VERSION ""

NS_ :

BS_:

BU_: PC PUMPOT DC_DC2 DC_DC1 TTC_30 IMU CANoeSpy MBMS VCU VCVCCU CBCU TMS

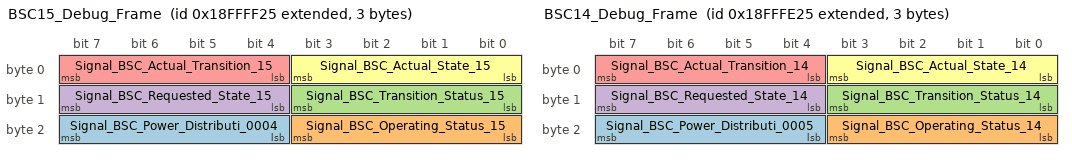
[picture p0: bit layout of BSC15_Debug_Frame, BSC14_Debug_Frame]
BO_ 2566913829 BSC15_Debug_Frame: 3 MBMS
 SG_ Signal_BSC_Power_Distributi_0004 : 20|4@1+ (1,0) [0|0] "" Vector__XXX
 SG_ Signal_BSC_Operating_Status_15 : 16|4@1+ (1,0) [0|0] "" Vector__XXX
 SG_ Signal_BSC_Transition_Status_15 : 8|4@1+ (1,0) [0|0] "" Vector__XXX
 SG_ Signal_BSC_Requested_State_15 : 12|4@1+ (1,0) [0|0] "" Vector__XXX
 SG_ Signal_BSC_Actual_Transition_15 : 4|4@1+ (1,0) [0|0] "" Vector__XXX
 SG_ Signal_BSC_Actual_State_15 : 0|4@1+ (1,0) [0|0] "" Vector__XXX

BO_ 2566913573 BSC14_Debug_Frame: 3 MBMS
 SG_ Signal_BSC_Power_Distributi_0005 : 20|4@1+ (1,0) [0|0] "" Vector__XXX
 SG_ Signal_BSC_Operating_Status_14 : 16|4@1+ (1,0) [0|0] "" Vector__XXX
 SG_ Signal_BSC_Transition_Status_14 : 8|4@1+ (1,0) [0|0] "" Vector__XXX
 SG_ Signal_BSC_Requested_State_14 : 12|4@1+ (1,0) [0|0] "" Vector__XXX
 SG_ Signal_BSC_Actual_Transition_14 : 4|4@1+ (1,0) [0|0] "" Vector__XXX
 SG_ Signal_BSC_Actual_State_14 : 0|4@1+ (1,0) [0|0] "" Vector__XXX

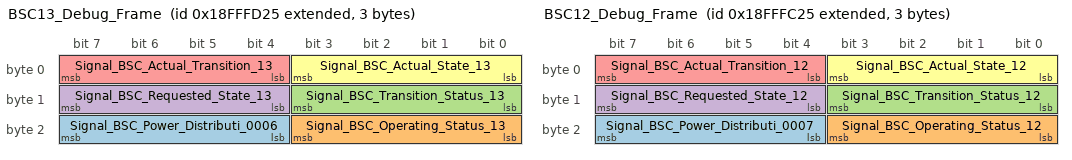
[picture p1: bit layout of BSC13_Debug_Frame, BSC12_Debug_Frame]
BO_ 2566913317 BSC13_Debug_Frame: 3 MBMS
 SG_ Signal_BSC_Power_Distributi_0006 : 20|4@1+ (1,0) [0|0] "" Vector__XXX
 SG_ Signal_BSC_Operating_Status_13 : 16|4@1+ (1,0) [0|0] "" Vector__XXX
 SG_ Signal_BSC_Transition_Status_13 : 8|4@1+ (1,0) [0|0] "" Vector__XXX
 SG_ Signal_BSC_Requested_State_13 : 12|4@1+ (1,0) [0|0] "" Vector__XXX
 SG_ Signal_BSC_Actual_Transition_13 : 4|4@1+ (1,0) [0|0] "" Vector__XXX
 SG_ Signal_BSC_Actual_State_13 : 0|4@1+ (1,0) [0|0] "" Vector__XXX

BO_ 2566913061 BSC12_Debug_Frame: 3 MBMS
 SG_ Signal_BSC_Power_Distributi_0007 : 20|4@1+ (1,0) [0|0] "" Vector__XXX
 SG_ Signal_BSC_Operating_Status_12 : 16|4@1+ (1,0) [0|0] "" Vector__XXX
 SG_ Signal_BSC_Transition_Status_12 : 8|4@1+ (1,0) [0|0] "" Vector__XXX
 SG_ Signal_BSC_Requested_State_12 : 12|4@1+ (1,0) [0|0] "" Vector__XXX
 SG_ Signal_BSC_Actual_Transition_12 : 4|4@1+ (1,0) [0|0] "" Vector__XXX
 SG_ Signal_BSC_Actual_State_12 : 0|4@1+ (1,0) [0|0] "" Vector__XXX

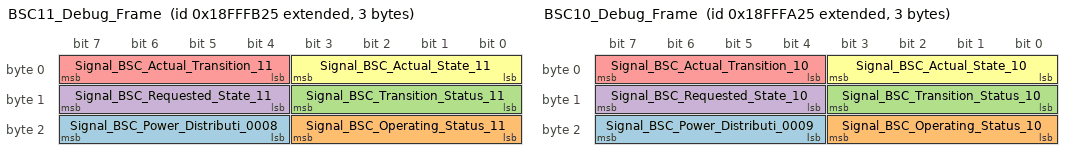
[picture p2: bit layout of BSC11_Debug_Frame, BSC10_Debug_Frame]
BO_ 2566912805 BSC11_Debug_Frame: 3 MBMS
 SG_ Signal_BSC_Power_Distributi_0008 : 20|4@1+ (1,0) [0|0] "" Vector__XXX
 SG_ Signal_BSC_Operating_Status_11 : 16|4@1+ (1,0) [0|0] "" Vector__XXX
 SG_ Signal_BSC_Transition_Status_11 : 8|4@1+ (1,0) [0|0] "" Vector__XXX
 SG_ Signal_BSC_Requested_State_11 : 12|4@1+ (1,0) [0|0] "" Vector__XXX
 SG_ Signal_BSC_Actual_Transition_11 : 4|4@1+ (1,0) [0|0] "" Vector__XXX
 SG_ Signal_BSC_Actual_State_11 : 0|4@1+ (1,0) [0|0] "" Vector__XXX

BO_ 2566912549 BSC10_Debug_Frame: 3 MBMS
 SG_ Signal_BSC_Power_Distributi_0009 : 20|4@1+ (1,0) [0|0] "" Vector__XXX
 SG_ Signal_BSC_Operating_Status_10 : 16|4@1+ (1,0) [0|0] "" Vector__XXX
 SG_ Signal_BSC_Transition_Status_10 : 8|4@1+ (1,0) [0|0] "" Vector__XXX
 SG_ Signal_BSC_Requested_State_10 : 12|4@1+ (1,0) [0|0] "" Vector__XXX
 SG_ Signal_BSC_Actual_Transition_10 : 4|4@1+ (1,0) [0|0] "" Vector__XXX
 SG_ Signal_BSC_Actual_State_10 : 0|4@1+ (1,0) [0|0] "" Vector__XXX

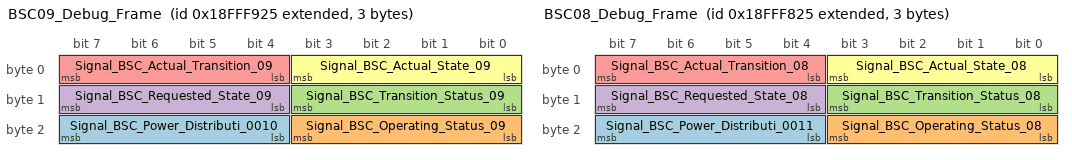
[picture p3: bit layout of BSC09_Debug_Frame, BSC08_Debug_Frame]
BO_ 2566912293 BSC09_Debug_Frame: 3 MBMS
 SG_ Signal_BSC_Power_Distributi_0010 : 20|4@1+ (1,0) [0|0] "" Vector__XXX
 SG_ Signal_BSC_Operating_Status_09 : 16|4@1+ (1,0) [0|0] "" Vector__XXX
 SG_ Signal_BSC_Transition_Status_09 : 8|4@1+ (1,0) [0|0] "" Vector__XXX
 SG_ Signal_BSC_Requested_State_09 : 12|4@1+ (1,0) [0|0] "" Vector__XXX
 SG_ Signal_BSC_Actual_Transition_09 : 4|4@1+ (1,0) [0|0] "" Vector__XXX
 SG_ Signal_BSC_Actual_State_09 : 0|4@1+ (1,0) [0|0] "" Vector__XXX

BO_ 2566912037 BSC08_Debug_Frame: 3 MBMS
 SG_ Signal_BSC_Power_Distributi_0011 : 20|4@1+ (1,0) [0|0] "" Vector__XXX
 SG_ Signal_BSC_Operating_Status_08 : 16|4@1+ (1,0) [0|0] "" Vector__XXX
 SG_ Signal_BSC_Transition_Status_08 : 8|4@1+ (1,0) [0|0] "" Vector__XXX
 SG_ Signal_BSC_Requested_State_08 : 12|4@1+ (1,0) [0|0] "" Vector__XXX
 SG_ Signal_BSC_Actual_Transition_08 : 4|4@1+ (1,0) [0|0] "" Vector__XXX
 SG_ Signal_BSC_Actual_State_08 : 0|4@1+ (1,0) [0|0] "" Vector__XXX

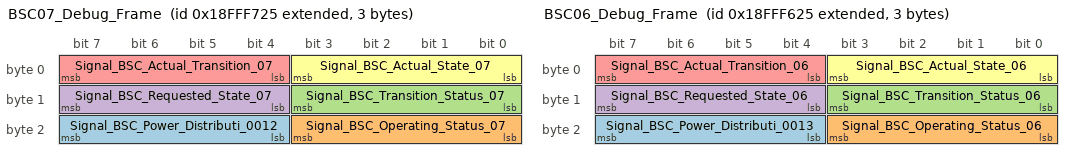
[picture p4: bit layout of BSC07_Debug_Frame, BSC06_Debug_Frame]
BO_ 2566911781 BSC07_Debug_Frame: 3 MBMS
 SG_ Signal_BSC_Power_Distributi_0012 : 20|4@1+ (1,0) [0|0] "" Vector__XXX
 SG_ Signal_BSC_Operating_Status_07 : 16|4@1+ (1,0) [0|0] "" Vector__XXX
 SG_ Signal_BSC_Transition_Status_07 : 8|4@1+ (1,0) [0|0] "" Vector__XXX
 SG_ Signal_BSC_Requested_State_07 : 12|4@1+ (1,0) [0|0] "" Vector__XXX
 SG_ Signal_BSC_Actual_Transition_07 : 4|4@1+ (1,0) [0|0] "" Vector__XXX
 SG_ Signal_BSC_Actual_State_07 : 0|4@1+ (1,0) [0|0] "" Vector__XXX

BO_ 2566911525 BSC06_Debug_Frame: 3 MBMS
 SG_ Signal_BSC_Power_Distributi_0013 : 20|4@1+ (1,0) [0|0] "" Vector__XXX
 SG_ Signal_BSC_Operating_Status_06 : 16|4@1+ (1,0) [0|0] "" Vector__XXX
 SG_ Signal_BSC_Transition_Status_06 : 8|4@1+ (1,0) [0|0] "" Vector__XXX
 SG_ Signal_BSC_Requested_State_06 : 12|4@1+ (1,0) [0|0] "" Vector__XXX
 SG_ Signal_BSC_Actual_Transition_06 : 4|4@1+ (1,0) [0|0] "" Vector__XXX
 SG_ Signal_BSC_Actual_State_06 : 0|4@1+ (1,0) [0|0] "" Vector__XXX

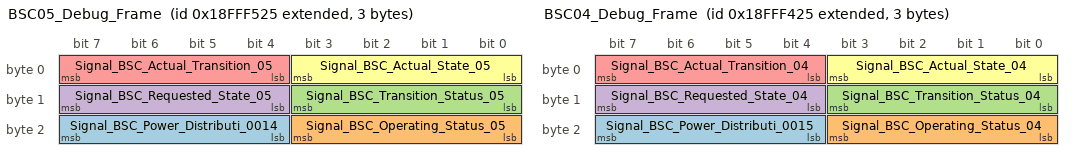
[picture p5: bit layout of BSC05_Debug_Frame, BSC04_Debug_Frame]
BO_ 2566911269 BSC05_Debug_Frame: 3 MBMS
 SG_ Signal_BSC_Power_Distributi_0014 : 20|4@1+ (1,0) [0|0] "" Vector__XXX
 SG_ Signal_BSC_Operating_Status_05 : 16|4@1+ (1,0) [0|0] "" Vector__XXX
 SG_ Signal_BSC_Transition_Status_05 : 8|4@1+ (1,0) [0|0] "" Vector__XXX
 SG_ Signal_BSC_Requested_State_05 : 12|4@1+ (1,0) [0|0] "" Vector__XXX
 SG_ Signal_BSC_Actual_Transition_05 : 4|4@1+ (1,0) [0|0] "" Vector__XXX
 SG_ Signal_BSC_Actual_State_05 : 0|4@1+ (1,0) [0|0] "" Vector__XXX

BO_ 2566911013 BSC04_Debug_Frame: 3 MBMS
 SG_ Signal_BSC_Power_Distributi_0015 : 20|4@1+ (1,0) [0|0] "" Vector__XXX
 SG_ Signal_BSC_Operating_Status_04 : 16|4@1+ (1,0) [0|0] "" Vector__XXX
 SG_ Signal_BSC_Transition_Status_04 : 8|4@1+ (1,0) [0|0] "" Vector__XXX
 SG_ Signal_BSC_Requested_State_04 : 12|4@1+ (1,0) [0|0] "" Vector__XXX
 SG_ Signal_BSC_Actual_Transition_04 : 4|4@1+ (1,0) [0|0] "" Vector__XXX
 SG_ Signal_BSC_Actual_State_04 : 0|4@1+ (1,0) [0|0] "" Vector__XXX

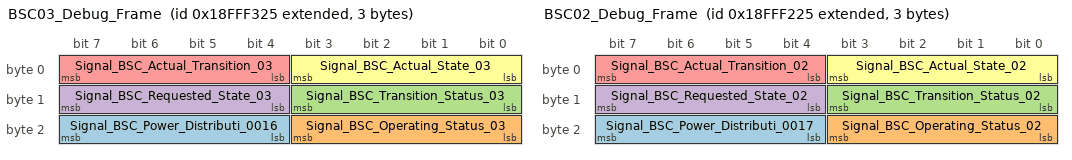
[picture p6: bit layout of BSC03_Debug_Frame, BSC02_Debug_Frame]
BO_ 2566910757 BSC03_Debug_Frame: 3 MBMS
 SG_ Signal_BSC_Power_Distributi_0016 : 20|4@1+ (1,0) [0|0] "" Vector__XXX
 SG_ Signal_BSC_Operating_Status_03 : 16|4@1+ (1,0) [0|0] "" Vector__XXX
 SG_ Signal_BSC_Transition_Status_03 : 8|4@1+ (1,0) [0|0] "" Vector__XXX
 SG_ Signal_BSC_Requested_State_03 : 12|4@1+ (1,0) [0|0] "" Vector__XXX
 SG_ Signal_BSC_Actual_Transition_03 : 4|4@1+ (1,0) [0|0] "" Vector__XXX
 SG_ Signal_BSC_Actual_State_03 : 0|4@1+ (1,0) [0|0] "" Vector__XXX

BO_ 2566910501 BSC02_Debug_Frame: 3 MBMS
 SG_ Signal_BSC_Power_Distributi_0017 : 20|4@1+ (1,0) [0|0] "" Vector__XXX
 SG_ Signal_BSC_Operating_Status_02 : 16|4@1+ (1,0) [0|0] "" Vector__XXX
 SG_ Signal_BSC_Transition_Status_02 : 8|4@1+ (1,0) [0|0] "" Vector__XXX
 SG_ Signal_BSC_Requested_State_02 : 12|4@1+ (1,0) [0|0] "" Vector__XXX
 SG_ Signal_BSC_Actual_Transition_02 : 4|4@1+ (1,0) [0|0] "" Vector__XXX
 SG_ Signal_BSC_Actual_State_02 : 0|4@1+ (1,0) [0|0] "" Vector__XXX

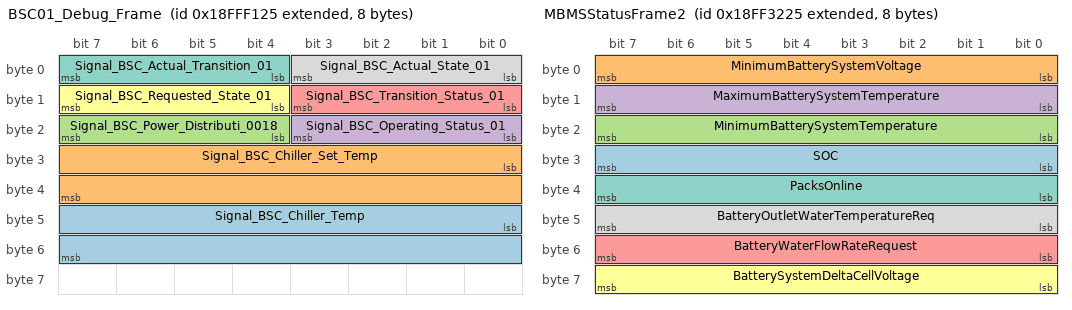
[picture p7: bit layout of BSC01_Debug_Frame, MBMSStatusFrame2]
BO_ 2566910245 BSC01_Debug_Frame: 8 MBMS
 SG_ Signal_BSC_Chiller_Temp : 40|16@1+ (1,0) [0|0] "" Vector__XXX
 SG_ Signal_BSC_Chiller_Set_Temp : 24|16@1+ (1,0) [0|0] "" Vector__XXX
 SG_ Signal_BSC_Power_Distributi_0018 : 20|4@1+ (1,0) [0|0] "" Vector__XXX
 SG_ Signal_BSC_Operating_Status_01 : 16|4@1+ (1,0) [0|0] "" Vector__XXX
 SG_ Signal_BSC_Transition_Status_01 : 8|4@1+ (1,0) [0|0] "" Vector__XXX
 SG_ Signal_BSC_Requested_State_01 : 12|4@1+ (1,0) [0|0] "" Vector__XXX
 SG_ Signal_BSC_Actual_Transition_01 : 4|4@1+ (1,0) [0|0] "" Vector__XXX
 SG_ Signal_BSC_Actual_State_01 : 0|4@1+ (1,0) [0|0] "" Vector__XXX

BO_ 2566861349 MBMSStatusFrame2: 8 MBMS
 SG_ SOC : 24|8@1+ (0.4,0) [0|100] "%" Vector__XXX
 SG_ MinimumBatterySystemVoltage : 0|8@1+ (3.4,0) [0|850] "V" Vector__XXX
 SG_ MinimumBatterySystemTemperature : 16|8@1+ (1,-40) [-40|210] "°C" Vector__XXX
 SG_ MaximumBatterySystemTemperature : 8|8@1+ (1,-40) [-40|210] "°C" Vector__XXX
 SG_ BatteryWaterFlowRateRequest : 48|8@1+ (50,0) [0|12500] "l/h" Vector__XXX
 SG_ BatterySystemDeltaCellVoltage : 56|8@1+ (10,0) [0|2500] "mV" Vector__XXX
 SG_ PacksOnline : 32|8@1+ (1,0) [0|250] "" Vector__XXX
 SG_ BatteryOutletWaterTemperatureReq : 40|8@1+ (1,-40) [-40|210] "°C" Vector__XXX

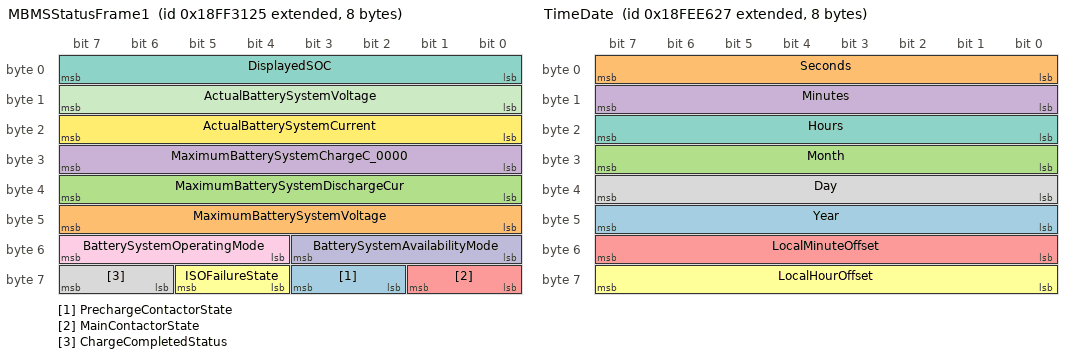
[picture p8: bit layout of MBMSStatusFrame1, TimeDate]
BO_ 2566861093 MBMSStatusFrame1: 8 MBMS
 SG_ PrechargeContactorState : 58|2@1+ (1,0) [0|0] "" Vector__XXX
 SG_ MaximumBatterySystemVoltage : 40|8@1+ (3.4,0) [0|850] "V" Vector__XXX
 SG_ MaximumBatterySystemDischargeCur : 32|8@1+ (2,0) [0|510] "A" Vector__XXX
 SG_ MaximumBatterySystemChargeC_0000 : 24|8@1+ (2,0) [0|510] "A" Vector__XXX
 SG_ MainContactorState : 56|2@1+ (1,0) [0|0] "" Vector__XXX
 SG_ ISOFailureState : 60|2@1+ (1,0) [0|0] "" Vector__XXX
 SG_ DisplayedSOC : 0|8@1+ (0.4,0) [0|100] "%" Vector__XXX
 SG_ ChargeCompletedStatus : 62|2@1+ (1,0) [0|0] "" Vector__XXX
 SG_ BatterySystemOperatingMode : 52|4@1+ (1,0) [0|0] "" Vector__XXX
 SG_ BatterySystemAvailabilityMode : 48|4@1+ (1,0) [0|0] "" Vector__XXX
 SG_ ActualBatterySystemVoltage : 8|8@1+ (3.4,0) [0|850] "V" Vector__XXX
 SG_ ActualBatterySystemCurrent : 16|8@1+ (4,-500) [-500|500] "A" Vector__XXX

BO_ 2566832423 HighResVehicleDistance: 8 Vector__XXX
 SG_ HighResTripDistance : 32|32@1+ (0.005,0) [0|21055406] ""  MBMS
 SG_ HighResTotalVehicleDistance : 0|32@1+ (0.005,0) [0|21055406] ""  MBMS

BO_ 2566841895 TimeDate: 8 Vector__XXX
 SG_ Year : 40|8@1+ (1,0) [0|250] ""  MBMS
 SG_ Seconds : 0|8@1+ (0.25,0) [0|62.5] ""  MBMS
 SG_ Month : 24|8@1+ (1,0) [0|250] ""  MBMS
 SG_ Minutes : 8|8@1+ (1,0) [0|250] ""  MBMS
 SG_ LocalMinuteOffset : 48|8@1+ (1,-125) [-125|130] ""  MBMS
 SG_ LocalHourOffset : 56|8@1+ (1,-125) [-125|130] ""  MBMS
 SG_ Hours : 16|8@1+ (1,0) [0|250] ""  MBMS
 SG_ Day : 32|8@1+ (0.25,0) [0|62.5] ""  MBMS

BO_ 2566856487 SCU2MBMS: 3 Vector__XXX
 SG_ PrechargeContactor : 0|2@1+ (1,0) [0|0] ""  MBMS
 SG_ MaxChargePower : 8|16@1+ (0.01,0) [0|655.35] "kW"  MBMS
 SG_ MainContactor : 2|2@1+ (1,0) [0|0] ""  MBMS

BO_ 2364609638 DCDC2VC: 8 DC_DC2
 SG_ HiSideCur : 48|16@1+ (0.1,-3212.7) [-3212.7|3212.8] "A" Vector__XXX
 SG_ HiSideV : 32|16@1+ (0.05,0) [0|3212.75] "V" Vector__XXX
 SG_ LowSideCur : 16|16@1+ (0.1,-3212.7) [-3212.7|3212.8] "A" Vector__XXX
 SG_ LowSideV : 0|16@1+ (0.01,0) [0|642.55] "V" Vector__XXX

BO_ 2365297510 DCDC2V: 8 DC_DC2
 SG_ OneCtrlInputSLIV : 16|16@1+ (0.05,0) [0|3212.75] "V" Vector__XXX
 SG_ OneCtrlInputIgntV : 0|16@1+ (0.05,0) [0|3212.75] "V" Vector__XXX

BO_ 2365315174 DCDC2T: 8 DC_DC2
 SG_ OneCoolantOutTemp : 32|8@1+ (1,-40) [-40|210] "°C" Vector__XXX
 SG_ OneCoolantInTemp : 24|8@1+ (1,-40) [-40|210] "°C" Vector__XXX
 SG_ PwrETemp : 16|8@1+ (1,-40) [-40|210] "°C" Vector__XXX
 SG_ ElectronicFilterTemp : 8|8@1+ (1,-40) [-40|210] "°C" Vector__XXX
 SG_ Temp : 0|8@1+ (1,-40) [-40|210] "°C" Vector__XXX

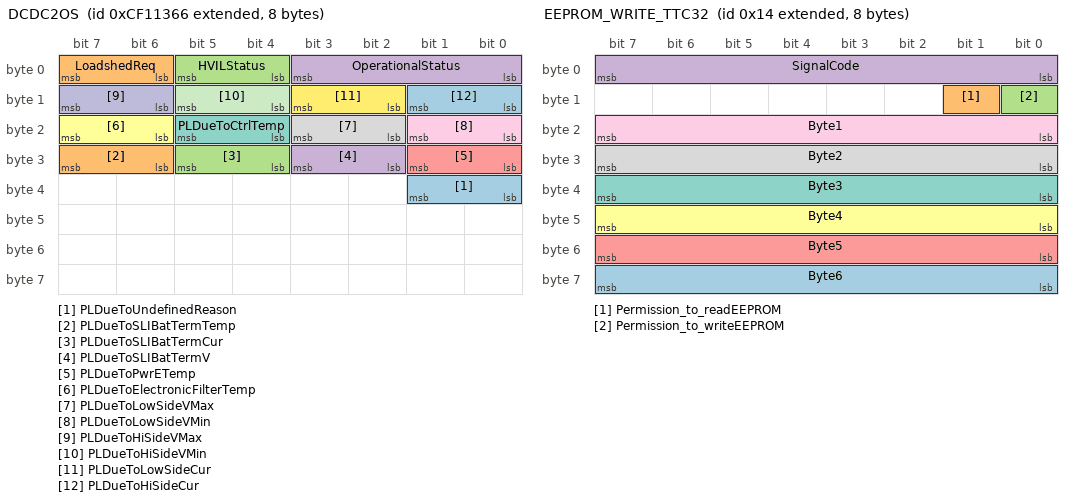
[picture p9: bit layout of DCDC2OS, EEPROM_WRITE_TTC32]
BO_ 2364609382 DCDC2OS: 8 DC_DC2
 SG_ PLDueToUndefinedReason : 32|2@1+ (1,0) [0|3] "" Vector__XXX
 SG_ PLDueToSLIBatTermTemp : 30|2@1+ (1,0) [0|3] "" Vector__XXX
 SG_ PLDueToSLIBatTermCur : 28|2@1+ (1,0) [0|3] "" Vector__XXX
 SG_ PLDueToSLIBatTermV : 26|2@1+ (1,0) [0|3] "" Vector__XXX
 SG_ PLDueToPwrETemp : 24|2@1+ (1,0) [0|3] "" Vector__XXX
 SG_ PLDueToElectronicFilterTemp : 22|2@1+ (1,0) [0|3] "" Vector__XXX
 SG_ PLDueToCtrlTemp : 20|2@1+ (1,0) [0|3] "" Vector__XXX
 SG_ PLDueToLowSideVMax : 18|2@1+ (1,0) [0|3] "" Vector__XXX
 SG_ PLDueToLowSideVMin : 16|2@1+ (1,0) [0|3] "" Vector__XXX
 SG_ PLDueToHiSideVMax : 14|2@1+ (1,0) [0|3] "" Vector__XXX
 SG_ PLDueToHiSideVMin : 12|2@1+ (1,0) [0|3] "" Vector__XXX
 SG_ PLDueToLowSideCur : 10|2@1+ (1,0) [0|3] "" Vector__XXX
 SG_ PLDueToHiSideCur : 8|2@1+ (1,0) [0|3] "" Vector__XXX
 SG_ LoadshedReq : 6|2@1+ (1,0) [0|3] "" Vector__XXX
 SG_ HVILStatus : 4|2@1+ (1,0) [0|3] "" Vector__XXX
 SG_ OperationalStatus : 0|4@1+ (1,0) [0|15] "" Vector__XXX

BO_ 2365315430 DCDC2LL: 8 DC_DC2
 SG_ LowSideCurMaxLmt : 32|16@1+ (0.05,0) [0|3212.75] "A" Vector__XXX
 SG_ LowSideVMaxLmt : 16|16@1+ (0.01,0) [0|642.55] "V" Vector__XXX
 SG_ LowSideVMinLmt : 0|16@1+ (0.01,0) [0|642.55] "V" Vector__XXX

BO_ 2348941054 Pant_current: 8 TTC_30
 SG_ Datchik_toka : 0|16@1+ (0.005,0) [0|0] "" Vector__XXX

BO_ 2147483800 EEPROM_WRITE_TTC32_2byte: 4 Vector__XXX
 SG_ Permission_to_readEEPROM : 9|1@1+ (1,0) [0|0] "" Vector__XXX
 SG_ Permission_to_writeEEPROM : 8|1@1+ (1,0) [0|0] "" Vector__XXX
 SG_ SignalCode : 0|8@1+ (1,0) [0|0] "" Vector__XXX
 SG_ Byte2 : 24|8@1+ (1,0) [0|0] "" Vector__XXX
 SG_ Byte1 : 16|8@1+ (1,0) [0|0] "" Vector__XXX

BO_ 2147483801 EEPROM_WRITE_TTC32_1byte: 3 Vector__XXX
 SG_ Permission_to_readEEPROM : 9|1@1+ (1,0) [0|0] "" Vector__XXX
 SG_ Permission_to_writeEEPROM : 8|1@1+ (1,0) [0|0] "" Vector__XXX
 SG_ SignalCode : 0|8@1+ (1,0) [0|0] "" Vector__XXX
 SG_ Byte1 : 16|8@1+ (1,0) [0|0] "" Vector__XXX

BO_ 2147483682 EEPROM_Global_values2_TTC32: 8 Vector__XXX
 SG_ var11 : 32|8@1+ (1,0) [0|0] "" Vector__XXX
 SG_ Idle_stop_circuit2_variable : 24|8@1+ (1,0) [0|0] "" Vector__XXX
 SG_ var8 : 16|8@1+ (1,0) [0|0] "" Vector__XXX
 SG_ var7 : 0|16@1+ (1,0) [0|0] "" Vector__XXX

BO_ 2147483681 EEPROM_Global_values1_TTC32: 8 Vector__XXX
 SG_ Idle_stop_circuit1_variable : 56|8@1+ (1,0) [0|0] "" Vector__XXX
 SG_ var6 : 32|24@1+ (1,0) [0|0] "" Vector__XXX
 SG_ saturation1_min_variable : 24|8@1+ (1,0) [0|0] "" Vector__XXX
 SG_ saturation2_min_variable : 16|8@1+ (1,0) [0|0] "" Vector__XXX
 SG_ saturation1_max_variable : 8|8@1+ (1,0) [0|0] "" Vector__XXX
 SG_ saturation2_max_variable : 0|8@1+ (1,0) [0|0] "" Vector__XXX

BO_ 2147483668 EEPROM_WRITE_TTC32: 8 Vector__XXX
 SG_ Byte6 : 56|8@1+ (1,0) [0|0] "" Vector__XXX
 SG_ Permission_to_readEEPROM : 9|1@1+ (1,0) [0|0] "" Vector__XXX
 SG_ Permission_to_writeEEPROM : 8|1@1+ (1,0) [0|0] "" Vector__XXX
 SG_ SignalCode : 0|8@1+ (1,0) [0|0] "" Vector__XXX
 SG_ Byte5 : 48|8@1+ (1,0) [0|0] "" Vector__XXX
 SG_ Byte4 : 40|8@1+ (1,0) [0|0] "" Vector__XXX
 SG_ Byte3 : 32|8@1+ (1,0) [0|0] "" Vector__XXX
 SG_ Byte2 : 24|8@1+ (1,0) [0|0] "" Vector__XXX
 SG_ Byte1 : 16|8@1+ (1,0) [0|0] "" Vector__XXX

BO_ 2147483667 EEPROM_Status_TTC32: 8 Vector__XXX
 SG_ bit10 : 9|1@1+ (1,0) [0|0] "" Vector__XXX
 SG_ bit11 : 10|1@1+ (1,0) [0|0] "" Vector__XXX
 SG_ bit12 : 11|1@1+ (1,0) [0|0] "" Vector__XXX
 SG_ bit13 : 12|1@1+ (1,0) [0|0] "" Vector__XXX
 SG_ bit14 : 13|1@1+ (1,0) [0|0] "" Vector__XXX
 SG_ bit15 : 14|1@1+ (1,0) [0|0] "" Vector__XXX
 SG_ bit16 : 15|1@1+ (1,0) [0|0] "" Vector__XXX
 SG_ bit17 : 16|1@1+ (1,0) [0|0] "" Vector__XXX
 SG_ bit18 : 17|1@1+ (1,0) [0|0] "" Vector__XXX
 SG_ bit19 : 18|1@1+ (1,0) [0|0] "" Vector__XXX
 SG_ bit20 : 19|1@1+ (1,0) [0|0] "" Vector__XXX
 SG_ bit3 : 2|1@1+ (1,0) [0|0] "" Vector__XXX
 SG_ bit4 : 3|1@1+ (1,0) [0|0] "" Vector__XXX
 SG_ bit5 : 4|1@1+ (1,0) [0|0] "" Vector__XXX
 SG_ bit6 : 5|1@1+ (1,0) [0|0] "" Vector__XXX
 SG_ bit7 : 6|1@1+ (1,0) [0|0] "" Vector__XXX
 SG_ bit8 : 7|1@1+ (1,0) [0|0] "" Vector__XXX
 SG_ bit9 : 8|1@1+ (1,0) [0|0] "" Vector__XXX
 SG_ bit2 : 1|1@1+ (1,0) [0|0] "" Vector__XXX
 SG_ bit1 : 0|1@1+ (1,0) [0|0] "" Vector__XXX

BO_ 2566874233 EEPROM_Current_values2_TTC32: 8 Vector__XXX
 SG_ status : 0|8@1+ (1,0) [0|0] "" Vector__XXX
 SG_ DelayPantRising : 16|8@1+ (1,0) [0|0] "" Vector__XXX
 SG_ state : 8|8@1+ (1,0) [0|0] "" Vector__XXX

BO_ 2147483673 EEPROM_Current_values1_TTC32: 8 Vector__XXX
 SG_ SOC_Pant : 48|16@1+ (1,0) [0|0] "" Vector__XXX
 SG_ Down_Speed : 32|16@1+ (1,0) [0|0] "" Vector__XXX
 SG_ Up_Lim_beforeMid : 16|16@1+ (1,0) [0|0] "" Vector__XXX
 SG_ Up_Lim_afterMid : 0|16@1+ (1,0) [0|0] "" Vector__XXX

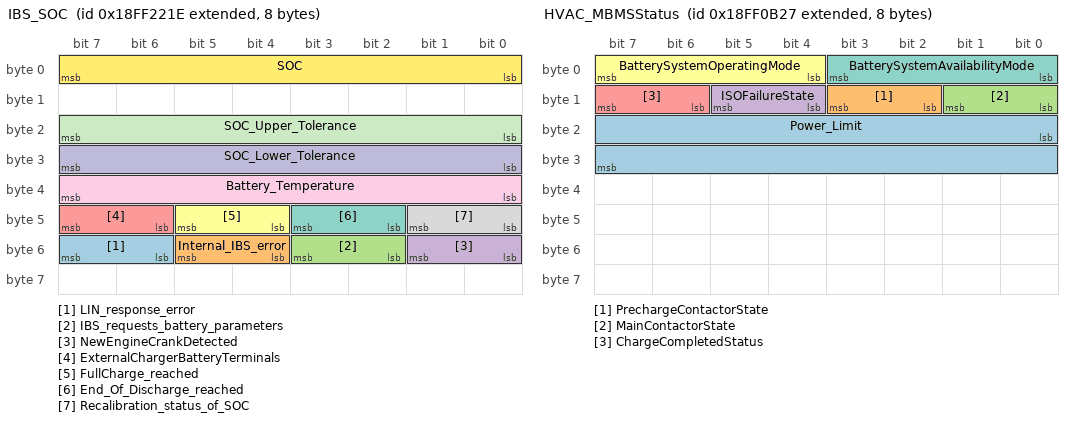
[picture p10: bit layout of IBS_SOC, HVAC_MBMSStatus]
BO_ 2566857246 IBS_SOC: 8 VCU
 SG_ LIN_response_error : 54|2@1+ (1,0) [0|0] ""  DC_DC2,DC_DC1
 SG_ Internal_IBS_error : 52|2@1+ (1,0) [0|0] ""  DC_DC2,DC_DC1
 SG_ IBS_requests_battery_parameters : 50|2@1+ (1,0) [0|0] ""  DC_DC2,DC_DC1
 SG_ NewEngineCrankDetected : 48|2@1+ (1,0) [0|0] ""  DC_DC2,DC_DC1
 SG_ ExternalChargerBatteryTerminals : 46|2@1+ (1,0) [0|0] ""  DC_DC2,DC_DC1
 SG_ FullCharge_reached : 44|2@1+ (1,0) [0|0] ""  DC_DC2,DC_DC1
 SG_ End_Of_Discharge_reached : 42|2@1+ (1,0) [0|0] ""  DC_DC2,DC_DC1
 SG_ Recalibration_status_of_SOC : 40|2@1+ (1,0) [0|0] ""  DC_DC2,DC_DC1
 SG_ Battery_Temperature : 32|8@1- (1,-40) [-40|0] ""  DC_DC2,DC_DC1
 SG_ SOC_Lower_Tolerance : 24|8@1+ (1,0) [0|0] ""  DC_DC2,DC_DC1
 SG_ SOC_Upper_Tolerance : 16|8@1+ (1,0) [0|0] ""  DC_DC2,DC_DC1
 SG_ SOC : 0|8@1+ (0.4,0) [0|100] "%"  DC_DC2,DC_DC1

BO_ 2566856990 IBS_Data: 8 VCU
 SG_ Current_measurement_range : 56|3@1+ (1,0) [0|0] ""  DC_DC2,DC_DC1
 SG_ NTC_Temperature : 48|8@1- (1,-40) [0|0] ""  DC_DC2,DC_DC1
 SG_ CentreTapVoltage : 32|16@1+ (0.001,0) [0|32] ""  DC_DC2,DC_DC1
 SG_ BatteryVoltage : 16|16@1+ (0.001,0) [0|32] ""  DC_DC2,DC_DC1
 SG_ BatteryCurrent : 0|16@1- (0.05,-1600) [-1600|1600] ""  DC_DC2,DC_DC1

BO_ 2365526823 DC_DC2_Limit: 8 VCU
 SG_ Low_Side_Cur_Buck_Def_Setpoint : 40|16@1+ (0.1,0) [0|6425.5] ""  DC_DC2
 SG_ Low_Side_Current_Buck_Setpoint : 8|16@1- (0.1,0) [0|6425.5] ""  DC_DC2
 SG_ Current_Limit : 24|16@1+ (0.1,0) [0|0] ""  DC_DC2

BO_ 2365526567 DC_DC1_Limit: 8 VCU
 SG_ Low_Side_Cur_Buck_Def_Setpoint : 40|16@1+ (0.1,0) [0|6425.5] ""  DC_DC1
 SG_ Low_Side_Current_Buck_Setpoint : 8|16@1- (0.1,0) [0|6425.5] ""  DC_DC1
 SG_ Current_Limit : 24|16@1+ (0.1,0) [0|0] ""  DC_DC1

BO_ 2566851367 HVAC_MBMSStatus: 8 VCU
 SG_ Power_Limit : 16|16@1+ (0.5,0) [0|0] "" Vector__XXX
 SG_ PrechargeContactorState : 10|2@1+ (1,0) [0|0] "" Vector__XXX
 SG_ MainContactorState : 8|2@1+ (1,0) [0|0] "" Vector__XXX
 SG_ ISOFailureState : 12|2@1+ (1,0) [0|0] "" Vector__XXX
 SG_ ChargeCompletedStatus : 14|2@1+ (1,0) [0|0] "" Vector__XXX
 SG_ BatterySystemOperatingMode : 4|4@1+ (1,0) [0|0] "" Vector__XXX
 SG_ BatterySystemAvailabilityMode : 0|4@1+ (1,0) [0|0] "" Vector__XXX

BO_ 2365297509 DCDC1V: 8 DC_DC1
 SG_ OneCtrlInputSLIV : 16|16@1+ (0.05,0) [0|3212.75] "V"  VCU
 SG_ OneCtrlInputIgntV : 0|16@1+ (0.05,0) [0|3212.75] "V"  VCU

BO_ 2364610599 DCDC2C: 8 VCU
 SG_ TwoLowSideVBuckDefaultSetpoint : 40|16@1+ (0.01,0) [0|642.55] "V"  DC_DC2
 SG_ TwoHiSideVBoostSetpoint : 24|16@1+ (0.05,0) [0|3212.75] "V"  DC_DC2
 SG_ TwoLowSideVBuckSetpoint : 8|16@1+ (0.01,0) [0|642.55] "V"  DC_DC2
 SG_ TwoOperationalCmd : 0|4@1+ (1,0) [0|15] ""  DC_DC2

BO_ 2365315429 DCDC1LL: 8 DC_DC1
 SG_ LowSideCurMaxLmt : 32|16@1+ (0.05,0) [0|3212.75] "A"  VCU
 SG_ LowSideVMaxLmt : 16|16@1+ (0.01,0) [0|642.55] "V"  VCU
 SG_ LowSideVMinLmt : 0|16@1+ (0.01,0) [0|642.55] "V"  VCU

BO_ 2365315173 DCDC1T: 8 DC_DC1
 SG_ OneCoolantOutTemp : 32|8@1+ (1,-40) [-40|210] "°C"  VCU
 SG_ OneCoolantInTemp : 24|8@1+ (1,-40) [-40|210] "°C"  VCU
 SG_ PwrETemp : 16|8@1+ (1,-40) [-40|210] "°C"  VCU
 SG_ ElectronicFilterTemp : 8|8@1+ (1,-40) [-40|210] "°C"  VCU
 SG_ Temp : 0|8@1+ (1,-40) [-40|210] "°C"  VCU

BO_ 2364609637 DCDC1VC: 8 DC_DC1
 SG_ HiSideCur : 48|16@1+ (0.1,-3212.7) [-3212.7|3212.8] "A"  VCU
 SG_ HiSideV : 32|16@1+ (0.05,0) [0|3212.75] "V"  VCU
 SG_ LowSideCur : 16|16@1+ (0.1,-3212.7) [-3212.7|3212.8] "A"  VCU
 SG_ LowSideV : 0|16@1+ (0.01,0) [0|642.55] "V"  VCU

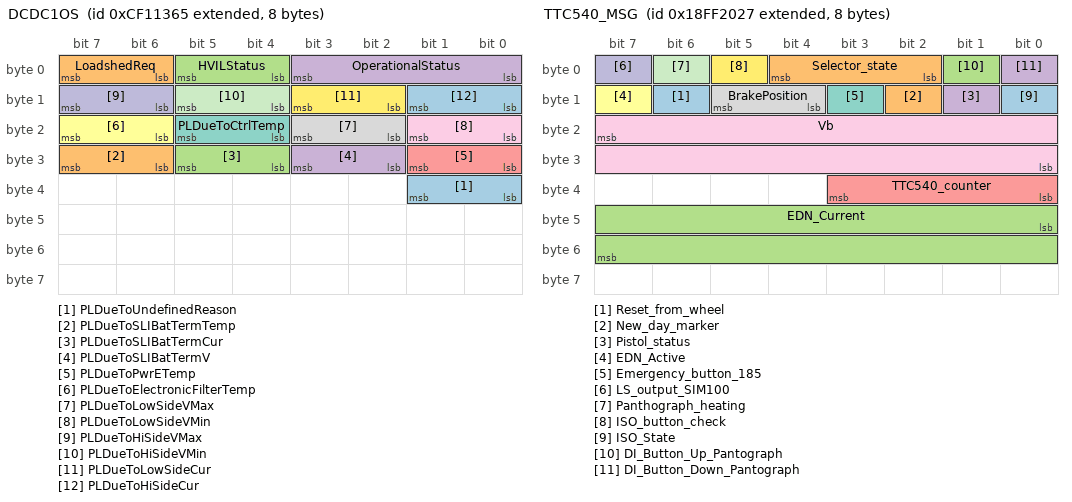
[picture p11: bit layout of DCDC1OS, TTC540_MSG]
BO_ 2364609381 DCDC1OS: 8 DC_DC1
 SG_ PLDueToUndefinedReason : 32|2@1+ (1,0) [0|3] ""  VCU
 SG_ PLDueToSLIBatTermTemp : 30|2@1+ (1,0) [0|3] ""  VCU
 SG_ PLDueToSLIBatTermCur : 28|2@1+ (1,0) [0|3] ""  VCU
 SG_ PLDueToSLIBatTermV : 26|2@1+ (1,0) [0|3] ""  VCU
 SG_ PLDueToPwrETemp : 24|2@1+ (1,0) [0|3] ""  VCU
 SG_ PLDueToElectronicFilterTemp : 22|2@1+ (1,0) [0|3] ""  VCU
 SG_ PLDueToCtrlTemp : 20|2@1+ (1,0) [0|3] ""  VCU
 SG_ PLDueToLowSideVMax : 18|2@1+ (1,0) [0|3] ""  VCU
 SG_ PLDueToLowSideVMin : 16|2@1+ (1,0) [0|3] ""  VCU
 SG_ PLDueToHiSideVMax : 14|2@1+ (1,0) [0|3] ""  VCU
 SG_ PLDueToHiSideVMin : 12|2@1+ (1,0) [0|3] ""  VCU
 SG_ PLDueToLowSideCur : 10|2@1+ (1,0) [0|3] ""  VCU
 SG_ PLDueToHiSideCur : 8|2@1+ (1,0) [0|3] ""  VCU
 SG_ LoadshedReq : 6|2@1+ (1,0) [0|3] ""  VCU
 SG_ HVILStatus : 4|2@1+ (1,0) [0|3] ""  VCU
 SG_ OperationalStatus : 0|4@1+ (1,0) [0|15] ""  VCU

BO_ 2364609063 DCDC1C: 8 VCU
 SG_ OneLowSideVBuckDefaultSetpoint : 40|16@1+ (0.01,0) [0|642.55] "V"  DC_DC1
 SG_ HiSideVBoostSetpoint : 24|16@1+ (0.05,0) [0|3212.75] "V"  DC_DC1
 SG_ LowSideVBuckSetpoint : 8|16@1+ (0.01,0) [0|642.55] "V"  DC_DC1
 SG_ OperationalCmd : 0|4@1+ (1,0) [0|15] ""  DC_DC1

BO_ 2566856743 TTC540_MSG: 8 VCU
 SG_ Reset_from_wheel : 14|1@1+ (1,0) [0|1] "" Vector__XXX
 SG_ New_day_marker : 10|1@1+ (1,0) [0|1] "" Vector__XXX
 SG_ EDN_Current : 40|16@1+ (0.1,0) [0|0] "" Vector__XXX
 SG_ Pistol_status : 9|1@1+ (1,0) [0|0] "" Vector__XXX
 SG_ TTC540_counter : 32|4@1+ (1,0) [0|0] "" Vector__XXX
 SG_ EDN_Active : 15|1@1+ (1,0) [0|0] "" Vector__XXX
 SG_ Emergency_button_185 : 11|1@1+ (1,0) [0|0] "" Vector__XXX
 SG_ BrakePosition : 12|2@1+ (1,0) [0|0] "" Vector__XXX
 SG_ Vb : 23|16@0+ (1,0) [0|0] "V" Vector__XXX
 SG_ LS_output_SIM100 : 7|1@1+ (1,0) [0|1] "" Vector__XXX
 SG_ Panthograph_heating : 6|1@1+ (1,0) [0|1] "" Vector__XXX
 SG_ ISO_button_check : 5|1@1+ (1,0) [0|0] "" Vector__XXX
 SG_ ISO_State : 8|1@1+ (1,0) [0|0] "" Vector__XXX
 SG_ Selector_state : 2|3@1+ (1,0) [0|0] "" Vector__XXX
 SG_ DI_Button_Up_Pantograph : 1|1@1+ (1,0) [0|1] ""  TTC_30
 SG_ DI_Button_Down_Pantograph : 0|1@1+ (1,0) [0|1] ""  TTC_30

BO_ 2566856723 TTC30_MSG: 8 TTC_30
 SG_ Power_charging_station : 48|16@1+ (1,0) [0|65535] "" Vector__XXX
 SG_ TTC30_counter : 44|4@1+ (1,0) [0|15] "" Vector__XXX
 SG_ UnderCoolant_HV_battery : 43|1@1+ (1,0) [0|0] "" Vector__XXX
 SG_ Charging_mode : 30|2@1+ (1,0) [0|0] "" Vector__XXX
 SG_ VCVCCU_Curr_demand : 42|1@1+ (1,0) [0|0] "" Vector__XXX
 SG_ VCVCCU_Vehicle_ContactorVoltage : 32|10@1+ (1,0) [0|1023] "V" Vector__XXX
 SG_ VC_VCCU_Connect : 0|1@1+ (1,0) [0|1] "" Vector__XXX
 SG_ Power_Ger : 1|1@1+ (1,0) [0|1] "" Vector__XXX
 SG_ Res_Chk_Stat : 7|1@1+ (1,0) [0|1] "" Vector__XXX
 SG_ Fbk_J2_PDU1_minus : 29|1@1+ (1,0) [0|1] "" Vector__XXX
 SG_ Fbk_K2_PDU1_plus : 28|1@1+ (1,0) [0|1] "" Vector__XXX
 SG_ Fbk_H2_HVIL : 27|1@1+ (1,0) [0|1] "" Vector__XXX
 SG_ Fbk_H4_PDU2_plus : 26|1@1+ (1,0) [0|255] "" Vector__XXX
 SG_ Fbk_G4_PDU2_Minus : 25|1@1+ (1,0) [0|1] "" Vector__XXX
 SG_ Fbk_F4_Discharge : 24|1@1+ (1,0) [0|1] "" Vector__XXX
 SG_ Voltage_PIN_A4 : 8|16@1+ (1,0) [0|65535] "" Vector__XXX
 SG_ DI_K2_Goes_down : 6|1@1+ (1,0) [0|1] ""  VCU
 SG_ DI_K1_Goes_up : 5|1@1+ (1,0) [0|1] ""  VCU
 SG_ Pantograph_DI_Top_Indicator : 4|1@1+ (1,0) [0|1] ""  VCU
 SG_ Pantograph_DI_Mid_Indicator : 3|1@1+ (1,0) [0|1] ""  VCU
 SG_ Pantograph_DI_Bottom_Indicator : 2|1@1+ (1,0) [0|1] ""  VCU

BO_ 2316304641 Request_from_Host: 5 VCU
 SG_ Restart m193 : 8|32@1+ (1,0) [0|0] "" Vector__XXX
 SG_ Excitation_pulse_off m98 : 8|32@1+ (1,0) [0|0] "" Vector__XXX
 SG_ Max_battery_working_voltage m240 : 15|16@0+ (1,0) [0|0] "V" Vector__XXX
 SG_ Request_mux M : 7|8@0+ (1,0) [0|0] "" Vector__XXX

BO_ 2316304640 SIM100_Report: 8 IMU
 SG_ Max_battery_working_voltage m240 : 15|16@0+ (1,0) [0|0] "V" Vector__XXX
 SG_ Temperature m128 : 15|32@0- (1,0) [0|0] "mCelsius" Vector__XXX
 SG_ Serial_number_3 m11 : 8|32@1+ (1,0) [0|0] "" Vector__XXX
 SG_ Serial_number_2 m10 : 8|32@1+ (1,0) [0|0] "" Vector__XXX
 SG_ Serial_number_1 m9 : 8|32@1+ (1,0) [0|0] "" Vector__XXX
 SG_ Serial_number_0 m8 : 8|32@1+ (1,0) [0|0] "" Vector__XXX
 SG_ Version_2 m7 : 8|32@1+ (1,0) [0|0] "" Vector__XXX
 SG_ Version_1 m6 : 8|32@1+ (1,0) [0|0] "" Vector__XXX
 SG_ Version_0 m5 : 8|32@1+ (1,0) [0|0] "" Vector__XXX
 SG_ Part_name_3 m4 : 8|32@1+ (1,0) [0|0] "" Vector__XXX
 SG_ Part_name_2 m3 : 8|32@1+ (1,0) [0|0] "" Vector__XXX
 SG_ Part_name_1 m2 : 8|32@1+ (1,0) [0|0] "" Vector__XXX
 SG_ Hardware_Error m224 : 15|1@0+ (1,0) [0|0] "" Vector__XXX
 SG_ Part_name_0 m1 : 8|32@1+ (1,0) [0|0] "" Vector__XXX
 SG_ Err_CH m229 : 21|1@0+ (1,0) [0|0] "" Vector__XXX
 SG_ No_New_Estimates m224 : 14|1@0+ (1,0) [0|0] "" Vector__XXX
 SG_ High_Uncertaintly m224 : 13|1@0+ (1,0) [0|0] "" Vector__XXX
 SG_ High_Battery_Voltage m224 : 11|1@0+ (1,0) [0|0] "" Vector__XXX
 SG_ Low_Battery_Voltage m224 : 10|1@0+ (1,0) [0|0] "" Vector__XXX
 SG_ Isolation_status_bits m224 : 9|2@0+ (1,0) [0|0] "" Vector__XXX
 SG_ Err_Vpwr m229 : 18|1@0+ (1,0) [0|0] "" Vector__XXX
 SG_ Err_Vexi m229 : 19|1@0+ (1,0) [0|0] "" Vector__XXX
 SG_ Err_VxR m229 : 20|1@0+ (1,0) [0|0] "" Vector__XXX
 SG_ Err_Vx1 m229 : 22|1@0+ (1,0) [0|0] "" Vector__XXX
 SG_ Err_Vx2 m229 : 23|1@0+ (1,0) [0|0] "" Vector__XXX
 SG_ Vb_max_uncertainty m228 : 63|8@0+ (1,0) [0|0] "%" Vector__XXX
 SG_ Vb_max m228 : 47|16@0+ (1,0) [0|0] "V" Vector__XXX
 SG_ Vb_uncertainty m228 : 39|8@0+ (1,0) [0|0] "%" Vector__XXX
 SG_ Vb m228 : 23|16@0+ (1,0) [0|0] "V" Vector__XXX
 SG_ Vn_uncertainty m227 : 63|8@0- (1,0) [0|0] "%" Vector__XXX
 SG_ Vn m227 : 47|16@0- (1,0) [0|0] "V" Vector__XXX
 SG_ Vp_uncertainty m227 : 39|8@0- (1,0) [0|0] "%" Vector__XXX
 SG_ Vp m227 : 23|16@0- (1,0) [0|0] "V" Vector__XXX
 SG_ Cn_uncertainty m226 : 63|8@0+ (1,0) [0|0] "%" Vector__XXX
 SG_ Cn m226 : 47|16@0+ (1,0) [0|0] "nF" Vector__XXX
 SG_ Cp_uncertainty m226 : 39|8@0+ (1,0) [0|0] "%" Vector__XXX
 SG_ Cp m226 : 23|16@0+ (1,0) [0|0] "nF" Vector__XXX
 SG_ Rn_uncertainty m225 : 63|8@0+ (1,0) [0|0] "" Vector__XXX
 SG_ Rn m225 : 47|16@0+ (1,0) [0|0] "kOhm" Vector__XXX
 SG_ Rp_uncertainty m225 : 39|8@0+ (1,0) [0|0] "%" Vector__XXX
 SG_ Rp m225 : 23|16@0+ (1,0) [0|0] "kOhm" Vector__XXX
 SG_ Energy_stored_uncertainty m224 : 63|8@0+ (1,0) [0|0] "%" Vector__XXX
 SG_ Energy_stored m224 : 47|16@0+ (1,0) [0|0] "mJ" Vector__XXX
 SG_ Electrical_isolation_uncertainty m224 : 39|8@0+ (1,0) [0|0] "%" Vector__XXX
 SG_ Electrical_isolation m224 : 23|16@0+ (1,0) [0|0] "Ohm/V" Vector__XXX
 SG_ OpCode_mux M : 7|8@0+ (1,0) [0|0] "" Vector__XXX

BO_ 2566855296 VCVCCU_InletStatus2: 8 VCVCCU
 SG_ VCVCCU_PlugPresent_Voltage : 0|16@1+ (1,0) [0|65533] "mV"  VCU

BO_ 2566855040 VCVCCU_InternalVoltageRawValues: 8 VCVCCU
 SG_ VCVCCU_Internal_VCC_SS_Raw : 48|16@1+ (1,0) [0|65533] ""  VCU
 SG_ VCVCCU_Internal_VCC_KL30_Raw : 32|16@1+ (1,0) [0|65533] ""  VCU
 SG_ VCVCCU_Internal_VCC_KL15_Raw : 16|16@1+ (1,0) [0|65533] ""  VCU
 SG_ VCVCCU_Internal_VCC_12V_Raw : 0|16@1+ (1,0) [0|65533] ""  VCU

BO_ 2566854784 VCVCCU_InternalVoltageStatus: 8 VCVCCU
 SG_ VCVCCU_Internal_VCC_SS_Voltage : 32|16@1+ (1,0) [0|65533] "mV"  VCU
 SG_ VCVCCU_Internal_VCC_KL30_Voltage : 48|16@1+ (1,0) [0|65533] "mV"  VCU
 SG_ VCVCCU_Internal_VCC_KL15_Voltage : 16|16@1+ (1,0) [0|65533] "mV"  VCU
 SG_ VCVCCU_Internal_VCC_12V_Voltage : 0|16@1+ (1,0) [0|65533] "mV"  VCU

BO_ 2566865026 VCVCCU_V2G_DepartureTime: 5 VCU
 SG_ VCVCCU_V2G_DepartureTimeFlag : 32|8@1+ (1,0) [0|0] ""  VCVCCU
 SG_ VCVCCU_V2G_DepartureTime_Value : 0|32@1+ (1,0) [0|0] ""  VCVCCU

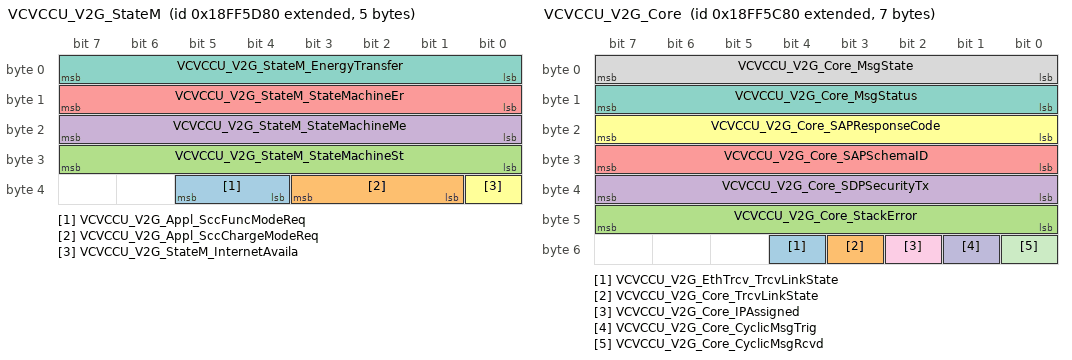
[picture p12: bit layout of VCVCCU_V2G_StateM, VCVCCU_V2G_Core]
BO_ 2566872448 VCVCCU_V2G_StateM: 5 VCVCCU
 SG_ VCVCCU_V2G_Appl_SccFuncModeReq : 36|2@1+ (1,0) [0|3] ""  VCU
 SG_ VCVCCU_V2G_Appl_SccChargeModeReq : 33|3@1+ (1,0) [0|6] ""  VCU
 SG_ VCVCCU_V2G_StateM_StateMachineSt : 24|8@1+ (1,0) [0|0] ""  VCU
 SG_ VCVCCU_V2G_StateM_StateMachineMe : 16|8@1+ (1,0) [0|0] ""  VCU
 SG_ VCVCCU_V2G_StateM_StateMachineEr : 8|8@1+ (1,0) [0|0] ""  VCU
 SG_ VCVCCU_V2G_StateM_InternetAvaila : 32|1@1+ (1,0) [0|0] ""  VCU
 SG_ VCVCCU_V2G_StateM_EnergyTransfer : 0|8@1+ (1,0) [0|0] ""  VCU

BO_ 2566872192 VCVCCU_V2G_Core: 7 VCVCCU
 SG_ VCVCCU_V2G_EthTrcv_TrcvLinkState : 52|1@1+ (1,0) [0|0] ""  VCU
 SG_ VCVCCU_V2G_Core_TrcvLinkState : 51|1@1+ (1,0) [0|0] ""  VCU
 SG_ VCVCCU_V2G_Core_StackError : 40|8@1+ (1,0) [0|0] ""  VCU
 SG_ VCVCCU_V2G_Core_SDPSecurityTx : 32|8@1+ (1,0) [0|0] ""  VCU
 SG_ VCVCCU_V2G_Core_SAPSchemaID : 24|8@1+ (1,0) [0|0] ""  VCU
 SG_ VCVCCU_V2G_Core_SAPResponseCode : 16|8@1+ (1,0) [0|0] ""  VCU
 SG_ VCVCCU_V2G_Core_MsgStatus : 8|8@1+ (1,0) [0|0] ""  VCU
 SG_ VCVCCU_V2G_Core_MsgState : 0|8@1+ (1,0) [0|0] ""  VCU
 SG_ VCVCCU_V2G_Core_IPAssigned : 50|1@1+ (1,0) [0|0] ""  VCU
 SG_ VCVCCU_V2G_Core_CyclicMsgTrig : 49|1@1+ (1,0) [0|0] ""  VCU
 SG_ VCVCCU_V2G_Core_CyclicMsgRcvd : 48|1@1+ (1,0) [0|0] ""  VCU

BO_ 2566871680 VCVCCU_V2G_EVSEPresentVoltage: 5 VCVCCU
 SG_ VCVCCU_V2G_EVSEPresentVoltage_Un : 0|4@1+ (1,0) [0|0] ""  VCU
 SG_ VCVCCU_V2G_EVSEPresentVolta_0000 : 32|8@1+ (1,0) [0|0] ""  VCU
 SG_ VCVCCU_V2G_EVSEPresentVoltage_Mu : 8|8@1- (1,0) [0|0] ""  VCU
 SG_ VCVCCU_V2G_EVSEPresentVoltage_Va : 16|16@1- (1,0) [0|0] ""  VCU

BO_ 2566871936 VCVCCU_V2G_DateTimeNow: 8 VCVCCU
 SG_ VCVCCU_V2G_DateTimeNow : 0|64@1- (1,0) [0|0] ""  VCU

BO_ 2566871424 VCVCCU_V2G_EVSEPresentCurrent: 5 VCVCCU
 SG_ VCVCCU_V2G_EVSEPresentCurrent_Un : 0|4@1+ (1,0) [0|0] ""  VCU
 SG_ VCVCCU_V2G_EVSEPresentCurre_0000 : 32|8@1+ (1,0) [0|0] ""  VCU
 SG_ VCVCCU_V2G_EVSEPresentCurrent_Mu : 8|8@1- (1,0) [0|0] ""  VCU
 SG_ VCVCCU_V2G_EVSEPresentCurrent_Va : 16|16@1- (1,0) [0|0] ""  VCU

BO_ 2566871168 VCVCCU_V2G_EVSEPeakCurrentRipple: 5 VCVCCU
 SG_ VCVCCU_V2G_EVSEPeakCurrentRipple : 0|4@1+ (1,0) [0|0] ""  VCU
 SG_ VCVCCU_V2G_EVSEPeakCurrentR_0000 : 32|8@1+ (1,0) [0|0] ""  VCU
 SG_ VCVCCU_V2G_EVSEPeakCurrentR_0001 : 8|8@1- (1,0) [0|0] ""  VCU
 SG_ VCVCCU_V2G_EVSEPeakCurrentR_0002 : 16|16@1- (1,0) [0|0] ""  VCU

BO_ 2566870912 VCVCCU_V2G_EVSEMinimumVoltageLim: 5 VCVCCU
 SG_ VCVCCU_V2G_EVSEMinimumVoltageLim : 0|4@1+ (1,0) [0|0] ""  VCU
 SG_ VCVCCU_V2G_EVSEMinimumVolta_0000 : 32|8@1+ (1,0) [0|0] ""  VCU
 SG_ VCVCCU_V2G_EVSEMinimumVolta_0001 : 8|8@1- (1,0) [0|0] ""  VCU
 SG_ VCVCCU_V2G_EVSEMinimumVolta_0002 : 16|16@1- (1,0) [0|0] ""  VCU

BO_ 2566870656 VCVCCU_V2G_EVSEMinimumCurrentLim: 5 VCVCCU
 SG_ VCVCCU_V2G_EVSEMinimumCurrentLim : 0|4@1+ (1,0) [0|0] ""  VCU
 SG_ VCVCCU_V2G_EVSEMinimumCurre_0000 : 32|8@1+ (1,0) [0|0] ""  VCU
 SG_ VCVCCU_V2G_EVSEMinimumCurre_0001 : 8|8@1- (1,0) [0|0] ""  VCU
 SG_ VCVCCU_V2G_EVSEMinimumCurre_0002 : 16|16@1- (1,0) [0|0] ""  VCU

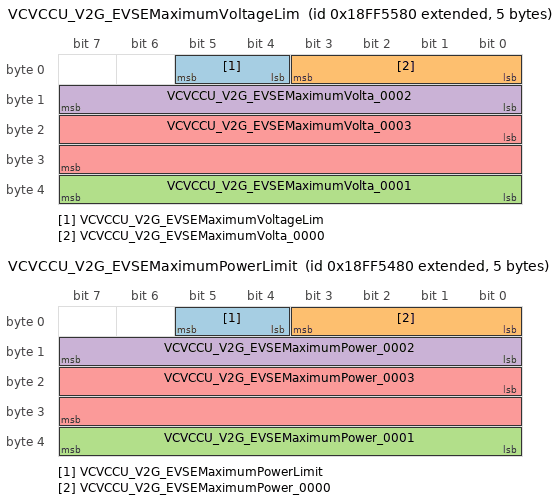
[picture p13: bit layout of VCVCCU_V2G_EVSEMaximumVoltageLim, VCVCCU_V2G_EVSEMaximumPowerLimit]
BO_ 2566870400 VCVCCU_V2G_EVSEMaximumVoltageLim: 5 VCVCCU
 SG_ VCVCCU_V2G_EVSEMaximumVoltageLim : 4|2@1+ (1,0) [0|0] ""  VCU
 SG_ VCVCCU_V2G_EVSEMaximumVolta_0000 : 0|4@1+ (1,0) [0|0] ""  VCU
 SG_ VCVCCU_V2G_EVSEMaximumVolta_0001 : 32|8@1+ (1,0) [0|0] ""  VCU
 SG_ VCVCCU_V2G_EVSEMaximumVolta_0002 : 8|8@1- (1,0) [0|0] ""  VCU
 SG_ VCVCCU_V2G_EVSEMaximumVolta_0003 : 16|16@1- (1,0) [0|0] ""  VCU

BO_ 2566870144 VCVCCU_V2G_EVSEMaximumPowerLimit: 5 VCVCCU
 SG_ VCVCCU_V2G_EVSEMaximumPowerLimit : 4|2@1+ (1,0) [0|0] ""  VCU
 SG_ VCVCCU_V2G_EVSEMaximumPower_0000 : 0|4@1+ (1,0) [0|0] ""  VCU
 SG_ VCVCCU_V2G_EVSEMaximumPower_0001 : 32|8@1+ (1,0) [0|0] ""  VCU
 SG_ VCVCCU_V2G_EVSEMaximumPower_0002 : 8|8@1- (1,0) [0|0] ""  VCU
 SG_ VCVCCU_V2G_EVSEMaximumPower_0003 : 16|16@1- (1,0) [0|0] ""  VCU

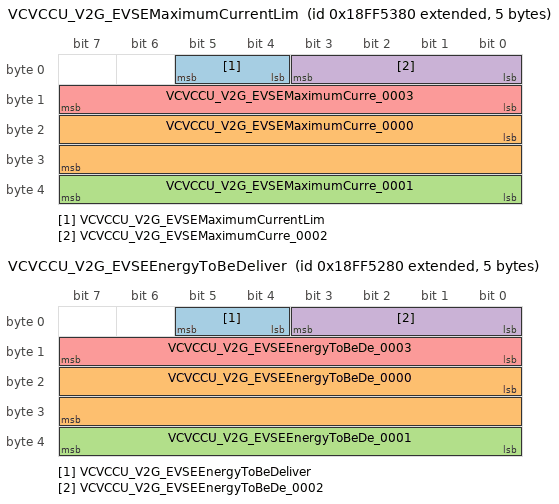
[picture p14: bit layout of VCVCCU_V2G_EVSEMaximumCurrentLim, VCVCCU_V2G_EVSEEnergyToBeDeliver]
BO_ 2566869888 VCVCCU_V2G_EVSEMaximumCurrentLim: 5 VCVCCU
 SG_ VCVCCU_V2G_EVSEMaximumCurrentLim : 4|2@1+ (1,0) [0|0] ""  VCU
 SG_ VCVCCU_V2G_EVSEMaximumCurre_0000 : 16|16@1- (1,0) [0|0] ""  VCU
 SG_ VCVCCU_V2G_EVSEMaximumCurre_0001 : 32|8@1+ (1,0) [0|0] ""  VCU
 SG_ VCVCCU_V2G_EVSEMaximumCurre_0002 : 0|4@1+ (1,0) [0|0] ""  VCU
 SG_ VCVCCU_V2G_EVSEMaximumCurre_0003 : 8|8@1- (1,0) [0|0] ""  VCU

BO_ 2566869632 VCVCCU_V2G_EVSEEnergyToBeDeliver: 5 VCVCCU
 SG_ VCVCCU_V2G_EVSEEnergyToBeDeliver : 4|2@1+ (1,0) [0|0] ""  VCU
 SG_ VCVCCU_V2G_EVSEEnergyToBeDe_0000 : 16|16@1- (1,0) [0|0] ""  VCU
 SG_ VCVCCU_V2G_EVSEEnergyToBeDe_0001 : 32|8@1+ (1,0) [0|0] ""  VCU
 SG_ VCVCCU_V2G_EVSEEnergyToBeDe_0002 : 0|4@1+ (1,0) [0|0] ""  VCU
 SG_ VCVCCU_V2G_EVSEEnergyToBeDe_0003 : 8|8@1- (1,0) [0|0] ""  VCU

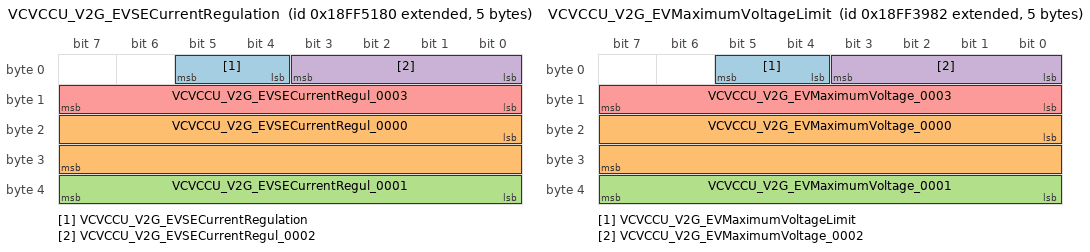
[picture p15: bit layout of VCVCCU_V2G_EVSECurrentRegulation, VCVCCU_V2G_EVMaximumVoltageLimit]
BO_ 2566869376 VCVCCU_V2G_EVSECurrentRegulation: 5 VCVCCU
 SG_ VCVCCU_V2G_EVSECurrentRegulation : 4|2@1+ (1,0) [0|0] ""  VCU
 SG_ VCVCCU_V2G_EVSECurrentRegul_0000 : 16|16@1- (1,0) [0|0] ""  VCU
 SG_ VCVCCU_V2G_EVSECurrentRegul_0001 : 32|8@1+ (1,0) [0|0] ""  VCU
 SG_ VCVCCU_V2G_EVSECurrentRegul_0002 : 0|4@1+ (1,0) [0|0] ""  VCU
 SG_ VCVCCU_V2G_EVSECurrentRegul_0003 : 8|8@1- (1,0) [0|0] ""  VCU

BO_ 2566863234 VCVCCU_V2G_EVMaximumVoltageLimit: 5 VCU
 SG_ VCVCCU_V2G_EVMaximumVoltageLimit : 4|2@1+ (1,0) [0|0] ""  VCVCCU
 SG_ VCVCCU_V2G_EVMaximumVoltage_0000 : 16|16@1- (1,0) [0|0] ""  VCVCCU
 SG_ VCVCCU_V2G_EVMaximumVoltage_0001 : 32|8@1+ (1,0) [0|0] ""  VCVCCU
 SG_ VCVCCU_V2G_EVMaximumVoltage_0002 : 0|4@1+ (1,0) [0|0] ""  VCVCCU
 SG_ VCVCCU_V2G_EVMaximumVoltage_0003 : 8|8@1- (1,0) [0|0] ""  VCVCCU

BO_ 2566862978 VCVCCU_V2G_EVMaximumPowerLimit: 5 VCU
 SG_ VCVCCU_V2G_EVMaximumPowerLimitFl : 4|2@1+ (1,0) [0|0] ""  VCVCCU
 SG_ VCVCCU_V2G_EVMaximumPowerLimit_V : 16|16@1- (1,0) [0|0] ""  VCVCCU
 SG_ VCVCCU_V2G_EVMaximumPowerLimit_U : 32|8@1+ (1,0) [0|0] ""  VCVCCU
 SG_ VCVCCU_V2G_EVMaximumPowerLi_0000 : 0|4@1+ (1,0) [0|0] ""  VCVCCU
 SG_ VCVCCU_V2G_EVMaximumPowerLimit_M : 8|8@1- (1,0) [0|0] ""  VCVCCU

BO_ 2566862722 VCVCCU_V2G_EVMaximumCurrentLimit: 5 VCU
 SG_ VCVCCU_V2G_EVMaximumCurrentLimit : 4|2@1+ (1,0) [0|0] ""  VCVCCU
 SG_ VCVCCU_V2G_EVMaximumCurrent_0000 : 0|4@1+ (1,0) [0|0] ""  VCVCCU
 SG_ VCVCCU_V2G_EVMaximumCurrent_0001 : 32|8@1+ (1,0) [0|0] ""  VCVCCU
 SG_ VCVCCU_V2G_EVMaximumCurrent_0002 : 8|8@1- (1,0) [0|0] ""  VCVCCU
 SG_ VCVCCU_V2G_EVMaximumCurrent_0003 : 16|16@1- (1,0) [0|0] ""  VCVCCU

BO_ 2566862466 VCVCCU_V2G_EVEnergyRequest: 5 VCU
 SG_ VCVCCU_V2G_EVEnergyRequestFlag : 4|2@1+ (1,0) [0|0] ""  VCVCCU
 SG_ VCVCCU_V2G_EVEnergyRequest_Unit : 0|4@1+ (1,0) [0|0] ""  VCVCCU
 SG_ VCVCCU_V2G_EVEnergyRequest_UnitF : 32|8@1+ (1,0) [0|0] ""  VCVCCU
 SG_ VCVCCU_V2G_EVEnergyRequest_Multi : 8|8@1- (1,0) [0|0] ""  VCVCCU
 SG_ VCVCCU_V2G_EVEnergyRequest_Value : 16|16@1- (1,0) [0|0] ""  VCVCCU

BO_ 2566862210 VCVCCU_V2G_EVEnergyCapacity: 5 VCU
 SG_ VCVCCU_V2G_EVEnergyCapacityFlag : 4|2@1+ (1,0) [0|0] ""  VCVCCU
 SG_ VCVCCU_V2G_EVEnergyCapacity_Unit : 0|4@1+ (1,0) [0|0] ""  VCVCCU
 SG_ VCVCCU_V2G_EVEnergyCapacity_0000 : 32|8@1+ (1,0) [0|0] ""  VCVCCU
 SG_ VCVCCU_V2G_EVEnergyCapacity_Mult : 8|8@1- (1,0) [0|0] ""  VCVCCU
 SG_ VCVCCU_V2G_EVEnergyCapacity_Valu : 16|16@1- (1,0) [0|0] ""  VCVCCU

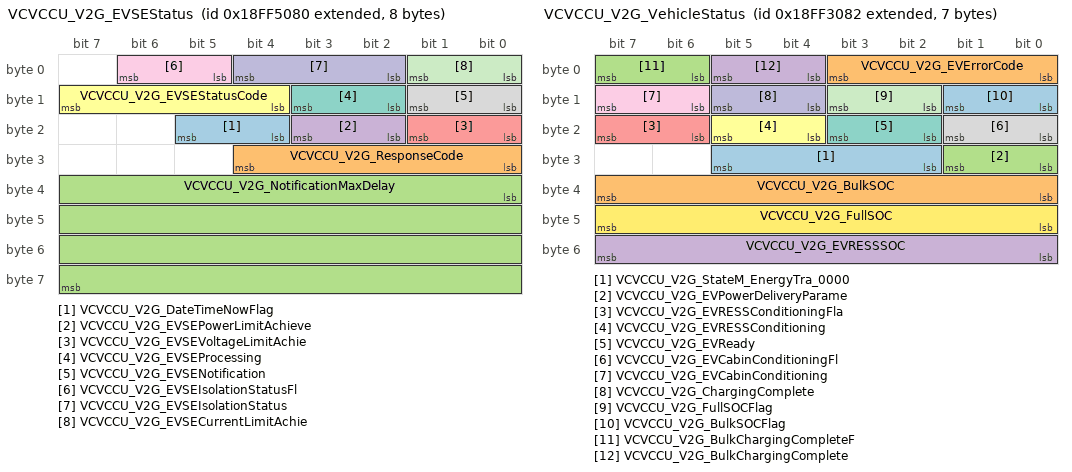
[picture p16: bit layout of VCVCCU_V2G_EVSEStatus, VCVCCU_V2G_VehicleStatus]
BO_ 2566869120 VCVCCU_V2G_EVSEStatus: 8 VCVCCU
 SG_ VCVCCU_V2G_DateTimeNowFlag : 20|2@1+ (1,0) [0|0] ""  VCU
 SG_ VCVCCU_V2G_ResponseCode : 24|5@1+ (1,0) [0|0] ""  VCU
 SG_ VCVCCU_V2G_NotificationMaxDelay : 32|32@1+ (1,0) [0|0] ""  VCU
 SG_ VCVCCU_V2G_EVSEPowerLimitAchieve : 18|2@1+ (1,0) [0|0] ""  VCU
 SG_ VCVCCU_V2G_EVSEVoltageLimitAchie : 16|2@1+ (1,0) [0|0] ""  VCU
 SG_ VCVCCU_V2G_EVSEStatusCode : 12|4@1+ (1,0) [0|0] ""  VCU
 SG_ VCVCCU_V2G_EVSEProcessing : 10|2@1+ (1,0) [0|0] ""  VCU
 SG_ VCVCCU_V2G_EVSENotification : 8|2@1+ (1,0) [0|0] ""  VCU
 SG_ VCVCCU_V2G_EVSEIsolationStatusFl : 5|2@1+ (1,0) [0|0] ""  VCU
 SG_ VCVCCU_V2G_EVSEIsolationStatus : 2|3@1+ (1,0) [0|0] ""  VCU
 SG_ VCVCCU_V2G_EVSECurrentLimitAchie : 0|2@1+ (1,0) [0|0] ""  VCU

BO_ 2566861954 VCVCCU_V2G_EVTargetCurrent: 5 VCU
 SG_ VCVCCU_V2G_EVTargetCurrent_Value : 0|16@1- (1,0) [0|0] ""  VCVCCU
 SG_ VCVCCU_V2G_EVTargetCurrent_UnitF : 24|8@1+ (1,0) [0|0] ""  VCVCCU
 SG_ VCVCCU_V2G_EVTargetCurrent_Unit : 32|4@1+ (1,0) [0|0] ""  VCVCCU
 SG_ VCVCCU_V2G_EVTargetCurrent_Multi : 16|8@1- (1,0) [0|0] ""  VCVCCU

BO_ 2566861698 VCVCCU_V2G_EVTargetVoltage: 5 VCU
 SG_ VCVCCU_V2G_EVTargetVoltage_Value : 0|16@1- (1,0) [0|0] ""  VCVCCU
 SG_ VCVCCU_V2G_EVTargetVoltage_UnitF : 24|8@1+ (1,0) [0|0] ""  VCVCCU
 SG_ VCVCCU_V2G_EVTargetVoltage_Unit : 32|4@1+ (1,0) [0|0] ""  VCVCCU
 SG_ VCVCCU_V2G_EVTargetVoltage_Multi : 16|8@1- (1,0) [0|0] ""  VCVCCU

BO_ 2566861442 VCVCCU_V2G_RemainimeToBulkSOC: 5 VCU
 SG_ VCVCCU_V2G_RemainingTimeToBulkSO : 36|2@1+ (1,0) [0|0] ""  VCVCCU
 SG_ VCVCCU_V2G_RemainingTimeToB_0000 : 0|16@1- (1,0) [0|0] ""  VCVCCU
 SG_ VCVCCU_V2G_RemainingTimeToB_0001 : 24|8@1+ (1,0) [0|0] ""  VCVCCU
 SG_ VCVCCU_V2G_RemainingTimeToB_0002 : 32|4@1+ (1,0) [0|0] ""  VCVCCU
 SG_ VCVCCU_V2G_RemainingTimeToB_0003 : 16|8@1- (1,0) [0|0] ""  VCVCCU

BO_ 2566861186 VCVCCU_V2G_RemainTimeToFullSOC: 5 VCU
 SG_ VCVCCU_V2G_RemainingTimeToFullSO : 36|2@1+ (1,0) [0|0] ""  VCVCCU
 SG_ VCVCCU_V2G_RemainingTimeToF_0000 : 0|16@1- (1,0) [0|0] ""  VCVCCU
 SG_ VCVCCU_V2G_RemainingTimeToF_0001 : 24|8@1+ (1,0) [0|0] ""  VCVCCU
 SG_ VCVCCU_V2G_RemainingTimeToF_0002 : 32|4@1+ (1,0) [0|0] ""  VCVCCU
 SG_ VCVCCU_V2G_RemainingTimeToF_0003 : 16|8@1- (1,0) [0|0] ""  VCVCCU

BO_ 2566860930 VCVCCU_V2G_VehicleStatus: 7 VCU
 SG_ VCVCCU_V2G_StateM_EnergyTra_0000 : 26|4@1+ (1,0) [0|15] ""  VCVCCU
 SG_ VCVCCU_V2G_EVErrorCode : 0|4@1+ (1,0) [0|0] ""  VCVCCU
 SG_ VCVCCU_V2G_EVPowerDeliveryParame : 24|2@1+ (1,0) [0|0] ""  VCVCCU
 SG_ VCVCCU_V2G_EVRESSSOC : 48|8@1- (1,0) [0|0] ""  VCVCCU
 SG_ VCVCCU_V2G_EVRESSConditioningFla : 22|2@1+ (1,0) [0|0] ""  VCVCCU
 SG_ VCVCCU_V2G_EVRESSConditioning : 20|2@1+ (1,0) [0|0] ""  VCVCCU
 SG_ VCVCCU_V2G_EVReady : 18|2@1+ (1,0) [0|0] ""  VCVCCU
 SG_ VCVCCU_V2G_EVCabinConditioningFl : 16|2@1+ (1,0) [0|0] ""  VCVCCU
 SG_ VCVCCU_V2G_EVCabinConditioning : 14|2@1+ (1,0) [0|0] ""  VCVCCU
 SG_ VCVCCU_V2G_ChargingComplete : 12|2@1+ (1,0) [0|0] ""  VCVCCU
 SG_ VCVCCU_V2G_FullSOCFlag : 10|2@1+ (1,0) [0|0] ""  VCVCCU
 SG_ VCVCCU_V2G_FullSOC : 40|8@1- (1,0) [0|0] ""  VCVCCU
 SG_ VCVCCU_V2G_BulkSOCFlag : 8|2@1+ (1,0) [0|0] ""  VCVCCU
 SG_ VCVCCU_V2G_BulkSOC : 32|8@1- (1,0) [0|0] ""  VCVCCU
 SG_ VCVCCU_V2G_BulkChargingCompleteF : 6|2@1+ (1,0) [0|3] "x"  VCVCCU
 SG_ VCVCCU_V2G_BulkChargingComplete : 4|2@1+ (1,0) [0|0] ""  VCVCCU

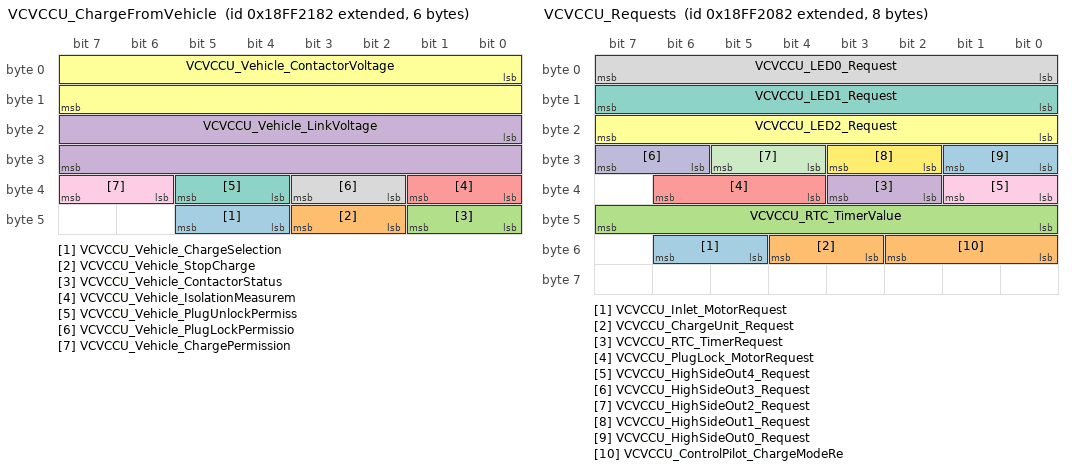
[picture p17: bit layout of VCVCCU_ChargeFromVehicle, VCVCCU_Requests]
BO_ 2566857090 VCVCCU_ChargeFromVehicle: 6 VCU
 SG_ VCVCCU_Vehicle_ChargeSelection : 44|2@1+ (1,0) [0|3] "" Vector__XXX
 SG_ VCVCCU_Vehicle_StopCharge : 42|2@1+ (1,0) [0|3] "" Vector__XXX
 SG_ VCVCCU_Vehicle_ContactorStatus : 40|2@1+ (1,0) [0|3] ""  VCVCCU
 SG_ VCVCCU_Vehicle_LinkVoltage : 16|16@1+ (1,0) [0|65533] "V"  VCVCCU
 SG_ VCVCCU_Vehicle_IsolationMeasurem : 32|2@1+ (1,0) [0|3] ""  VCVCCU
 SG_ VCVCCU_Vehicle_ContactorVoltage : 0|16@1+ (1,0) [0|65533] "V"  VCVCCU
 SG_ VCVCCU_Vehicle_PlugUnlockPermiss : 36|2@1+ (1,0) [0|3] ""  VCVCCU
 SG_ VCVCCU_Vehicle_PlugLockPermissio : 34|2@1+ (1,0) [0|3] ""  VCVCCU
 SG_ VCVCCU_Vehicle_ChargePermission : 38|2@1+ (1,0) [0|3] ""  VCVCCU

BO_ 2566854528 VCVCCU_ChargeToVehicle: 1 VCVCCU
 SG_ VCVCCU_Vehicle_ChargeSelectiAck : 4|2@1+ (1,0) [0|3] "" Vector__XXX
 SG_ VCVCCU_Vehicle_ContactorRequest : 2|2@1+ (1,0) [0|0] ""  VCU
 SG_ IsolationMeasurement_request : 0|2@1+ (1,0) [0|3] ""  VCU

BO_ 2566856834 VCVCCU_Requests: 8 VCU
 SG_ VCVCCU_Inlet_MotorRequest : 53|2@1+ (1,0) [0|3] ""  VCVCCU
 SG_ VCVCCU_ChargeUnit_Request : 51|2@1+ (1,0) [0|3] ""  VCVCCU
 SG_ VCVCCU_RTC_TimerValue : 40|8@1+ (1,0) [0|254] "min"  VCVCCU
 SG_ VCVCCU_RTC_TimerRequest : 34|2@1+ (1,0) [0|3] ""  VCVCCU
 SG_ VCVCCU_PlugLock_MotorRequest : 36|3@1+ (1,0) [0|7] ""  VCVCCU
 SG_ VCVCCU_LED2_Request : 16|8@1+ (0.5,0) [0|100] "%"  VCVCCU
 SG_ VCVCCU_LED1_Request : 8|8@1+ (0.5,0) [0|100] "%"  VCVCCU
 SG_ VCVCCU_LED0_Request : 0|8@1+ (0.5,0) [0|100] "%"  VCVCCU
 SG_ VCVCCU_HighSideOut4_Request : 32|2@1+ (1,0) [0|3] ""  VCVCCU
 SG_ VCVCCU_HighSideOut3_Request : 30|2@1+ (1,0) [0|3] ""  VCVCCU
 SG_ VCVCCU_HighSideOut2_Request : 28|2@1+ (1,0) [0|3] ""  VCVCCU
 SG_ VCVCCU_HighSideOut1_Request : 26|2@1+ (1,0) [0|3] ""  VCVCCU
 SG_ VCVCCU_HighSideOut0_Request : 24|2@1+ (1,0) [0|3] ""  VCVCCU
 SG_ VCVCCU_ControlPilot_ChargeModeRe : 48|3@1+ (1,0) [0|7] ""  VCVCCU

BO_ 2566854272 VCVCCU_RTCStatus: 1 VCVCCU
 SG_ VCVCCU_RTC_Wakeup : 4|2@1+ (1,0) [0|3] ""  VCU
 SG_ VCVCCU_RTC_TimerStatus : 0|2@1+ (1,0) [0|3] ""  VCU

BO_ 2566854016 VCVCCU_OutputStatus: 7 VCVCCU
 SG_ VCVCCU_HighSideOut3_Input_Wakeup : 52|2@1+ (1,0) [0|3] ""  VCU
 SG_ VCVCCU_HighSideOut4_Input_Status : 50|2@1+ (1,0) [0|3] ""  VCU
 SG_ VCVCCU_HighSideOut4_Input_Deboun : 48|2@1+ (1,0) [0|3] ""  VCU
 SG_ VCVCCU_HighSideOut3_Input_Status : 46|2@1+ (1,0) [0|3] ""  VCU
 SG_ VCVCCU_HighSideOut3_Input_Deboun : 44|2@1+ (1,0) [0|3] ""  VCU
 SG_ VCVCCU_HighSideOut2_Input_Status : 42|2@1+ (1,0) [0|3] ""  VCU
 SG_ VCVCCU_HighSideOut2_Input_Deboun : 40|2@1+ (1,0) [0|3] ""  VCU
 SG_ VCVCCU_HighSideOut1_Input_Status : 38|2@1+ (1,0) [0|3] ""  VCU
 SG_ VCVCCU_HighSideOut1_Input_Deboun : 36|2@1+ (1,0) [0|3] ""  VCU
 SG_ VCVCCU_HighSideOut0_Input_Status : 34|2@1+ (1,0) [0|3] ""  VCU
 SG_ VCVCCU_HighSideOut0_Input_Deboun : 32|2@1+ (1,0) [0|3] ""  VCU
 SG_ VCVCCU_LED2_SelfDiagnosticStatus : 28|3@1+ (1,0) [0|7] ""  VCU
 SG_ VCVCCU_LED1_SelfDiagnosticStatus : 24|3@1+ (1,0) [0|7] ""  VCU
 SG_ VCVCCU_LED0_SelfDiagnosticStatus : 20|3@1+ (1,0) [0|7] ""  VCU
 SG_ VCVCCU_HighSideOut4_SelfDiagnost : 16|3@1+ (1,0) [0|7] ""  VCU
 SG_ VCVCCU_HighSideOut3_SelfDiagnost : 12|3@1+ (1,0) [0|7] ""  VCU
 SG_ VCVCCU_HighSideOut2_SelfDiagnost : 8|3@1+ (1,0) [0|7] ""  VCU
 SG_ VCVCCU_HighSideOut1_SelfDiagnost : 4|3@1+ (1,0) [0|7] ""  VCU
 SG_ VCVCCU_HighSideOut0_SelfDiagnost : 0|3@1+ (1,0) [0|7] ""  VCU

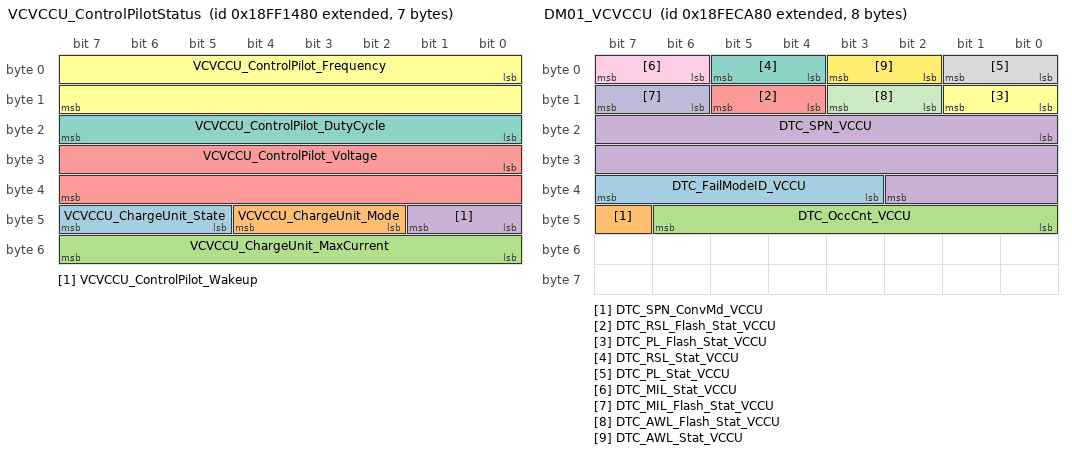
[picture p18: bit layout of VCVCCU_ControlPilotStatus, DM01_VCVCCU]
BO_ 2566853760 VCVCCU_ControlPilotStatus: 7 VCVCCU
 SG_ VCVCCU_ChargeUnit_State : 45|3@1+ (1,0) [0|7] ""  VCU
 SG_ VCVCCU_ChargeUnit_Mode : 42|3@1+ (1,0) [0|7] ""  VCU
 SG_ VCVCCU_ChargeUnit_MaxCurrent : 48|8@1+ (1,0) [0|255] "A"  VCU
 SG_ VCVCCU_ControlPilot_Wakeup : 40|2@1+ (1,0) [0|3] ""  VCU
 SG_ VCVCCU_ControlPilot_Voltage : 24|16@1+ (1,-32000) [-32000|33533] "mV"  VCU
 SG_ VCVCCU_ControlPilot_Frequency : 0|16@1+ (1,0) [0|65533] "Hz"  VCU
 SG_ VCVCCU_ControlPilot_DutyCycle : 16|8@1+ (0.5,0) [0|100] "%"  VCU

BO_ 2566853504 VCVCCU_InletStatus: 8 VCVCCU
 SG_ VCVCCU_Inlet_HWVariant : 38|2@1+ (1,0) [0|3] ""  VCU
 SG_ VCVCCU_S3Switch_Status : 60|2@1+ (1,0) [0|3] ""  VCU
 SG_ VCVCCU_S3Switch_DebouncedStatus : 62|2@1+ (1,0) [0|3] ""  VCU
 SG_ VCVCCU_DigitalInput_DebouncedSta : 56|2@1+ (1,0) [0|3] ""  VCU
 SG_ VCVCCU_Inlet_MaxCurrent : 48|8@1+ (1,0) [0|255] "A"  VCU
 SG_ VCVCCU_Inlet_MotorStatus : 44|3@1+ (1,0) [0|7] ""  VCU
 SG_ VCVCCU_Inlet_ConnectionStatus : 58|2@1+ (1,0) [0|0] ""  VCU
 SG_ VCVCCU_PlugPresent_Wakeup : 24|2@1+ (1,0) [0|3] ""  VCU
 SG_ VCVCCU_PlugPresent_Status : 22|2@1+ (1,0) [0|0] ""  VCU
 SG_ VCVCCU_POSFeedback_SelfDiagnosti : 26|3@1+ (1,0) [0|7] ""  VCU
 SG_ VCVCCU_PlugPresent_SelfDiagnosti : 16|3@1+ (1,0) [0|7] ""  VCU
 SG_ VCVCCU_DigitalInput_Wakeup : 42|2@1+ (1,0) [0|3] ""  VCU
 SG_ VCVCCU_PlugPresent_Resistance : 19|3@1+ (1,0) [0|7] ""  VCU
 SG_ VCVCCU_PlugLock_Output1_SelfDiag : 35|3@1+ (1,0) [0|7] ""  VCU
 SG_ VCVCCU_DigitalInput_Status : 40|2@1+ (1,0) [0|3] ""  VCU
 SG_ VCVCCU_PlugLock_Output0_SelfDiag : 32|3@1+ (1,0) [0|7] ""  VCU
 SG_ VCVCCU_PlugLock_MotorStatus : 29|3@1+ (1,0) [0|7] ""  VCU
 SG_ VCVCCU_POSFeedback_Voltage : 0|16@1+ (1,0) [0|65533] "mV"  VCU

BO_ 2566853248 VCVCCU_PTC2: 7 VCVCCU
 SG_ VCVCCU_PTC2_SelfDiagnosticStatus : 48|3@1+ (1,0) [0|7] ""  VCU
 SG_ VCVCCU_PTC2_Temperature : 32|16@1+ (1,-150) [-150|65383] "°C"  VCU
 SG_ VCVCCU_PTC2_Resistance : 16|16@1+ (1,0) [0|65533] "Ohm"  VCU
 SG_ VCVCCU_PTC2_Raw : 0|16@1+ (1,0) [0|65533] ""  VCU

BO_ 2566852992 VCVCCU_PTC1: 7 VCVCCU
 SG_ VCVCCU_PTC1_SelfDiagnosticStatus : 48|3@1+ (1,0) [0|7] ""  VCU
 SG_ VCVCCU_PTC1_Temperature : 32|16@1+ (1,-150) [-150|65383] "°C"  VCU
 SG_ VCVCCU_PTC1_Resistance : 16|16@1+ (1,0) [0|65533] "Ohm"  VCU
 SG_ VCVCCU_PTC1_Raw : 0|16@1+ (1,0) [0|65533] ""  VCU

BO_ 2363228034 DIAG_REQ_GLOBAL: 8 VCU
 SG_ DIAG_REQ_GLOBAL : 0|64@1+ (1,0) [0|0] ""  VCVCCU

BO_ 2566910080 XCP_RESP_VCVCCU: 8 VCVCCU
 SG_ XCP_RESP_VCCU : 0|64@1+ (1,0) [0|0] ""  VCU

BO_ 2566910082 XCP_REQ_VCVCCU: 8 VCVCCU
 SG_ XCP_REQ_VCCU : 0|64@1+ (1,0) [0|0] ""  VCVCCU

BO_ 2363129984 DIAG_RESP_VCVCCU: 8 VCVCCU
 SG_ DIAG_RESP_VCCU : 0|64@1+ (1,0) [0|0] ""  VCU

BO_ 2633990272 NM_VCVCCU: 8 VCVCCU
 SG_ Awake_Clamp15_Actv_VCVCCU : 26|1@1+ (1,0) [0|1] ""  VCU
 SG_ Awake_ChargeCom_Actv_VCVCCU : 25|1@1+ (1,0) [0|1] ""  VCU
 SG_ Awake_Diag_Actv_VCVCCU : 24|1@1+ (1,0) [0|1] ""  VCU
 SG_ WakeupRsn_VCVCCU : 16|8@1+ (1,0) [0|4] ""  VCU

BO_ 2566834816 DM01_VCVCCU: 8 VCVCCU
 SG_ DTC_FailModeID_VCCU : 35|5@1+ (1,0) [0|31] ""  VCU
 SG_ DTC_SPN_ConvMd_VCCU : 47|1@1+ (1,0) [0|1] ""  VCU
 SG_ DTC_OccCnt_VCCU : 40|7@1+ (1,0) [0|127] "count(s)"  VCU
 SG_ DTC_SPN_VCCU : 16|19@1+ (1,0) [0|524287] ""  VCU
 SG_ DTC_RSL_Flash_Stat_VCCU : 12|2@1+ (1,0) [0|3] ""  VCU
 SG_ DTC_PL_Flash_Stat_VCCU : 8|2@1+ (1,0) [0|3] ""  VCU
 SG_ DTC_RSL_Stat_VCCU : 4|2@1+ (1,0) [0|3] ""  VCU
 SG_ DTC_PL_Stat_VCCU : 0|2@1+ (1,0) [0|3] ""  VCU
 SG_ DTC_MIL_Stat_VCCU : 6|2@1+ (1,0) [0|3] ""  VCU
 SG_ DTC_MIL_Flash_Stat_VCCU : 14|2@1+ (1,0) [0|3] ""  VCU
 SG_ DTC_AWL_Flash_Stat_VCCU : 10|2@1+ (1,0) [0|3] ""  VCU
 SG_ DTC_AWL_Stat_VCCU : 2|2@1+ (1,0) [0|3] ""  VCU

BO_ 2566852736 VCVCCU_PTC0: 7 VCVCCU
 SG_ VCVCCU_PTC0_SelfDiagnosticStatus : 48|3@1+ (1,0) [0|7] ""  VCU
 SG_ VCVCCU_PTC0_Resistance : 16|16@1+ (1,0) [0|65533] "Ohm"  VCU
 SG_ VCVCCU_PTC0_Raw : 0|16@1+ (1,0) [0|65533] ""  VCU
 SG_ VCVCCU_PTC0_Temperature : 32|16@1+ (1,-150) [-150|65383] "°C"  VCU

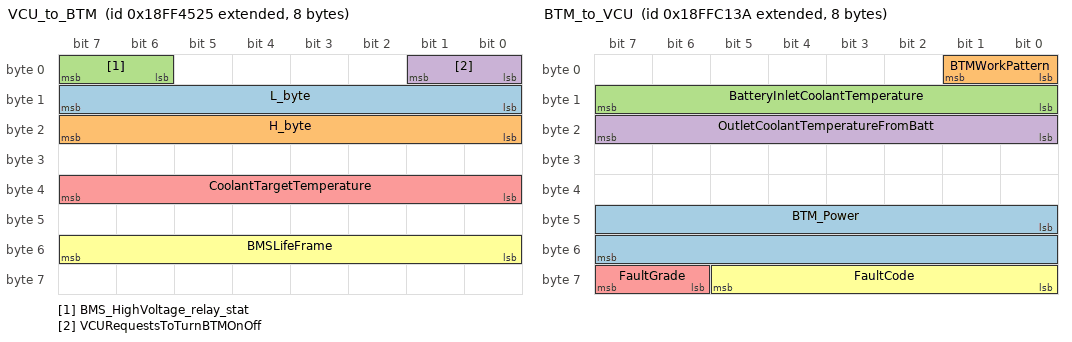
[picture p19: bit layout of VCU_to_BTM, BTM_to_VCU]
BO_ 2566866213 VCU_to_BTM: 8 VCU
 SG_ L_byte : 8|8@1+ (1,0) [0|0] "" Vector__XXX
 SG_ H_byte : 16|8@1+ (1,0) [0|0] "" Vector__XXX
 SG_ BMS_HighVoltage_relay_stat : 6|2@1+ (1,0) [0|0] "" Vector__XXX
 SG_ VCURequestsToTurnBTMOnOff : 0|2@1+ (1,0) [0|3] ""  TMS
 SG_ CoolantTargetTemperature : 32|8@1+ (1,-40) [-40|40] "°C"  TMS
 SG_ BMSLifeFrame : 48|8@1+ (1,0) [0|255] ""  TMS

BO_ 2566897978 BTM_to_VCU: 8 TMS
 SG_ BTM_Power : 40|16@1+ (0.1,0) [0|6553.5] "" Vector__XXX
 SG_ BTMWorkPattern : 0|2@1+ (1,0) [0|3] "" Vector__XXX
 SG_ BatteryInletCoolantTemperature : 8|8@1+ (1,-40) [-40|40] "°C" Vector__XXX
 SG_ OutletCoolantTemperatureFromBatt : 16|8@1+ (1,-40) [-40|40] "°C" Vector__XXX
 SG_ FaultGrade : 62|2@1+ (1,0) [0|3] "" Vector__XXX
 SG_ FaultCode : 56|6@1+ (1,0) [0|63] "" Vector__XXX

CM_ SG_ 2566841895 Year "The year component of the current calendar date.  This should be reported as the year component of the current date at UTC (Universal Time Coordinate), a.k.a. GMT; however, it may be reported as the year component of the current date at a local time ...";
CM_ SG_ 2566841895 Seconds "The seconds component of the current time of day.  This should be reported as the seconds component of the current time at UTC (Universal Time Coordinate), a.k.a. GMT; however, it may be reported as the seconds component of the current time at a ...";
CM_ SG_ 2566841895 Month "The month component of the current calendar date.  This should be reported as the month component of the current date at UTC (Universal Time Coordinate), a.k.a. GMT; however, it may be reported as the month component of the current date at a local ...";
CM_ SG_ 2566841895 Minutes "The minutes component of the current time of day.  This should be reported as the minutes component of the current time at UTC (Universal Time Coordinate), a.k.a. GMT; however, it may be reported as the minutes component of the current time at a ...";
CM_ SG_ 2566841895 LocalMinuteOffset "The minute component of the offset between the UTC time and date and a local time zone time and date.  This is the number of minutes to add to UTC (Universal Time Coordinate) time and date to convert to the time and date in the local time zone  ...";
CM_ SG_ 2566841895 LocalHourOffset "The hour component of the offset between the UTC (Universal Time Coordinate) time and date and a local time zone time and date.  This is the number of hours to add to UTC, a.k.a. GMT, time and date to convert to the time and date in the local time ...";
CM_ SG_ 2566841895 Hours "The hour component of the current time of day.  This should be reported as the hour component of the current time at UTC (Universal Time Coordinate), a.k.a. GMT; however, it may be reported as the hour component of the current time at a local time ...";
CM_ SG_ 2566841895 Day "The day component of the current calendar date.  This should be reported as the day component of the current date at UTC (Universal Time Coordinate), a.k.a. GMT; however, it may be reported as the day component of the current date at a local time ...";
CM_ BO_ 2364609638 "DC/DC Converter 1 Voltage and Current
Voltage and current data from a DC/DC Converter.

One intended use of this message is for a conventional engine mounted alternator replacement.";
CM_ SG_ 2364609638 HiSideCur "Indicates the measured HVES or high side current measured at the point of control inside the DC/DC Converter.  The current is negative if the converter is charging the SLI battery from the hybrid battery.";
CM_ SG_ 2364609638 HiSideV "Indicates the measured HVES or high side voltage measured at the point of control inside the DC/DC Converter.";
CM_ SG_ 2364609638 LowSideCur "Indicates the measured SLI battery or low side current measured at the point of control inside the DC/DC Converter.  The current is positive if the converter is charging the SLI battery from the hybrid battery.";
CM_ SG_ 2364609638 LowSideV "Indicates the measured SLI battery or low side voltage measured at the point of control inside the DC/DC Converter.";
CM_ BO_ 2365297510 "DC/DC Converter 1 Voltage
Low Voltage data from DC/DC Converter.";
CM_ SG_ 2365297510 OneCtrlInputSLIV "Voltage (i.e not switched) supplied to the DC/DC Converter controller.";
CM_ SG_ 2365297510 OneCtrlInputIgntV "Ignition voltage (i.e. switched) supplied to the  DC/DC Converter controller.";
CM_ BO_ 2365315174 "DC/DC Converter 1 Temperatures
DC/DC Converter measured temperature data.

One intended use of this message is for a conventional engine mounted alternator replacement.";
CM_ SG_ 2365315174 OneCoolantOutTemp "Parameter indicating the temperature of the DC/DC Converter Coolant measured at the output of the converter";
CM_ SG_ 2365315174 OneCoolantInTemp "Parameter indicating the temperature of the DC/DC Converter Coolant measured at the input of the converter";
CM_ SG_ 2365315174 PwrETemp "Parameter indicating the temperature of the DC/DC Converter power electronics components (e.g, switch or heatsink).";
CM_ SG_ 2365315174 ElectronicFilterTemp "Parameter indicating the temperature of the electronic components that make up the DC/DC Converter filter.";
CM_ SG_ 2365315174 Temp "Parameter indicating the temperature of the DC/DC Converter (e.g, controller, circuit board, enclosure).";
CM_ BO_ 2364609382 "DC/DC Converter 1 Operating Status
Contains information on the operating status of a DC/DC Converter.

One intended use of this message is for a conventional engine mounted alternator replacement.";
CM_ SG_ 2364609382 PLDueToUndefinedReason "Indicates whether or not output power is being limited due to an undefined reason.

00 - No power limit for this reason
01 - Power limited for this reason
10 - Error
11 - Not Available";
CM_ SG_ 2364609382 PLDueToSLIBatTermTemp "Indicates whether or not output power is being limited due to the SLI battery terminal temperature (see SPN 8591) approaching or exceeding limits (see SPN 8819).
00 - No power limit for this reason
01 - Power limited for this reason
10 - Error
 ...";
CM_ SG_ 2364609382 PLDueToSLIBatTermCur "Indicates whether or not output power is being limited due to the SLI battery terminal current (see SPN 8590) approaching or exceeding limits (see SPN 8818).
00 - No power limit for this reason
01 - Power limited for this reason
10 - Error
11 - ...";
CM_ SG_ 2364609382 PLDueToSLIBatTermV "Indicates whether or not output power is being limited due to the SLI battery terminal voltage (see SPN 8589) approaching or exceeding limits (see SPN 8817).
00 - No power limit for this reason
01 - Power limited for this reason
10 - Error
11 - ...";
CM_ SG_ 2364609382 PLDueToPwrETemp "Indicates whether or not output power is being limited due to Power Electronics Temperature (see SPN 8594) approaching or exceeding the maximum limit.
00 - No power limit for this reason
01 - Power limited for this reason
10 - Error
11 - Not ...";
CM_ SG_ 2364609382 PLDueToElectronicFilterTemp "Indicates whether or not output power is being limited due to Output Electronic Filter Temperature (see SPN 8693) approaching or exceeding the maximum limit.
00 - No power limit for this reason
01 - Power limited for this reason
10 - Error
11 - ...";
CM_ SG_ 2364609382 PLDueToCtrlTemp "Indicates whether or not output power is being limited due to Converter Temperature (see SPN 8592) approaching or exceeding the maximum limit.

00 - No power limit for this reason
01 - Power limited for this reason
10 - Error
11 - Not Available";
CM_ SG_ 2364609382 PLDueToLowSideVMax "Indicates whether or not output power is being limited due to low side voltage (see SPN 8585) approaching or exceeding the maximum limit (see SPN 8567).
00 - No power limit for this reason
01 - Power limited for this reason
10 - Error
11 - Not ...";
CM_ SG_ 2364609382 PLDueToLowSideVMin "Indicates whether or not output power is being limited due to low side voltage (see SPN 8585) approaching or falling below the minimum limit (see SPN 8566).
00 - No power limit for this reason
01 - Power limited for this reason
10 - Error
11 - ...";
CM_ SG_ 2364609382 PLDueToHiSideVMax "Indicates whether or not output power is being limited due to high side voltage (see SPN 8587) approaching or exceeding the maximum limit (see SPN 8564).
00 - No power limit for this reason
01 - Power limited for this reason
10 - Error
11 - Not ...";
CM_ SG_ 2364609382 PLDueToHiSideVMin "Indicates whether or not output power is being limited due to high side voltage (see SPN 8587) approaching or falling below the minimum limit (see SPN 8563).
00 - No power limit for this reason
01 - Power limited for this reason
10 - Error
11 - ...";
CM_ SG_ 2364609382 PLDueToLowSideCur "Indicates whether or not output power is being limited due to low side current (see SPN 8586) approaching or exceeding the maximum limit (see SPN 8568).
00 - No power limit for this reason
01 - Power limited for this reason
10 - Error
11 - Not ...";
CM_ SG_ 2364609382 PLDueToHiSideCur "Indicates whether or not output power is being limited due to high side current (see SPN 8588) approaching or exceeding the maximum limit (see SPN 8565).
00 - No power limit for this reason
01 - Power limited for this reason
10 - Error
11 - Not ...";
CM_ SG_ 2364609382 LoadshedReq "The loadshed request is a request to the controlling device to reduce the DC/DC Converter loads.  The Loadshed Requested state is an indication that this DC/DC Converter has a malfunction or is in a limit condition and if the load of the output is ...";
CM_ SG_ 2364609382 HVILStatus "High Voltage Interlock Loop (HVIL) state of the DC/DC Converter.

00 - HVIL Closed
01 - HVIL Open
10 - Error
11 - Not Available";
CM_ SG_ 2364609382 OperationalStatus "Operating state of the DC/DC Converter
0000 - Disabled
0001 - Initialization in process.  The device is powering up.  This process may include both internal checks, as well as system checks being run by the DC/DC Converter.
0010 - Operational - ...";
CM_ BO_ 2365315430 "DC/DC Converter 1 Low Side Limits
Sets the SLI or Low Voltage system limits for the transfer of energy between the HVES or high voltage system (i.e. high side) and the SLI battery or low voltage system (i.e. low side) in a DC/DC Converter.";
CM_ SG_ 2365315430 LowSideCurMaxLmt "The maximum allowed low side current requested by a separate device.   Under normal conditions this requested limit would be reflected in SPN 8829.";
CM_ SG_ 2365315430 LowSideVMaxLmt "The maximum allowed low side voltage requested by a separate device.   Under normal conditions this requested limit would be reflected in SPN 8828.";
CM_ SG_ 2365315430 LowSideVMinLmt "The minimum allowed low side voltage requested by a separate device.   Under normal conditions this requested limit would be reflected in SPN 8827.";
CM_ SG_ 2566856990 Current_measurement_range "0x0 - Range not defined
0x1 - Sensor Range I1 (+-10 A)
0x2 - Sensor Range I2 (+-600 A)
0x3 - Sensor Range I3 (+-1500 A)
0x6 - Error
0x7 -  Not Available
";
CM_ BO_ 2365297509 "DC/DC Converter 1 Voltage
Low Voltage data from DC/DC Converter.";
CM_ SG_ 2365297509 OneCtrlInputSLIV "Voltage (i.e not switched) supplied to the DC/DC Converter controller.";
CM_ SG_ 2365297509 OneCtrlInputIgntV "Ignition voltage (i.e. switched) supplied to the  DC/DC Converter controller.";
CM_ BO_ 2364610599 "DC/DC Converter 2 Control
Controls the transfer of energy between the HVES or high voltage system (i.e. high side) and the SLI battery or low voltage system (i.e. low side).  Provides a function to either charge the SLI Battery from the HVES (Buck) ...";
CM_ SG_ 2364610599 TwoLowSideVBuckDefaultSetpoint "The set point for the converter default low side voltage during buck mode.   This setting may be used for when communication has been lost with the controlling device.  When set to Not Available (FFFFh), no default setting is provided and the system ...";
CM_ SG_ 2364610599 TwoHiSideVBoostSetpoint "The set point for regulating the high side voltage during boost mode.";
CM_ SG_ 2364610599 TwoLowSideVBuckSetpoint "The set point for regulating the low side voltage during buck mode.";
CM_ SG_ 2364610599 TwoOperationalCmd "Command to enable or disable operation.
0000 - Disable - in this mode all high voltage switching is disabled
0001 - Operate in standby mode; system is waiting for command to enter buck or boost mode
0010 - Operate in buck mode; energy flows from ...";
CM_ BO_ 2365315429 "DC/DC Converter 1 Low Side Limits
Sets the SLI or Low Voltage system limits for the transfer of energy between the HVES or high voltage system (i.e. high side) and the SLI battery or low voltage system (i.e. low side) in a DC/DC Converter.";
CM_ SG_ 2365315429 LowSideCurMaxLmt "The maximum allowed low side current requested by a separate device.   Under normal conditions this requested limit would be reflected in SPN 8829.";
CM_ SG_ 2365315429 LowSideVMaxLmt "The maximum allowed low side voltage requested by a separate device.   Under normal conditions this requested limit would be reflected in SPN 8828.";
CM_ SG_ 2365315429 LowSideVMinLmt "The minimum allowed low side voltage requested by a separate device.   Under normal conditions this requested limit would be reflected in SPN 8827.";
CM_ BO_ 2365315173 "DC/DC Converter 1 Temperatures
DC/DC Converter measured temperature data.

One intended use of this message is for a conventional engine mounted alternator replacement.";
CM_ SG_ 2365315173 OneCoolantOutTemp "Parameter indicating the temperature of the DC/DC Converter Coolant measured at the output of the converter";
CM_ SG_ 2365315173 OneCoolantInTemp "Parameter indicating the temperature of the DC/DC Converter Coolant measured at the input of the converter";
CM_ SG_ 2365315173 PwrETemp "Parameter indicating the temperature of the DC/DC Converter power electronics components (e.g, switch or heatsink).";
CM_ SG_ 2365315173 ElectronicFilterTemp "Parameter indicating the temperature of the electronic components that make up the DC/DC Converter filter.";
CM_ SG_ 2365315173 Temp "Parameter indicating the temperature of the DC/DC Converter (e.g, controller, circuit board, enclosure).";
CM_ BO_ 2364609637 "DC/DC Converter 1 Voltage and Current
Voltage and current data from a DC/DC Converter.

One intended use of this message is for a conventional engine mounted alternator replacement.";
CM_ SG_ 2364609637 HiSideCur "Indicates the measured HVES or high side current measured at the point of control inside the DC/DC Converter.  The current is negative if the converter is charging the SLI battery from the hybrid battery.";
CM_ SG_ 2364609637 HiSideV "Indicates the measured HVES or high side voltage measured at the point of control inside the DC/DC Converter.";
CM_ SG_ 2364609637 LowSideCur "Indicates the measured SLI battery or low side current measured at the point of control inside the DC/DC Converter.  The current is positive if the converter is charging the SLI battery from the hybrid battery.";
CM_ SG_ 2364609637 LowSideV "Indicates the measured SLI battery or low side voltage measured at the point of control inside the DC/DC Converter.";
CM_ BO_ 2364609381 "DC/DC Converter 1 Operating Status
Contains information on the operating status of a DC/DC Converter.

One intended use of this message is for a conventional engine mounted alternator replacement.";
CM_ SG_ 2364609381 PLDueToUndefinedReason "Indicates whether or not output power is being limited due to an undefined reason.

00 - No power limit for this reason
01 - Power limited for this reason
10 - Error
11 - Not Available";
CM_ SG_ 2364609381 PLDueToSLIBatTermTemp "Indicates whether or not output power is being limited due to the SLI battery terminal temperature (see SPN 8591) approaching or exceeding limits (see SPN 8819).
00 - No power limit for this reason
01 - Power limited for this reason
10 - Error
 ...";
CM_ SG_ 2364609381 PLDueToSLIBatTermCur "Indicates whether or not output power is being limited due to the SLI battery terminal current (see SPN 8590) approaching or exceeding limits (see SPN 8818).
00 - No power limit for this reason
01 - Power limited for this reason
10 - Error
11 - ...";
CM_ SG_ 2364609381 PLDueToSLIBatTermV "Indicates whether or not output power is being limited due to the SLI battery terminal voltage (see SPN 8589) approaching or exceeding limits (see SPN 8817).
00 - No power limit for this reason
01 - Power limited for this reason
10 - Error
11 - ...";
CM_ SG_ 2364609381 PLDueToPwrETemp "Indicates whether or not output power is being limited due to Power Electronics Temperature (see SPN 8594) approaching or exceeding the maximum limit.
00 - No power limit for this reason
01 - Power limited for this reason
10 - Error
11 - Not ...";
CM_ SG_ 2364609381 PLDueToElectronicFilterTemp "Indicates whether or not output power is being limited due to Output Electronic Filter Temperature (see SPN 8693) approaching or exceeding the maximum limit.
00 - No power limit for this reason
01 - Power limited for this reason
10 - Error
11 - ...";
CM_ SG_ 2364609381 PLDueToCtrlTemp "Indicates whether or not output power is being limited due to Converter Temperature (see SPN 8592) approaching or exceeding the maximum limit.

00 - No power limit for this reason
01 - Power limited for this reason
10 - Error
11 - Not Available";
CM_ SG_ 2364609381 PLDueToLowSideVMax "Indicates whether or not output power is being limited due to low side voltage (see SPN 8585) approaching or exceeding the maximum limit (see SPN 8567).
00 - No power limit for this reason
01 - Power limited for this reason
10 - Error
11 - Not ...";
CM_ SG_ 2364609381 PLDueToLowSideVMin "Indicates whether or not output power is being limited due to low side voltage (see SPN 8585) approaching or falling below the minimum limit (see SPN 8566).
00 - No power limit for this reason
01 - Power limited for this reason
10 - Error
11 - ...";
CM_ SG_ 2364609381 PLDueToHiSideVMax "Indicates whether or not output power is being limited due to high side voltage (see SPN 8587) approaching or exceeding the maximum limit (see SPN 8564).
00 - No power limit for this reason
01 - Power limited for this reason
10 - Error
11 - Not ...";
CM_ SG_ 2364609381 PLDueToHiSideVMin "Indicates whether or not output power is being limited due to high side voltage (see SPN 8587) approaching or falling below the minimum limit (see SPN 8563).
00 - No power limit for this reason
01 - Power limited for this reason
10 - Error
11 - ...";
CM_ SG_ 2364609381 PLDueToLowSideCur "Indicates whether or not output power is being limited due to low side current (see SPN 8586) approaching or exceeding the maximum limit (see SPN 8568).
00 - No power limit for this reason
01 - Power limited for this reason
10 - Error
11 - Not ...";
CM_ SG_ 2364609381 PLDueToHiSideCur "Indicates whether or not output power is being limited due to high side current (see SPN 8588) approaching or exceeding the maximum limit (see SPN 8565).
00 - No power limit for this reason
01 - Power limited for this reason
10 - Error
11 - Not ...";
CM_ SG_ 2364609381 LoadshedReq "The loadshed request is a request to the controlling device to reduce the DC/DC Converter loads.  The Loadshed Requested state is an indication that this DC/DC Converter has a malfunction or is in a limit condition and if the load of the output is ...";
CM_ SG_ 2364609381 HVILStatus "High Voltage Interlock Loop (HVIL) state of the DC/DC Converter.

00 - HVIL Closed
01 - HVIL Open
10 - Error
11 - Not Available";
CM_ SG_ 2364609381 OperationalStatus "Operating state of the DC/DC Converter
0000 - Disabled
0001 - Initialization in process.  The device is powering up.  This process may include both internal checks, as well as system checks being run by the DC/DC Converter.
0010 - Operational - ...";
CM_ BO_ 2364609063 "DC/DC Converter 1 Control
Controls the transfer of energy between the HVES or high voltage system (i.e. high side) and the SLI battery or low voltage system (i.e. low side).  Provides a function to either charge the SLI Battery from the HVES (Buck) ...";
CM_ SG_ 2364609063 OneLowSideVBuckDefaultSetpoint "The set point for the converter default low side voltage during buck mode.   This setting may be used for when communication has been lost with the controlling device.  When set to Not Available (FFFFh), no default setting is provided and the system ...";
CM_ SG_ 2364609063 HiSideVBoostSetpoint "The set point for regulating the high side voltage during boost mode.";
CM_ SG_ 2364609063 LowSideVBuckSetpoint "The set point for regulating the low side voltage during buck mode.";
CM_ SG_ 2364609063 OperationalCmd "Command to enable or disable operation.
0000 - Disable - in this mode all high voltage switching is disabled
0001 - Operate in standby mode; system is waiting for command to enter buck or boost mode
0010 - Operate in buck mode; energy flows from ...";
CM_ SG_ 2566856743 Vb "Reports voltage of the monitored IT power system.  The reported value is averaged and updated every100 ms.";
CM_ SG_ 2566856743 Selector_state "0-neutral
1-reverse
2-drive";
CM_ SG_ 2566856723 VCVCCU_Vehicle_ContactorVoltage "Measured voltage at the contactor";
CM_ SG_ 2316304641 Restart "Restarts the operation of SIM100.";
CM_ SG_ 2316304641 Excitation_pulse_off "Sending 0xDEADBE1F with SIM_Request_mux = 0x62 disables the excitation pulse of the SIM100.   In order to re-enable it a Restart message has to be sent.";
CM_ SG_ 2316304641 Max_battery_working_voltage "Sets the maximum battery operating voltage (in Volts)";
CM_ BO_ 2316304640 "Response of SIM100 to Set Max_battery_working_voltage request from Host";
CM_ SG_ 2316304640 Max_battery_working_voltage "Sets the maximum battery operating voltage (in Volts)";
CM_ SG_ 2316304640 Hardware_Error "0 – No hardware error
1 – Hardware error. The host should perform a “Read SIM100 Error Flags” operation in order to resolve the issue";
CM_ SG_ 2316304640 Err_CH "0 - CH1 and CH2 connections are good (chassis connections)
1 - CH1 or CH2 connection is broken";
CM_ SG_ 2316304640 No_New_Estimates "0 – The flag is zero when new and unread isolation values have been calculated.
1 – Isolation values have not been updated since the last read. ";
CM_ SG_ 2316304640 High_Uncertaintly "0 – Uncertainty of calculated values is less than 5%
1 – Uncertainty values are higher than 5%.";
CM_ SG_ 2316304640 High_Battery_Voltage "0 – Observed battery voltage is less than the specified Maximum Working Voltage.
1 – The observed battery voltage value is higher than the specified maximum working voltage value.";
CM_ SG_ 2316304640 Low_Battery_Voltage "0 – Observed battery voltage higher than 15 V
1 – Observed battery voltage less than 15 V.";
CM_ SG_ 2316304640 Isolation_status_bits "00 – Isolation status OK
10 – Warning. Isolation resistance < 500 Ohm/V limit.
11- Isolation fault. Isolation resistance <100 Ohm/V limit.";
CM_ SG_ 2316304640 Err_Vpwr "0 - Power supply level is good
1 - Power supply level is out of range";
CM_ SG_ 2316304640 Err_Vexi "0 - Excitation voltage level is correct
1 - Excitation voltage level is out of specs";
CM_ SG_ 2316304640 Err_VxR "0 - VX1 and VX2 connections are correct
1 - VX1 and VX2 connections are reversed";
CM_ SG_ 2316304640 Err_Vx1 "0 - VX1 connection is good (SIM100 to battery positive terminal connection)
1 - VX1 connection is brokenCH0";
CM_ SG_ 2316304640 Err_Vx2 "0 - VX2 connection is good (SIM100 to battery negative terminal connection)
1 - VX2 connection is broken";
CM_ SG_ 2316304640 Vb_max "Maximum value of IT power supply.  Must be set by the Host.  If not set by Host it becomes the maximum actual value recorded by SIM100MOD.  ";
CM_ SG_ 2316304640 Vb "Reports voltage of the monitored IT power system.  The reported value is averaged and updated every100 ms.";
CM_ SG_ 2316304640 Vn "Potential between negative IT system power rail and chassis.  
Value is the average between two readings by the Host.  It is updated every 10 ms. 
If two successive readings occur faster than 10 ms  SIM100 will report the previous value.";
CM_ SG_ 2316304640 Vp "Potential between positive IT system power rail and chassis.  
Value is the average between two readings by the Host.  It is updated every 10 ms. 
If two successive readings occur faster than 10 ms  SIM100 will report the previously calculated value.";
CM_ SG_ 2316304640 Cn_uncertainty "Cn estimate uncertainty expressed in %";
CM_ SG_ 2316304640 Cn "Estimated value of capacitances Cn in nF. 
";
CM_ SG_ 2316304640 Cp_uncertainty "Cp estimate uncertainty expressed in % 
If the battery voltage is below 15 Volts or the battery is disconnected Cp returns the parallel combination value of Cp||Cn, and Cn returns 0xFFFF with uncertainty for Cn set to 0x00.";
CM_ SG_ 2316304640 Cp "Estimated values of capacitance Cp.
";
CM_ SG_ 2316304640 Energy_stored "This is the maximum energy that can be stored in the parallel combination of Y capacitors between the battery and chassis at the maximum working voltage.";
CM_ SG_ 2316304640 Electrical_isolation "Minimum resistance isolation path between the IT grounded system and the chassis. The value is calculated based on the battery’s Maximum Working Voltage.";
CM_ SG_ 2316304640 OpCode_mux "Identifies the contents of the message";
CM_ SG_ 2566855296 VCVCCU_PlugPresent_Voltage "Measured voltage value of proximity pin signal";
CM_ SG_ 2566871680 VCVCCU_V2G_EVSEPresentVoltage_Va "Present voltage of EVSE";
CM_ SG_ 2566871936 VCVCCU_V2G_DateTimeNow "Timestamp of the current SECC time using to the Unix Time Stamp format.";
CM_ SG_ 2566871168 VCVCCU_V2G_EVSEPeakCurrentR_0002 "Peak-to-peak magnitude of the current ripple of the EVSE";
CM_ SG_ 2566870912 VCVCCU_V2G_EVSEMinimumVolta_0002 "Minimum voltage the EVSE can deliver with the expected accuracy";
CM_ SG_ 2566870656 VCVCCU_V2G_EVSEMinimumCurre_0002 "Minimum current the EVSE can deliver with the expected accuracy";
CM_ SG_ 2566870400 VCVCCU_V2G_EVSEMaximumVolta_0003 "Maximum voltage the EVSE can deliver";
CM_ SG_ 2566870144 VCVCCU_V2G_EVSEMaximumPower_0003 "Maximum power the EVSE can deliver";
CM_ SG_ 2566869888 VCVCCU_V2G_EVSEMaximumCurre_0000 "Maximum current the EVSE can deliver";
CM_ SG_ 2566869632 VCVCCU_V2G_EVSEEnergyToBeDe_0000 "Amount of energy to be delivered by the EVSE";
CM_ SG_ 2566869376 VCVCCU_V2G_EVSECurrentRegul_0000 "Absolute magnitude of the regulation tolerance of the EVSE";
CM_ SG_ 2566863234 VCVCCU_V2G_EVMaximumVoltage_0000 "Maximum voltage supported by the EV";
CM_ SG_ 2566862978 VCVCCU_V2G_EVMaximumPowerLimit_V "Maximum power supported by the EV";
CM_ SG_ 2566862722 VCVCCU_V2G_EVMaximumCurrent_0003 "Maximum current supported by the EV";
CM_ SG_ 2566862466 VCVCCU_V2G_EVEnergyRequest_Value "Amount of energy the EV requests from the EVSE";
CM_ SG_ 2566862210 VCVCCU_V2G_EVEnergyCapacity_Valu "Maximum energy capacity supported by the EV";
CM_ SG_ 2566869120 VCVCCU_V2G_ResponseCode "Response Code indicating the acknowledgment status of any of the V2G messages received by the SECC.";
CM_ SG_ 2566869120 VCVCCU_V2G_NotificationMaxDelay "The SECC uses the NotificationMaxDelay element in the EVSEStatus to indicate the time until it expects the EVCC to react on the action request indicated in EVSENotification. To be performed immediately if time is in past.";
CM_ SG_ 2566869120 VCVCCU_V2G_EVSEPowerLimitAchieve "If set to TRUE, the EVSE has reached its power limit";
CM_ SG_ 2566869120 VCVCCU_V2G_EVSEVoltageLimitAchie "If set to TRUE, the EVSE has reached its voltage limit";
CM_ SG_ 2566869120 VCVCCU_V2G_EVSEStatusCode "Indicates if the internal state of the EVSE";
CM_ SG_ 2566869120 VCVCCU_V2G_EVSEProcessing "Parameter  indicating  that  the EVSE has finished the processing that  was  initiated  after  the ContractAuthenticationReq or that  the EVSE is still processing at the time  the  response  message  was sent.";
CM_ SG_ 2566869120 VCVCCU_V2G_EVSENotification "This value is used by the SECC to influence the behaviour of the EVCC. The EVSENotification contains an action that the SECC wants the EVCC to perform within time provided in NotificationMaxDelay. To be performed immediately if time is in past.";
CM_ SG_ 2566869120 VCVCCU_V2G_EVSEIsolationStatus "Indicates the isolation condition (result of the isolation test/monitoring). ";
CM_ SG_ 2566869120 VCVCCU_V2G_EVSECurrentLimitAchie "If set to TRUE, the EVSE has reached its current limit. ";
CM_ SG_ 2566861954 VCVCCU_V2G_EVTargetCurrent_Value "Current demanded by EV";
CM_ SG_ 2566861698 VCVCCU_V2G_EVTargetVoltage_Value "Target Voltage requested by EV";
CM_ SG_ 2566861442 VCVCCU_V2G_RemainingTimeToB_0000 "Estimated or calculated time until bulk charge (approx. 80 % SOC) is complete";
CM_ SG_ 2566861186 VCVCCU_V2G_RemainingTimeToF_0000 "Estimated or calculated time until full charge (100 % SOC) is complete";
CM_ SG_ 2566860930 VCVCCU_V2G_StateM_EnergyTra_0000 "Selected energy transfer mode";
CM_ SG_ 2566860930 VCVCCU_V2G_EVErrorCode "Indicates the EV internal status.";
CM_ SG_ 2566860930 VCVCCU_V2G_EVRESSSOC "State of charge of the EVâ€™s battery (RESS) ";
CM_ SG_ 2566860930 VCVCCU_V2G_EVRESSConditioning "Vehicle RESS Conditioning, The vehicle is using energyfrom the DC charger to condition the RESS to a target temperature.";
CM_ SG_ 2566860930 VCVCCU_V2G_EVReady "If set to TRUE, the EV is ready to charge. ";
CM_ SG_ 2566860930 VCVCCU_V2G_EVCabinConditioning "Vehicle Cabin Conditioning, The EV is using energy from the DC supply to heat or cool the passenger compartment. ";
CM_ SG_ 2566860930 VCVCCU_V2G_ChargingComplete "If set to TRUE, the EV indicates that full  charge  (100 %  SOC)  is complete.";
CM_ SG_ 2566860930 VCVCCU_V2G_FullSOC "SOC at which the EV considers the battery to be fully charged ";
CM_ SG_ 2566860930 VCVCCU_V2G_BulkSOC "SOC at which the EV considers a fast charging process to end";
CM_ SG_ 2566860930 VCVCCU_V2G_BulkChargingComplete "If set to TRUE, the EV indicates that bulk charge (approx. 80 % SOC) is complete.";
CM_ SG_ 2566857090 VCVCCU_Vehicle_ContactorStatus "Status of the Charging contactors";
CM_ SG_ 2566857090 VCVCCU_Vehicle_LinkVoltage "Measured voltage at the battery";
CM_ SG_ 2566857090 VCVCCU_Vehicle_IsolationMeasurem "Vehicle isolation measurement status";
CM_ SG_ 2566857090 VCVCCU_Vehicle_ContactorVoltage "Measured voltage at the contactor";
CM_ SG_ 2566857090 VCVCCU_Vehicle_PlugUnlockPermiss "Permission from the vehicle to unlock the plug";
CM_ SG_ 2566857090 VCVCCU_Vehicle_PlugLockPermissio "Permission from the vehicle to lock the plug";
CM_ SG_ 2566857090 VCVCCU_Vehicle_ChargePermission "Permission from the vehicle to charge";
CM_ SG_ 2566854528 VCVCCU_Vehicle_ContactorRequest "Request for the Charging contactors";
CM_ SG_ 2566854528 IsolationMeasurement_request "Vehicle isolation measurement request";
CM_ SG_ 2566856834 VCVCCU_Inlet_MotorRequest "Requests to control the inlet motor";
CM_ SG_ 2566856834 VCVCCU_ChargeUnit_Request "Charging mode control of CP";
CM_ SG_ 2566856834 VCVCCU_RTC_TimerValue "RTC timer value";
CM_ SG_ 2566856834 VCVCCU_RTC_TimerRequest "RTC timer request";
CM_ SG_ 2566856834 VCVCCU_PlugLock_MotorRequest "Request for the plug lock motor movement";
CM_ SG_ 2566856834 VCVCCU_LED2_Request "Request for the duty cycle of the LED2";
CM_ SG_ 2566856834 VCVCCU_LED1_Request "Request for the duty cycle of the LED1";
CM_ SG_ 2566856834 VCVCCU_LED0_Request "Request for the duty cycle of the LED0";
CM_ SG_ 2566856834 VCVCCU_HighSideOut4_Request "Request for high side output 4";
CM_ SG_ 2566856834 VCVCCU_HighSideOut3_Request "Request for high side output 3";
CM_ SG_ 2566856834 VCVCCU_HighSideOut2_Request "Request for high side output 2";
CM_ SG_ 2566856834 VCVCCU_HighSideOut1_Request "Request for high side output 1";
CM_ SG_ 2566856834 VCVCCU_HighSideOut0_Request "Request for high side output 0";
CM_ SG_ 2566856834 VCVCCU_ControlPilot_ChargeModeRe "Value of the resistor connected to the Control Pilot which defines the mode used";
CM_ SG_ 2566854272 VCVCCU_RTC_Wakeup "Wakeup detection of RTC";
CM_ SG_ 2566854272 VCVCCU_RTC_TimerStatus "Timer status of RTC";
CM_ SG_ 2566854016 VCVCCU_HighSideOut3_Input_Wakeup "Wakeup detection of high side 3 input signal";
CM_ SG_ 2566854016 VCVCCU_HighSideOut4_Input_Status "Status of the high side 4 input signal";
CM_ SG_ 2566854016 VCVCCU_HighSideOut4_Input_Deboun "Debounced status of the high side 4 input signal";
CM_ SG_ 2566854016 VCVCCU_HighSideOut3_Input_Status "Status of the high side 3 input signal";
CM_ SG_ 2566854016 VCVCCU_HighSideOut3_Input_Deboun "Debounced status of the high side 3 input signal";
CM_ SG_ 2566854016 VCVCCU_HighSideOut2_Input_Status "Status of the high side 2 input signal";
CM_ SG_ 2566854016 VCVCCU_HighSideOut2_Input_Deboun "Debounced status of the high side 2 input signal";
CM_ SG_ 2566854016 VCVCCU_HighSideOut1_Input_Status "Status of the high side 1 input signal";
CM_ SG_ 2566854016 VCVCCU_HighSideOut1_Input_Deboun "Debounced status of the high side 1 input signal";
CM_ SG_ 2566854016 VCVCCU_HighSideOut0_Input_Status "Status of the high side 0 input signal";
CM_ SG_ 2566854016 VCVCCU_HighSideOut0_Input_Deboun "Debounced status of the high side 0 input signal";
CM_ SG_ 2566854016 VCVCCU_LED2_SelfDiagnosticStatus "SelfDiagnosticStatus of LED output 2";
CM_ SG_ 2566854016 VCVCCU_LED1_SelfDiagnosticStatus "SelfDiagnosticStatus of LED output 1";
CM_ SG_ 2566854016 VCVCCU_LED0_SelfDiagnosticStatus "SelfDiagnosticStatus of LED output 0";
CM_ SG_ 2566854016 VCVCCU_HighSideOut4_SelfDiagnost "SelfDiagnosticStatus of high side output 4";
CM_ SG_ 2566854016 VCVCCU_HighSideOut3_SelfDiagnost "SelfDiagnosticStatus of high side output 3";
CM_ SG_ 2566854016 VCVCCU_HighSideOut2_SelfDiagnost "SelfDiagnosticStatus of high side output 2";
CM_ SG_ 2566854016 VCVCCU_HighSideOut1_SelfDiagnost "SelfDiagnosticStatus of high side output 1";
CM_ SG_ 2566854016 VCVCCU_HighSideOut0_SelfDiagnost "SelfDiagnosticStatus of high side output 0";
CM_ SG_ 2566853760 VCVCCU_ChargeUnit_State "Vehicle state derived from CP voltage and duty cycle";
CM_ SG_ 2566853760 VCVCCU_ChargeUnit_Mode "Requested charging mode from the EVSE, derived from the CP duty cycle";
CM_ SG_ 2566853760 VCVCCU_ChargeUnit_MaxCurrent "Max current derived from CP duty cycle";
CM_ SG_ 2566853760 VCVCCU_ControlPilot_Wakeup "Wakeup detection of control pilot signal";
CM_ SG_ 2566853760 VCVCCU_ControlPilot_Voltage "Measured voltage value of control pilot signal";
CM_ SG_ 2566853760 VCVCCU_ControlPilot_Frequency "Measured frequency value of control pilot signal";
CM_ SG_ 2566853760 VCVCCU_ControlPilot_DutyCycle "Duty cycle of the Control Pilot signal";
CM_ SG_ 2566853504 VCVCCU_Inlet_HWVariant "Status of the digital input signal";
CM_ SG_ 2566853504 VCVCCU_S3Switch_Status "Status of the S3 switch signal";
CM_ SG_ 2566853504 VCVCCU_S3Switch_DebouncedStatus "Debounced status of the S3 switch signal";
CM_ SG_ 2566853504 VCVCCU_DigitalInput_DebouncedSta "Debounced status of the digital input signal";
CM_ SG_ 2566853504 VCVCCU_Inlet_MaxCurrent "Max current derived from PP resistance";
CM_ SG_ 2566853504 VCVCCU_Inlet_MotorStatus "Inlet lock status";
CM_ SG_ 2566853504 VCVCCU_Inlet_ConnectionStatus "Inlet connection state derived from PP and CP";
CM_ SG_ 2566853504 VCVCCU_PlugPresent_Wakeup "Wakeup detection of proximity pin signal";
CM_ SG_ 2566853504 VCVCCU_PlugPresent_Status "Proximity Pin detection";
CM_ SG_ 2566853504 VCVCCU_POSFeedback_SelfDiagnosti "SelfDiagnosticStatus of position feedback signal";
CM_ SG_ 2566853504 VCVCCU_PlugPresent_SelfDiagnosti "SelfDiagnostic Status of proximity pin signal";
CM_ SG_ 2566853504 VCVCCU_DigitalInput_Wakeup "Wakeup detection of digital input signal";
CM_ SG_ 2566853504 VCVCCU_PlugPresent_Resistance "Value of the resistor connected to the Proximity Pin which defines the diameter of the cable";
CM_ SG_ 2566853504 VCVCCU_PlugLock_Output1_SelfDiag "SelfDiagnosticStatus of full bridge output 0";
CM_ SG_ 2566853504 VCVCCU_DigitalInput_Status "Status of the digital input signal";
CM_ SG_ 2566853504 VCVCCU_PlugLock_Output0_SelfDiag "SelfDiagnosticStatus of full bridge output 0";
CM_ SG_ 2566853504 VCVCCU_PlugLock_MotorStatus "Status of the plug lock motor movement";
CM_ SG_ 2566853504 VCVCCU_POSFeedback_Voltage "Measured voltage value of position feedback signal";
CM_ SG_ 2566853248 VCVCCU_PTC2_SelfDiagnosticStatus "SelfDiagnosticStatus of PTC2 signal";
CM_ SG_ 2566853248 VCVCCU_PTC2_Temperature "Temperature measurement inside the inlet";
CM_ SG_ 2566853248 VCVCCU_PTC2_Resistance "Measured resistance value of PTC2";
CM_ SG_ 2566853248 VCVCCU_PTC2_Raw "Measured raw value of PTC2";
CM_ SG_ 2566852992 VCVCCU_PTC1_SelfDiagnosticStatus "SelfDiagnosticStatus of PTC1 signal";
CM_ SG_ 2566852992 VCVCCU_PTC1_Temperature "Temperature measurement inside the inlet";
CM_ SG_ 2566852992 VCVCCU_PTC1_Resistance "Measured resistance value of PTC1";
CM_ SG_ 2566852992 VCVCCU_PTC1_Raw "Measured raw value of PTC1";
CM_ BO_ 2363228034 "Request message for UDS Diagnostic";
CM_ SG_ 2363228034 DIAG_REQ_GLOBAL "Request message for UDS Diagnostic";
CM_ BO_ 2566910080 "Response message for XCP Protocol";
CM_ SG_ 2566910080 XCP_RESP_VCCU "Response message for XCP Protocol";
CM_ BO_ 2566910082 "Request message for XCP Protocol";
CM_ SG_ 2566910082 XCP_REQ_VCCU "Request message for XCP Protocol";
CM_ BO_ 2363129984 "Response message for UDS Diagnostic";
CM_ SG_ 2363129984 DIAG_RESP_VCCU "Response message for UDS Diagnostic";
CM_ BO_ 2633990272 "ASR NM message";
CM_ SG_ 2566834816 DTC_FailModeID_VCCU "The FMI defines the type of failure detected in the subsystem identified by an SPN.";
CM_ SG_ 2566834816 DTC_SPN_ConvMd_VCCU "SPN Conversion Method";
CM_ SG_ 2566834816 DTC_OccCnt_VCCU "Occurrence Count";
CM_ SG_ 2566834816 DTC_SPN_VCCU "This 19-bit number is used to identify the item for which diagnostics are being reported.";
CM_ SG_ 2566834816 DTC_RSL_Flash_Stat_VCCU "Flash Red Stop Lamp";
CM_ SG_ 2566834816 DTC_PL_Flash_Stat_VCCU "Flash Protect Lamp";
CM_ SG_ 2566834816 DTC_RSL_Stat_VCCU "Red Stop Lamp Status";
CM_ SG_ 2566834816 DTC_PL_Stat_VCCU "Protect Lamp Status";
CM_ SG_ 2566834816 DTC_MIL_Stat_VCCU "Malfunction Indicator Lamp Status";
CM_ SG_ 2566834816 DTC_MIL_Flash_Stat_VCCU "Flash Malfunction Indicator Lamp";
CM_ SG_ 2566834816 DTC_AWL_Flash_Stat_VCCU "Flash Amber Warning Lamp";
CM_ SG_ 2566834816 DTC_AWL_Stat_VCCU "Amber Warning Lamp Status";
CM_ SG_ 2566852736 VCVCCU_PTC0_SelfDiagnosticStatus "SelfDiagnosticStatus of PTC0 signal";
CM_ SG_ 2566852736 VCVCCU_PTC0_Resistance "Measured resistance value of PTC0";
CM_ SG_ 2566852736 VCVCCU_PTC0_Raw "Measured raw value of PTC0";
CM_ SG_ 2566852736 VCVCCU_PTC0_Temperature "Temperature measurement inside the inlet";
CM_ SG_ 2566866213 BMS_HighVoltage_relay_stat "00 Disconnect 01 closed 10 invalid 11 invalid";
BA_DEF_ SG_  "SPN" INT 0 524287;
BA_DEF_ BO_  "VFrameFormat" ENUM  "StandardCAN","ExtendedCAN","reserved","J1939PG";
BA_DEF_ SG_  "SigType" ENUM  "Default","Range","RangeSigned","ASCII","Discrete","Control","ReferencePGN","DTC","StringDelimiter","StringLength","StringLengthControl","MessageCounter","MessageChecksum";
BA_DEF_ SG_  "GenSigEVName" STRING ;
BA_DEF_ SG_  "GenSigILSupport" ENUM  "No","Yes";
BA_DEF_ SG_  "GenSigSendType" ENUM  "Cyclic","OnWrite","OnWriteWithRepetition","OnChange","OnChangeWithRepetition","IfActive","IfActiveWithRepetition","NoSigSendType";
BA_DEF_ SG_  "GenSigStartValue" INT 0 10000;
BA_DEF_ BO_  "GenMsgILSupport" ENUM  "No","Yes";
BA_DEF_ BO_  "GenMsgStartDelayTime" INT 0 100000;
BA_DEF_ BO_  "GenMsgSendType" ENUM  "cyclic","NotUsed","NotUsed","NotUsed","NotUsed","NotUsed","NotUsed","IfActive","noMsgSendType";
BA_DEF_ BO_  "GenMsgRequestable" INT 0 1;
BA_DEF_ BO_  "GenMsgCycleTime" INT 0 3600000;
BA_DEF_ SG_  "SystemSignalLongSymbol" STRING ;
BA_DEF_DEF_  "SPN" 0;
BA_DEF_DEF_  "VFrameFormat" "J1939PG";
BA_DEF_DEF_  "SigType" "Default";
BA_DEF_DEF_  "GenSigEVName" "Env@Nodename_@Signame";
BA_DEF_DEF_  "GenSigILSupport" "Yes";
BA_DEF_DEF_  "GenSigSendType" "NoSigSendType";
BA_DEF_DEF_  "GenSigStartValue" 0;
BA_DEF_DEF_  "GenMsgILSupport" "Yes";
BA_DEF_DEF_  "GenMsgStartDelayTime" 0;
BA_DEF_DEF_  "GenMsgSendType" "noMsgSendType";
BA_DEF_DEF_  "GenMsgRequestable" 1;
BA_DEF_DEF_  "GenMsgCycleTime" 0;
BA_DEF_DEF_  "SystemSignalLongSymbol" "";
BA_ "VFrameFormat" BO_ 2566913829 1;
BA_ "VFrameFormat" BO_ 2566913573 1;
BA_ "VFrameFormat" BO_ 2566913317 1;
BA_ "VFrameFormat" BO_ 2566913061 1;
BA_ "VFrameFormat" BO_ 2566912805 1;
BA_ "VFrameFormat" BO_ 2566912549 1;
BA_ "VFrameFormat" BO_ 2566912293 1;
BA_ "VFrameFormat" BO_ 2566912037 1;
BA_ "VFrameFormat" BO_ 2566911781 1;
BA_ "VFrameFormat" BO_ 2566911525 1;
BA_ "VFrameFormat" BO_ 2566911269 1;
BA_ "VFrameFormat" BO_ 2566911013 1;
BA_ "VFrameFormat" BO_ 2566910757 1;
BA_ "VFrameFormat" BO_ 2566910501 1;
BA_ "VFrameFormat" BO_ 2566910245 1;
BA_ "VFrameFormat" BO_ 2566861349 1;
BA_ "VFrameFormat" BO_ 2566861093 1;
BA_ "VFrameFormat" BO_ 2566832423 1;
BA_ "VFrameFormat" BO_ 2566841895 1;
BA_ "VFrameFormat" BO_ 2566856487 1;
BA_ "GenMsgSendType" BO_ 2364609638 0;
BA_ "GenMsgCycleTime" BO_ 2364609638 100;
BA_ "VFrameFormat" BO_ 2364609638 1;
BA_ "GenMsgSendType" BO_ 2365297510 0;
BA_ "GenMsgCycleTime" BO_ 2365297510 100;
BA_ "VFrameFormat" BO_ 2365297510 1;
BA_ "GenMsgSendType" BO_ 2365315174 0;
BA_ "GenMsgCycleTime" BO_ 2365315174 1000;
BA_ "VFrameFormat" BO_ 2365315174 1;
BA_ "GenMsgSendType" BO_ 2364609382 0;
BA_ "GenMsgCycleTime" BO_ 2364609382 100;
BA_ "VFrameFormat" BO_ 2364609382 1;
BA_ "GenMsgSendType" BO_ 2365315430 0;
BA_ "GenMsgCycleTime" BO_ 2365315430 1000;
BA_ "VFrameFormat" BO_ 2365315430 1;
BA_ "VFrameFormat" BO_ 2348941054 1;
BA_ "VFrameFormat" BO_ 2147483800 1;
BA_ "VFrameFormat" BO_ 2147483801 1;
BA_ "VFrameFormat" BO_ 2147483682 1;
BA_ "VFrameFormat" BO_ 2147483681 1;
BA_ "VFrameFormat" BO_ 2147483668 1;
BA_ "VFrameFormat" BO_ 2147483667 1;
BA_ "VFrameFormat" BO_ 2566874233 1;
BA_ "VFrameFormat" BO_ 2147483673 1;
BA_ "GenMsgSendType" BO_ 2566857246 0;
BA_ "GenMsgCycleTime" BO_ 2566857246 1000;
BA_ "VFrameFormat" BO_ 2566857246 1;
BA_ "GenMsgSendType" BO_ 2566856990 0;
BA_ "GenMsgCycleTime" BO_ 2566856990 1000;
BA_ "VFrameFormat" BO_ 2566856990 1;
BA_ "VFrameFormat" BO_ 2365526823 1;
BA_ "VFrameFormat" BO_ 2365526567 1;
BA_ "VFrameFormat" BO_ 2566851367 1;
BA_ "GenMsgSendType" BO_ 2365297509 0;
BA_ "GenMsgCycleTime" BO_ 2365297509 100;
BA_ "VFrameFormat" BO_ 2365297509 1;
BA_ "GenMsgSendType" BO_ 2364610599 0;
BA_ "GenMsgCycleTime" BO_ 2364610599 100;
BA_ "VFrameFormat" BO_ 2364610599 1;
BA_ "GenMsgSendType" BO_ 2365315429 0;
BA_ "GenMsgCycleTime" BO_ 2365315429 1000;
BA_ "VFrameFormat" BO_ 2365315429 1;
BA_ "GenMsgSendType" BO_ 2365315173 0;
BA_ "GenMsgCycleTime" BO_ 2365315173 1000;
BA_ "VFrameFormat" BO_ 2365315173 1;
BA_ "GenMsgSendType" BO_ 2364609637 0;
BA_ "GenMsgCycleTime" BO_ 2364609637 100;
BA_ "VFrameFormat" BO_ 2364609637 1;
BA_ "GenMsgSendType" BO_ 2364609381 0;
BA_ "GenMsgCycleTime" BO_ 2364609381 100;
BA_ "VFrameFormat" BO_ 2364609381 1;
BA_ "GenMsgSendType" BO_ 2364609063 0;
BA_ "GenMsgCycleTime" BO_ 2364609063 100;
BA_ "VFrameFormat" BO_ 2364609063 1;
BA_ "VFrameFormat" BO_ 2566856743 1;
BA_ "VFrameFormat" BO_ 2566856723 1;
BA_ "VFrameFormat" BO_ 2316304641 1;
BA_ "VFrameFormat" BO_ 2316304640 1;
BA_ "VFrameFormat" BO_ 2566855296 1;
BA_ "VFrameFormat" BO_ 2566855040 1;
BA_ "VFrameFormat" BO_ 2566854784 1;
BA_ "VFrameFormat" BO_ 2566865026 1;
BA_ "VFrameFormat" BO_ 2566872448 1;
BA_ "VFrameFormat" BO_ 2566872192 1;
BA_ "VFrameFormat" BO_ 2566871680 1;
BA_ "VFrameFormat" BO_ 2566871936 1;
BA_ "VFrameFormat" BO_ 2566871424 1;
BA_ "VFrameFormat" BO_ 2566871168 1;
BA_ "VFrameFormat" BO_ 2566870912 1;
BA_ "VFrameFormat" BO_ 2566870656 1;
BA_ "VFrameFormat" BO_ 2566870400 1;
BA_ "VFrameFormat" BO_ 2566870144 1;
BA_ "VFrameFormat" BO_ 2566869888 1;
BA_ "VFrameFormat" BO_ 2566869632 1;
BA_ "VFrameFormat" BO_ 2566869376 1;
BA_ "VFrameFormat" BO_ 2566863234 1;
BA_ "VFrameFormat" BO_ 2566862978 1;
BA_ "VFrameFormat" BO_ 2566862722 1;
BA_ "VFrameFormat" BO_ 2566862466 1;
BA_ "VFrameFormat" BO_ 2566862210 1;
BA_ "VFrameFormat" BO_ 2566869120 1;
BA_ "VFrameFormat" BO_ 2566861954 1;
BA_ "VFrameFormat" BO_ 2566861698 1;
BA_ "VFrameFormat" BO_ 2566861442 1;
BA_ "VFrameFormat" BO_ 2566861186 1;
BA_ "VFrameFormat" BO_ 2566860930 1;
BA_ "VFrameFormat" BO_ 2566857090 1;
BA_ "VFrameFormat" BO_ 2566854528 1;
BA_ "VFrameFormat" BO_ 2566856834 1;
BA_ "VFrameFormat" BO_ 2566854272 1;
BA_ "VFrameFormat" BO_ 2566854016 1;
BA_ "VFrameFormat" BO_ 2566853760 1;
BA_ "VFrameFormat" BO_ 2566853504 1;
BA_ "VFrameFormat" BO_ 2566853248 1;
BA_ "VFrameFormat" BO_ 2566852992 1;
BA_ "VFrameFormat" BO_ 2363228034 1;
BA_ "VFrameFormat" BO_ 2566910080 1;
BA_ "VFrameFormat" BO_ 2566910082 1;
BA_ "VFrameFormat" BO_ 2363129984 1;
BA_ "VFrameFormat" BO_ 2633990272 1;
BA_ "VFrameFormat" BO_ 2566834816 1;
BA_ "VFrameFormat" BO_ 2566852736 1;
BA_ "VFrameFormat" BO_ 2566866213 1;
BA_ "VFrameFormat" BO_ 2566897978 1;
BA_ "SystemSignalLongSymbol" SG_ 2566913829 Signal_BSC_Power_Distributi_0004 "Signal_BSC_Power_Distribution_Status_15";
BA_ "SystemSignalLongSymbol" SG_ 2566913573 Signal_BSC_Power_Distributi_0005 "Signal_BSC_Power_Distribution_Status_14";
BA_ "SystemSignalLongSymbol" SG_ 2566913317 Signal_BSC_Power_Distributi_0006 "Signal_BSC_Power_Distribution_Status_13";
BA_ "SystemSignalLongSymbol" SG_ 2566913061 Signal_BSC_Power_Distributi_0007 "Signal_BSC_Power_Distribution_Status_12";
BA_ "SystemSignalLongSymbol" SG_ 2566912805 Signal_BSC_Power_Distributi_0008 "Signal_BSC_Power_Distribution_Status_11";
BA_ "SystemSignalLongSymbol" SG_ 2566912549 Signal_BSC_Power_Distributi_0009 "Signal_BSC_Power_Distribution_Status_10";
BA_ "SystemSignalLongSymbol" SG_ 2566912293 Signal_BSC_Power_Distributi_0010 "Signal_BSC_Power_Distribution_Status_09";
BA_ "SystemSignalLongSymbol" SG_ 2566912037 Signal_BSC_Power_Distributi_0011 "Signal_BSC_Power_Distribution_Status_08";
BA_ "SystemSignalLongSymbol" SG_ 2566911781 Signal_BSC_Power_Distributi_0012 "Signal_BSC_Power_Distribution_Status_07";
BA_ "SystemSignalLongSymbol" SG_ 2566911525 Signal_BSC_Power_Distributi_0013 "Signal_BSC_Power_Distribution_Status_06";
BA_ "SystemSignalLongSymbol" SG_ 2566911269 Signal_BSC_Power_Distributi_0014 "Signal_BSC_Power_Distribution_Status_05";
BA_ "SystemSignalLongSymbol" SG_ 2566911013 Signal_BSC_Power_Distributi_0015 "Signal_BSC_Power_Distribution_Status_04";
BA_ "SystemSignalLongSymbol" SG_ 2566910757 Signal_BSC_Power_Distributi_0016 "Signal_BSC_Power_Distribution_Status_03";
BA_ "SystemSignalLongSymbol" SG_ 2566910501 Signal_BSC_Power_Distributi_0017 "Signal_BSC_Power_Distribution_Status_02";
BA_ "SystemSignalLongSymbol" SG_ 2566910245 Signal_BSC_Power_Distributi_0018 "Signal_BSC_Power_Distribution_Status_01";
BA_ "GenSigStartValue" SG_ 2566861349 MinimumBatterySystemTemperature 40;
BA_ "GenSigStartValue" SG_ 2566861349 MaximumBatterySystemTemperature 40;
BA_ "GenSigStartValue" SG_ 2566861349 BatteryOutletWaterTemperatureReq 40;
BA_ "SystemSignalLongSymbol" SG_ 2566861349 BatteryOutletWaterTemperatureReq "BatteryOutletWaterTemperatureRequest";
BA_ "SystemSignalLongSymbol" SG_ 2566861093 MaximumBatterySystemDischargeCur "MaximumBatterySystemDischargeCurrent";
BA_ "SystemSignalLongSymbol" SG_ 2566861093 MaximumBatterySystemChargeC_0000 "MaximumBatterySystemChargeCurrent";
BA_ "GenSigStartValue" SG_ 2566861093 ActualBatterySystemCurrent 125;
BA_ "GenSigStartValue" SG_ 2566841895 LocalMinuteOffset 125;
BA_ "GenSigStartValue" SG_ 2566841895 LocalHourOffset 125;
BA_ "SigType" SG_ 2364609638 HiSideCur 1;
BA_ "SPN" SG_ 2364609638 HiSideCur 8588;
BA_ "SigType" SG_ 2364609638 HiSideV 1;
BA_ "SPN" SG_ 2364609638 HiSideV 8587;
BA_ "SigType" SG_ 2364609638 LowSideCur 1;
BA_ "SPN" SG_ 2364609638 LowSideCur 8586;
BA_ "SigType" SG_ 2364609638 LowSideV 1;
BA_ "SPN" SG_ 2364609638 LowSideV 8585;
BA_ "SigType" SG_ 2365297510 OneCtrlInputSLIV 1;
BA_ "SPN" SG_ 2365297510 OneCtrlInputSLIV 9559;
BA_ "SigType" SG_ 2365297510 OneCtrlInputIgntV 1;
BA_ "SPN" SG_ 2365297510 OneCtrlInputIgntV 9558;
BA_ "SigType" SG_ 2365315174 OneCoolantOutTemp 1;
BA_ "SPN" SG_ 2365315174 OneCoolantOutTemp 8823;
BA_ "SigType" SG_ 2365315174 OneCoolantInTemp 1;
BA_ "SPN" SG_ 2365315174 OneCoolantInTemp 8822;
BA_ "SigType" SG_ 2365315174 PwrETemp 1;
BA_ "SPN" SG_ 2365315174 PwrETemp 8594;
BA_ "SigType" SG_ 2365315174 ElectronicFilterTemp 1;
BA_ "SPN" SG_ 2365315174 ElectronicFilterTemp 8593;
BA_ "SigType" SG_ 2365315174 Temp 1;
BA_ "SPN" SG_ 2365315174 Temp 8592;
BA_ "SigType" SG_ 2364609382 PLDueToUndefinedReason 4;
BA_ "SPN" SG_ 2364609382 PLDueToUndefinedReason 8584;
BA_ "SigType" SG_ 2364609382 PLDueToSLIBatTermTemp 4;
BA_ "SPN" SG_ 2364609382 PLDueToSLIBatTermTemp 8582;
BA_ "SigType" SG_ 2364609382 PLDueToSLIBatTermCur 4;
BA_ "SPN" SG_ 2364609382 PLDueToSLIBatTermCur 8583;
BA_ "SigType" SG_ 2364609382 PLDueToSLIBatTermV 4;
BA_ "SPN" SG_ 2364609382 PLDueToSLIBatTermV 8581;
BA_ "SigType" SG_ 2364609382 PLDueToPwrETemp 4;
BA_ "SPN" SG_ 2364609382 PLDueToPwrETemp 8580;
BA_ "SigType" SG_ 2364609382 PLDueToElectronicFilterTemp 4;
BA_ "SPN" SG_ 2364609382 PLDueToElectronicFilterTemp 8579;
BA_ "SigType" SG_ 2364609382 PLDueToCtrlTemp 4;
BA_ "SPN" SG_ 2364609382 PLDueToCtrlTemp 8578;
BA_ "SigType" SG_ 2364609382 PLDueToLowSideVMax 4;
BA_ "SPN" SG_ 2364609382 PLDueToLowSideVMax 8577;
BA_ "SigType" SG_ 2364609382 PLDueToLowSideVMin 4;
BA_ "SPN" SG_ 2364609382 PLDueToLowSideVMin 8576;
BA_ "SigType" SG_ 2364609382 PLDueToHiSideVMax 4;
BA_ "SPN" SG_ 2364609382 PLDueToHiSideVMax 8575;
BA_ "SigType" SG_ 2364609382 PLDueToHiSideVMin 4;
BA_ "SPN" SG_ 2364609382 PLDueToHiSideVMin 8574;
BA_ "SigType" SG_ 2364609382 PLDueToLowSideCur 4;
BA_ "SPN" SG_ 2364609382 PLDueToLowSideCur 8573;
BA_ "SigType" SG_ 2364609382 PLDueToHiSideCur 4;
BA_ "SPN" SG_ 2364609382 PLDueToHiSideCur 8572;
BA_ "SigType" SG_ 2364609382 LoadshedReq 5;
BA_ "SPN" SG_ 2364609382 LoadshedReq 8571;
BA_ "SigType" SG_ 2364609382 HVILStatus 4;
BA_ "SPN" SG_ 2364609382 HVILStatus 8570;
BA_ "SPN" SG_ 2364609382 OperationalStatus 8569;
BA_ "SigType" SG_ 2365315430 LowSideCurMaxLmt 1;
BA_ "SPN" SG_ 2365315430 LowSideCurMaxLmt 8568;
BA_ "SigType" SG_ 2365315430 LowSideVMaxLmt 1;
BA_ "SPN" SG_ 2365315430 LowSideVMaxLmt 8567;
BA_ "SigType" SG_ 2365315430 LowSideVMinLmt 1;
BA_ "SPN" SG_ 2365315430 LowSideVMinLmt 8566;
BA_ "GenSigStartValue" SG_ 2566857246 Battery_Temperature 40;
BA_ "GenSigStartValue" SG_ 2566856990 NTC_Temperature 40;
BA_ "GenSigStartValue" SG_ 2566856990 BatteryCurrent 32000;
BA_ "SigType" SG_ 2365297509 OneCtrlInputSLIV 1;
BA_ "SPN" SG_ 2365297509 OneCtrlInputSLIV 9559;
BA_ "SigType" SG_ 2365297509 OneCtrlInputIgntV 1;
BA_ "SPN" SG_ 2365297509 OneCtrlInputIgntV 9558;
BA_ "SigType" SG_ 2364610599 TwoLowSideVBuckDefaultSetpoint 1;
BA_ "SPN" SG_ 2364610599 TwoLowSideVBuckDefaultSetpoint 9516;
BA_ "SigType" SG_ 2364610599 TwoHiSideVBoostSetpoint 1;
BA_ "SPN" SG_ 2364610599 TwoHiSideVBoostSetpoint 8894;
BA_ "SigType" SG_ 2364610599 TwoLowSideVBuckSetpoint 1;
BA_ "SPN" SG_ 2364610599 TwoLowSideVBuckSetpoint 8893;
BA_ "SPN" SG_ 2364610599 TwoOperationalCmd 8892;
BA_ "SigType" SG_ 2365315429 LowSideCurMaxLmt 1;
BA_ "SPN" SG_ 2365315429 LowSideCurMaxLmt 8568;
BA_ "SigType" SG_ 2365315429 LowSideVMaxLmt 1;
BA_ "SPN" SG_ 2365315429 LowSideVMaxLmt 8567;
BA_ "SigType" SG_ 2365315429 LowSideVMinLmt 1;
BA_ "SPN" SG_ 2365315429 LowSideVMinLmt 8566;
BA_ "SigType" SG_ 2365315173 OneCoolantOutTemp 1;
BA_ "SPN" SG_ 2365315173 OneCoolantOutTemp 8823;
BA_ "SigType" SG_ 2365315173 OneCoolantInTemp 1;
BA_ "SPN" SG_ 2365315173 OneCoolantInTemp 8822;
BA_ "SigType" SG_ 2365315173 PwrETemp 1;
BA_ "SPN" SG_ 2365315173 PwrETemp 8594;
BA_ "SigType" SG_ 2365315173 ElectronicFilterTemp 1;
BA_ "SPN" SG_ 2365315173 ElectronicFilterTemp 8593;
BA_ "SigType" SG_ 2365315173 Temp 1;
BA_ "SPN" SG_ 2365315173 Temp 8592;
BA_ "SigType" SG_ 2364609637 HiSideCur 1;
BA_ "SPN" SG_ 2364609637 HiSideCur 8588;
BA_ "SigType" SG_ 2364609637 HiSideV 1;
BA_ "SPN" SG_ 2364609637 HiSideV 8587;
BA_ "SigType" SG_ 2364609637 LowSideCur 1;
BA_ "SPN" SG_ 2364609637 LowSideCur 8586;
BA_ "SigType" SG_ 2364609637 LowSideV 1;
BA_ "SPN" SG_ 2364609637 LowSideV 8585;
BA_ "SigType" SG_ 2364609381 PLDueToUndefinedReason 4;
BA_ "SPN" SG_ 2364609381 PLDueToUndefinedReason 8584;
BA_ "SigType" SG_ 2364609381 PLDueToSLIBatTermTemp 4;
BA_ "SPN" SG_ 2364609381 PLDueToSLIBatTermTemp 8582;
BA_ "SigType" SG_ 2364609381 PLDueToSLIBatTermCur 4;
BA_ "SPN" SG_ 2364609381 PLDueToSLIBatTermCur 8583;
BA_ "SigType" SG_ 2364609381 PLDueToSLIBatTermV 4;
BA_ "SPN" SG_ 2364609381 PLDueToSLIBatTermV 8581;
BA_ "SigType" SG_ 2364609381 PLDueToPwrETemp 4;
BA_ "SPN" SG_ 2364609381 PLDueToPwrETemp 8580;
BA_ "SigType" SG_ 2364609381 PLDueToElectronicFilterTemp 4;
BA_ "SPN" SG_ 2364609381 PLDueToElectronicFilterTemp 8579;
BA_ "SigType" SG_ 2364609381 PLDueToCtrlTemp 4;
BA_ "SPN" SG_ 2364609381 PLDueToCtrlTemp 8578;
BA_ "SigType" SG_ 2364609381 PLDueToLowSideVMax 4;
BA_ "SPN" SG_ 2364609381 PLDueToLowSideVMax 8577;
BA_ "SigType" SG_ 2364609381 PLDueToLowSideVMin 4;
BA_ "SPN" SG_ 2364609381 PLDueToLowSideVMin 8576;
BA_ "SigType" SG_ 2364609381 PLDueToHiSideVMax 4;
BA_ "SPN" SG_ 2364609381 PLDueToHiSideVMax 8575;
BA_ "SigType" SG_ 2364609381 PLDueToHiSideVMin 4;
BA_ "SPN" SG_ 2364609381 PLDueToHiSideVMin 8574;
BA_ "SigType" SG_ 2364609381 PLDueToLowSideCur 4;
BA_ "SPN" SG_ 2364609381 PLDueToLowSideCur 8573;
BA_ "SigType" SG_ 2364609381 PLDueToHiSideCur 4;
BA_ "SPN" SG_ 2364609381 PLDueToHiSideCur 8572;
BA_ "SigType" SG_ 2364609381 LoadshedReq 5;
BA_ "SPN" SG_ 2364609381 LoadshedReq 8571;
BA_ "SigType" SG_ 2364609381 HVILStatus 4;
BA_ "SPN" SG_ 2364609381 HVILStatus 8570;
BA_ "SPN" SG_ 2364609381 OperationalStatus 8569;
BA_ "SigType" SG_ 2364609063 OneLowSideVBuckDefaultSetpoint 1;
BA_ "SPN" SG_ 2364609063 OneLowSideVBuckDefaultSetpoint 9515;
BA_ "SigType" SG_ 2364609063 HiSideVBoostSetpoint 1;
BA_ "SPN" SG_ 2364609063 HiSideVBoostSetpoint 8562;
BA_ "SigType" SG_ 2364609063 LowSideVBuckSetpoint 1;
BA_ "SPN" SG_ 2364609063 LowSideVBuckSetpoint 8561;
BA_ "SPN" SG_ 2364609063 OperationalCmd 8560;
BA_ "GenSigStartValue" SG_ 2566870400 VCVCCU_V2G_EVSEMaximumVoltageLim 3;
BA_ "GenSigStartValue" SG_ 2566870144 VCVCCU_V2G_EVSEMaximumPowerLimit 3;
BA_ "GenSigStartValue" SG_ 2566869888 VCVCCU_V2G_EVSEMaximumCurrentLim 3;
BA_ "GenSigStartValue" SG_ 2566869632 VCVCCU_V2G_EVSEEnergyToBeDeliver 3;
BA_ "GenSigStartValue" SG_ 2566869376 VCVCCU_V2G_EVSECurrentRegulation 3;
BA_ "GenSigStartValue" SG_ 2566862978 VCVCCU_V2G_EVMaximumPowerLimit_M 3;
BA_ "GenSigStartValue" SG_ 2566862722 VCVCCU_V2G_EVMaximumCurrentLimit 3;
BA_ "GenSigStartValue" SG_ 2566862466 VCVCCU_V2G_EVEnergyRequestFlag 3;
BA_ "GenSigStartValue" SG_ 2566862210 VCVCCU_V2G_EVEnergyCapacityFlag 3;
BA_ "GenSigStartValue" SG_ 2566869120 VCVCCU_V2G_DateTimeNowFlag 3;
BA_ "GenSigStartValue" SG_ 2566869120 VCVCCU_V2G_EVSEPowerLimitAchieve 3;
BA_ "GenSigStartValue" SG_ 2566869120 VCVCCU_V2G_EVSEVoltageLimitAchie 3;
BA_ "GenSigStartValue" SG_ 2566869120 VCVCCU_V2G_EVSEIsolationStatusFl 3;
BA_ "GenSigStartValue" SG_ 2566869120 VCVCCU_V2G_EVSECurrentLimitAchie 3;
BA_ "GenSigStartValue" SG_ 2566861442 VCVCCU_V2G_RemainingTimeToBulkSO 3;
BA_ "GenSigStartValue" SG_ 2566861186 VCVCCU_V2G_RemainingTimeToFullSO 3;
BA_ "GenSigStartValue" SG_ 2566860930 VCVCCU_V2G_StateM_EnergyTra_0000 15;
BA_ "GenSigStartValue" SG_ 2566860930 VCVCCU_V2G_EVPowerDeliveryParame 3;
BA_ "GenSigStartValue" SG_ 2566860930 VCVCCU_V2G_EVRESSConditioningFla 3;
BA_ "GenSigStartValue" SG_ 2566860930 VCVCCU_V2G_EVRESSConditioning 3;
BA_ "GenSigStartValue" SG_ 2566860930 VCVCCU_V2G_EVReady 3;
BA_ "GenSigStartValue" SG_ 2566860930 VCVCCU_V2G_EVCabinConditioningFl 3;
BA_ "GenSigStartValue" SG_ 2566860930 VCVCCU_V2G_EVCabinConditioning 3;
BA_ "GenSigStartValue" SG_ 2566860930 VCVCCU_V2G_ChargingComplete 3;
BA_ "GenSigStartValue" SG_ 2566860930 VCVCCU_V2G_FullSOCFlag 3;
BA_ "GenSigStartValue" SG_ 2566860930 VCVCCU_V2G_BulkSOCFlag 3;
BA_ "GenSigStartValue" SG_ 2566860930 VCVCCU_V2G_BulkChargingCompleteF 3;
BA_ "GenSigStartValue" SG_ 2566860930 VCVCCU_V2G_BulkChargingComplete 3;
BA_ "GenSigStartValue" SG_ 2566857090 VCVCCU_Vehicle_ChargeSelection 3;
BA_ "GenSigStartValue" SG_ 2566857090 VCVCCU_Vehicle_StopCharge 3;
BA_ "GenSigStartValue" SG_ 2566857090 VCVCCU_Vehicle_IsolationMeasurem 3;
BA_ "GenSigStartValue" SG_ 2566857090 VCVCCU_Vehicle_PlugUnlockPermiss 3;
BA_ "GenSigStartValue" SG_ 2566857090 VCVCCU_Vehicle_ChargePermission 3;
BA_ "GenSigStartValue" SG_ 2566854528 VCVCCU_Vehicle_ChargeSelectiAck 3;
BA_ "GenSigStartValue" SG_ 2566856834 VCVCCU_Inlet_MotorRequest 3;
BA_ "GenSigStartValue" SG_ 2566856834 VCVCCU_ChargeUnit_Request 3;
BA_ "GenSigStartValue" SG_ 2566856834 VCVCCU_RTC_TimerValue 255;
BA_ "GenSigStartValue" SG_ 2566856834 VCVCCU_RTC_TimerRequest 3;
BA_ "GenSigStartValue" SG_ 2566856834 VCVCCU_PlugLock_MotorRequest 7;
BA_ "GenSigStartValue" SG_ 2566856834 VCVCCU_LED2_Request 255;
BA_ "GenSigStartValue" SG_ 2566856834 VCVCCU_LED1_Request 255;
BA_ "GenSigStartValue" SG_ 2566856834 VCVCCU_LED0_Request 255;
BA_ "GenSigStartValue" SG_ 2566856834 VCVCCU_HighSideOut4_Request 3;
BA_ "GenSigStartValue" SG_ 2566856834 VCVCCU_HighSideOut3_Request 3;
BA_ "GenSigStartValue" SG_ 2566856834 VCVCCU_HighSideOut2_Request 3;
BA_ "GenSigStartValue" SG_ 2566856834 VCVCCU_HighSideOut1_Request 3;
BA_ "GenSigStartValue" SG_ 2566856834 VCVCCU_HighSideOut0_Request 3;
BA_ "GenSigStartValue" SG_ 2566856834 VCVCCU_ControlPilot_ChargeModeRe 7;
BA_ "GenSigStartValue" SG_ 2566854272 VCVCCU_RTC_Wakeup 3;
BA_ "GenSigStartValue" SG_ 2566854272 VCVCCU_RTC_TimerStatus 3;
BA_ "GenSigStartValue" SG_ 2566854016 VCVCCU_HighSideOut3_Input_Wakeup 3;
BA_ "GenSigStartValue" SG_ 2566854016 VCVCCU_HighSideOut4_Input_Status 3;
BA_ "GenSigStartValue" SG_ 2566854016 VCVCCU_HighSideOut4_Input_Deboun 3;
BA_ "GenSigStartValue" SG_ 2566854016 VCVCCU_HighSideOut3_Input_Status 3;
BA_ "GenSigStartValue" SG_ 2566854016 VCVCCU_HighSideOut3_Input_Deboun 3;
BA_ "GenSigStartValue" SG_ 2566854016 VCVCCU_HighSideOut2_Input_Status 3;
BA_ "GenSigStartValue" SG_ 2566854016 VCVCCU_HighSideOut2_Input_Deboun 3;
BA_ "GenSigStartValue" SG_ 2566854016 VCVCCU_HighSideOut1_Input_Status 3;
BA_ "GenSigStartValue" SG_ 2566854016 VCVCCU_HighSideOut1_Input_Deboun 3;
BA_ "GenSigStartValue" SG_ 2566854016 VCVCCU_HighSideOut0_Input_Status 3;
BA_ "GenSigStartValue" SG_ 2566854016 VCVCCU_HighSideOut0_Input_Deboun 3;
BA_ "GenSigStartValue" SG_ 2566854016 VCVCCU_LED2_SelfDiagnosticStatus 7;
BA_ "GenSigStartValue" SG_ 2566854016 VCVCCU_LED1_SelfDiagnosticStatus 7;
BA_ "GenSigStartValue" SG_ 2566854016 VCVCCU_LED0_SelfDiagnosticStatus 7;
BA_ "GenSigStartValue" SG_ 2566854016 VCVCCU_HighSideOut4_SelfDiagnost 7;
BA_ "GenSigStartValue" SG_ 2566854016 VCVCCU_HighSideOut3_SelfDiagnost 7;
BA_ "GenSigStartValue" SG_ 2566854016 VCVCCU_HighSideOut2_SelfDiagnost 7;
BA_ "GenSigStartValue" SG_ 2566854016 VCVCCU_HighSideOut1_SelfDiagnost 7;
BA_ "GenSigStartValue" SG_ 2566854016 VCVCCU_HighSideOut0_SelfDiagnost 7;
BA_ "GenSigStartValue" SG_ 2566853760 VCVCCU_ChargeUnit_State 7;
BA_ "GenSigStartValue" SG_ 2566853760 VCVCCU_ChargeUnit_Mode 7;
BA_ "GenSigStartValue" SG_ 2566853760 VCVCCU_ChargeUnit_MaxCurrent 255;
BA_ "GenSigStartValue" SG_ 2566853760 VCVCCU_ControlPilot_Wakeup 3;
BA_ "GenSigStartValue" SG_ 2566853760 VCVCCU_ControlPilot_DutyCycle 255;
BA_ "GenSigStartValue" SG_ 2566853504 VCVCCU_Inlet_HWVariant 3;
BA_ "GenSigStartValue" SG_ 2566853504 VCVCCU_S3Switch_Status 3;
BA_ "GenSigStartValue" SG_ 2566853504 VCVCCU_S3Switch_DebouncedStatus 3;
BA_ "GenSigStartValue" SG_ 2566853504 VCVCCU_DigitalInput_DebouncedSta 3;
BA_ "GenSigStartValue" SG_ 2566853504 VCVCCU_Inlet_MaxCurrent 255;
BA_ "GenSigStartValue" SG_ 2566853504 VCVCCU_Inlet_MotorStatus 7;
BA_ "GenSigStartValue" SG_ 2566853504 VCVCCU_Inlet_ConnectionStatus 3;
BA_ "GenSigStartValue" SG_ 2566853504 VCVCCU_PlugPresent_Wakeup 3;
BA_ "GenSigStartValue" SG_ 2566853504 VCVCCU_PlugPresent_Status 3;
BA_ "GenSigStartValue" SG_ 2566853504 VCVCCU_POSFeedback_SelfDiagnosti 7;
BA_ "GenSigStartValue" SG_ 2566853504 VCVCCU_PlugPresent_SelfDiagnosti 7;
BA_ "GenSigStartValue" SG_ 2566853504 VCVCCU_DigitalInput_Wakeup 3;
BA_ "GenSigStartValue" SG_ 2566853504 VCVCCU_PlugPresent_Resistance 7;
BA_ "GenSigStartValue" SG_ 2566853504 VCVCCU_PlugLock_Output1_SelfDiag 7;
BA_ "GenSigStartValue" SG_ 2566853504 VCVCCU_DigitalInput_Status 3;
BA_ "GenSigStartValue" SG_ 2566853504 VCVCCU_PlugLock_Output0_SelfDiag 7;
BA_ "GenSigStartValue" SG_ 2566853504 VCVCCU_PlugLock_MotorStatus 7;
BA_ "GenSigStartValue" SG_ 2566853248 VCVCCU_PTC2_SelfDiagnosticStatus 7;
BA_ "GenSigStartValue" SG_ 2566852992 VCVCCU_PTC1_SelfDiagnosticStatus 7;
BA_ "GenSigStartValue" SG_ 2633990272 WakeupRsn_VCVCCU 255;
BA_ "GenSigStartValue" SG_ 2566834816 DTC_FailModeID_VCCU 31;
BA_ "GenSigStartValue" SG_ 2566834816 DTC_SPN_ConvMd_VCCU 1;
BA_ "GenSigStartValue" SG_ 2566834816 DTC_RSL_Flash_Stat_VCCU 3;
BA_ "GenSigStartValue" SG_ 2566834816 DTC_PL_Flash_Stat_VCCU 3;
BA_ "GenSigStartValue" SG_ 2566834816 DTC_RSL_Stat_VCCU 3;
BA_ "GenSigStartValue" SG_ 2566834816 DTC_PL_Stat_VCCU 3;
BA_ "GenSigStartValue" SG_ 2566834816 DTC_MIL_Stat_VCCU 3;
BA_ "GenSigStartValue" SG_ 2566834816 DTC_MIL_Flash_Stat_VCCU 3;
BA_ "GenSigStartValue" SG_ 2566834816 DTC_AWL_Flash_Stat_VCCU 3;
BA_ "GenSigStartValue" SG_ 2566834816 DTC_AWL_Stat_VCCU 3;
BA_ "GenSigStartValue" SG_ 2566852736 VCVCCU_PTC0_SelfDiagnosticStatus 7;
VAL_ 2566913829 Signal_BSC_Power_Distributi_0004 2 "Distributed" 1 "Distribution_in_progress" 0 "Not_distributed" ;
VAL_ 2566913829 Signal_BSC_Operating_Status_15 2 "Failure" 1 "Downgraded" 0 "Normal" ;
VAL_ 2566913829 Signal_BSC_Transition_Status_15 2 "Transition_in_progress" 1 "Transition_failed" 0 "Transition_Ok" ;
VAL_ 2566913829 Signal_BSC_Requested_State_15 3 "Charge" 2 "Operational" 1 "Standby" 0 "Off" ;
VAL_ 2566913829 Signal_BSC_Actual_Transition_15 5 "No_transition" 4 "Disconnection" 3 "Connection_to_charge" 2 "Connection_to_operational" 1 "Shutdown_BMS" 0 "Wakeup_BMS" ;
VAL_ 2566913829 Signal_BSC_Actual_State_15 3 "Charge" 2 "Operational" 1 "Standby" 0 "Off" ;
VAL_ 2566913573 Signal_BSC_Power_Distributi_0005 2 "Distributed" 1 "Distribution_in_progress" 0 "Not_distributed" ;
VAL_ 2566913573 Signal_BSC_Operating_Status_14 2 "Failure" 1 "Downgraded" 0 "Normal" ;
VAL_ 2566913573 Signal_BSC_Transition_Status_14 2 "Transition_in_progress" 1 "Transition_failed" 0 "Transition_Ok" ;
VAL_ 2566913573 Signal_BSC_Requested_State_14 3 "Charge" 2 "Operational" 1 "Standby" 0 "Off" ;
VAL_ 2566913573 Signal_BSC_Actual_Transition_14 5 "No_transition" 4 "Disconnection" 3 "Connection_to_charge" 2 "Connection_to_operational" 1 "Shutdown_BMS" 0 "Wakeup_BMS" ;
VAL_ 2566913573 Signal_BSC_Actual_State_14 3 "Charge" 2 "Operational" 1 "Standby" 0 "Off" ;
VAL_ 2566913317 Signal_BSC_Power_Distributi_0006 2 "Distributed" 1 "Distribution_in_progress" 0 "Not_distributed" ;
VAL_ 2566913317 Signal_BSC_Operating_Status_13 2 "Failure" 1 "Downgraded" 0 "Normal" ;
VAL_ 2566913317 Signal_BSC_Transition_Status_13 2 "Transition_in_progress" 1 "Transition_failed" 0 "Transition_Ok" ;
VAL_ 2566913317 Signal_BSC_Requested_State_13 3 "Charge" 2 "Operational" 1 "Standby" 0 "Off" ;
VAL_ 2566913317 Signal_BSC_Actual_Transition_13 5 "No_transition" 4 "Disconnection" 3 "Connection_to_charge" 2 "Connection_to_operational" 1 "Shutdown_BMS" 0 "Wakeup_BMS" ;
VAL_ 2566913317 Signal_BSC_Actual_State_13 3 "Charge" 2 "Operational" 1 "Standby" 0 "Off" ;
VAL_ 2566913061 Signal_BSC_Power_Distributi_0007 2 "Distributed" 1 "Distribution_in_progress" 0 "Not_distributed" ;
VAL_ 2566913061 Signal_BSC_Operating_Status_12 2 "Failure" 1 "Downgraded" 0 "Normal" ;
VAL_ 2566913061 Signal_BSC_Transition_Status_12 2 "Transition_in_progress" 1 "Transition_failed" 0 "Transition_Ok" ;
VAL_ 2566913061 Signal_BSC_Requested_State_12 3 "Charge" 2 "Operational" 1 "Standby" 0 "Off" ;
VAL_ 2566913061 Signal_BSC_Actual_Transition_12 5 "No_transition" 4 "Disconnection" 3 "Connection_to_charge" 2 "Connection_to_operational" 1 "Shutdown_BMS" 0 "Wakeup_BMS" ;
VAL_ 2566913061 Signal_BSC_Actual_State_12 3 "Charge" 2 "Operational" 1 "Standby" 0 "Off" ;
VAL_ 2566912805 Signal_BSC_Power_Distributi_0008 2 "Distributed" 1 "Distribution_in_progress" 0 "Not_distributed" ;
VAL_ 2566912805 Signal_BSC_Operating_Status_11 2 "Failure" 1 "Downgraded" 0 "Normal" ;
VAL_ 2566912805 Signal_BSC_Transition_Status_11 2 "Transition_in_progress" 1 "Transition_failed" 0 "Transition_Ok" ;
VAL_ 2566912805 Signal_BSC_Requested_State_11 3 "Charge" 2 "Operational" 1 "Standby" 0 "Off" ;
VAL_ 2566912805 Signal_BSC_Actual_Transition_11 5 "No_transition" 4 "Disconnection" 3 "Connection_to_charge" 2 "Connection_to_operational" 1 "Shutdown_BMS" 0 "Wakeup_BMS" ;
VAL_ 2566912805 Signal_BSC_Actual_State_11 3 "Charge" 2 "Operational" 1 "Standby" 0 "Off" ;
VAL_ 2566912549 Signal_BSC_Power_Distributi_0009 2 "Distributed" 1 "Distribution_in_progress" 0 "Not_distributed" ;
VAL_ 2566912549 Signal_BSC_Operating_Status_10 2 "Failure" 1 "Downgraded" 0 "Normal" ;
VAL_ 2566912549 Signal_BSC_Transition_Status_10 2 "Transition_in_progress" 1 "Transition_failed" 0 "Transition_Ok" ;
VAL_ 2566912549 Signal_BSC_Requested_State_10 3 "Charge" 2 "Operational" 1 "Standby" 0 "Off" ;
VAL_ 2566912549 Signal_BSC_Actual_Transition_10 5 "No_transition" 4 "Disconnection" 3 "Connection_to_charge" 2 "Connection_to_operational" 1 "Shutdown_BMS" 0 "Wakeup_BMS" ;
VAL_ 2566912549 Signal_BSC_Actual_State_10 3 "Charge" 2 "Operational" 1 "Standby" 0 "Off" ;
VAL_ 2566912293 Signal_BSC_Power_Distributi_0010 2 "Distributed" 1 "Distribution_in_progress" 0 "Not_distributed" ;
VAL_ 2566912293 Signal_BSC_Operating_Status_09 2 "Failure" 1 "Downgraded" 0 "Normal" ;
VAL_ 2566912293 Signal_BSC_Transition_Status_09 2 "Transition_in_progress" 1 "Transition_failed" 0 "Transition_Ok" ;
VAL_ 2566912293 Signal_BSC_Requested_State_09 3 "Charge" 2 "Operational" 1 "Standby" 0 "Off" ;
VAL_ 2566912293 Signal_BSC_Actual_Transition_09 5 "No_transition" 4 "Disconnection" 3 "Connection_to_charge" 2 "Connection_to_operational" 1 "Shutdown_BMS" 0 "Wakeup_BMS" ;
VAL_ 2566912293 Signal_BSC_Actual_State_09 3 "Charge" 2 "Operational" 1 "Standby" 0 "Off" ;
VAL_ 2566912037 Signal_BSC_Power_Distributi_0011 2 "Distributed" 1 "Distribution_in_progress" 0 "Not_distributed" ;
VAL_ 2566912037 Signal_BSC_Operating_Status_08 2 "Failure" 1 "Downgraded" 0 "Normal" ;
VAL_ 2566912037 Signal_BSC_Transition_Status_08 2 "Transition_in_progress" 1 "Transition_failed" 0 "Transition_Ok" ;
VAL_ 2566912037 Signal_BSC_Requested_State_08 3 "Charge" 2 "Operational" 1 "Standby" 0 "Off" ;
VAL_ 2566912037 Signal_BSC_Actual_Transition_08 5 "No_transition" 4 "Disconnection" 3 "Connection_to_charge" 2 "Connection_to_operational" 1 "Shutdown_BMS" 0 "Wakeup_BMS" ;
VAL_ 2566912037 Signal_BSC_Actual_State_08 3 "Charge" 2 "Operational" 1 "Standby" 0 "Off" ;
VAL_ 2566911781 Signal_BSC_Power_Distributi_0012 2 "Distributed" 1 "Distribution_in_progress" 0 "Not_distributed" ;
VAL_ 2566911781 Signal_BSC_Operating_Status_07 2 "Failure" 1 "Downgraded" 0 "Normal" ;
VAL_ 2566911781 Signal_BSC_Transition_Status_07 2 "Transition_in_progress" 1 "Transition_failed" 0 "Transition_Ok" ;
VAL_ 2566911781 Signal_BSC_Requested_State_07 3 "Charge" 2 "Operational" 1 "Standby" 0 "Off" ;
VAL_ 2566911781 Signal_BSC_Actual_Transition_07 5 "No_transition" 4 "Disconnection" 3 "Connection_to_charge" 2 "Connection_to_operational" 1 "Shutdown_BMS" 0 "Wakeup_BMS" ;
VAL_ 2566911781 Signal_BSC_Actual_State_07 3 "Charge" 2 "Operational" 1 "Standby" 0 "Off" ;
VAL_ 2566911525 Signal_BSC_Power_Distributi_0013 2 "Distributed" 1 "Distribution_in_progress" 0 "Not_distributed" ;
VAL_ 2566911525 Signal_BSC_Operating_Status_06 2 "Failure" 1 "Downgraded" 0 "Normal" ;
VAL_ 2566911525 Signal_BSC_Transition_Status_06 2 "Transition_in_progress" 1 "Transition_failed" 0 "Transition_Ok" ;
VAL_ 2566911525 Signal_BSC_Requested_State_06 3 "Charge" 2 "Operational" 1 "Standby" 0 "Off" ;
VAL_ 2566911525 Signal_BSC_Actual_Transition_06 5 "No_transition" 4 "Disconnection" 3 "Connection_to_charge" 2 "Connection_to_operational" 1 "Shutdown_BMS" 0 "Wakeup_BMS" ;
VAL_ 2566911525 Signal_BSC_Actual_State_06 3 "Charge" 2 "Operational" 1 "Standby" 0 "Off" ;
VAL_ 2566911269 Signal_BSC_Power_Distributi_0014 2 "Distributed" 1 "Distribution_in_progress" 0 "Not_distributed" ;
VAL_ 2566911269 Signal_BSC_Operating_Status_05 2 "Failure" 1 "Downgraded" 0 "Normal" ;
VAL_ 2566911269 Signal_BSC_Transition_Status_05 2 "Transition_in_progress" 1 "Transition_failed" 0 "Transition_Ok" ;
VAL_ 2566911269 Signal_BSC_Requested_State_05 3 "Charge" 2 "Operational" 1 "Standby" 0 "Off" ;
VAL_ 2566911269 Signal_BSC_Actual_Transition_05 5 "No_transition" 4 "Disconnection" 3 "Connection_to_charge" 2 "Connection_to_operational" 1 "Shutdown_BMS" 0 "Wakeup_BMS" ;
VAL_ 2566911269 Signal_BSC_Actual_State_05 3 "Charge" 2 "Operational" 1 "Standby" 0 "Off" ;
VAL_ 2566911013 Signal_BSC_Power_Distributi_0015 2 "Distributed" 1 "Distribution_in_progress" 0 "Not_distributed" ;
VAL_ 2566911013 Signal_BSC_Operating_Status_04 2 "Failure" 1 "Downgraded" 0 "Normal" ;
VAL_ 2566911013 Signal_BSC_Transition_Status_04 2 "Transition_in_progress" 1 "Transition_failed" 0 "Transition_Ok" ;
VAL_ 2566911013 Signal_BSC_Requested_State_04 3 "Charge" 2 "Operational" 1 "Standby" 0 "Off" ;
VAL_ 2566911013 Signal_BSC_Actual_Transition_04 5 "No_transition" 4 "Disconnection" 3 "Connection_to_charge" 2 "Connection_to_operational" 1 "Shutdown_BMS" 0 "Wakeup_BMS" ;
VAL_ 2566911013 Signal_BSC_Actual_State_04 3 "Charge" 2 "Operational" 1 "Standby" 0 "Off" ;
VAL_ 2566910757 Signal_BSC_Power_Distributi_0016 2 "Distributed" 1 "Distribution_in_progress" 0 "Not_distributed" ;
VAL_ 2566910757 Signal_BSC_Operating_Status_03 2 "Failure" 1 "Downgraded" 0 "Normal" ;
VAL_ 2566910757 Signal_BSC_Transition_Status_03 2 "Transition_in_progress" 1 "Transition_failed" 0 "Transition_Ok" ;
VAL_ 2566910757 Signal_BSC_Requested_State_03 3 "Charge" 2 "Operational" 1 "Standby" 0 "Off" ;
VAL_ 2566910757 Signal_BSC_Actual_Transition_03 5 "No_transition" 4 "Disconnection" 3 "Connection_to_charge" 2 "Connection_to_operational" 1 "Shutdown_BMS" 0 "Wakeup_BMS" ;
VAL_ 2566910757 Signal_BSC_Actual_State_03 3 "Charge" 2 "Operational" 1 "Standby" 0 "Off" ;
VAL_ 2566910501 Signal_BSC_Power_Distributi_0017 2 "Distributed" 1 "Distribution_in_progress" 0 "Not_distributed" ;
VAL_ 2566910501 Signal_BSC_Operating_Status_02 2 "Failure" 1 "Downgraded" 0 "Normal" ;
VAL_ 2566910501 Signal_BSC_Transition_Status_02 2 "Transition_in_progress" 1 "Transition_failed" 0 "Transition_Ok" ;
VAL_ 2566910501 Signal_BSC_Requested_State_02 3 "Charge" 2 "Operational" 1 "Standby" 0 "Off" ;
VAL_ 2566910501 Signal_BSC_Actual_Transition_02 5 "No_transition" 4 "Disconnection" 3 "Connection_to_charge" 2 "Connection_to_operational" 1 "Shutdown_BMS" 0 "Wakeup_BMS" ;
VAL_ 2566910501 Signal_BSC_Actual_State_02 3 "Charge" 2 "Operational" 1 "Standby" 0 "Off" ;
VAL_ 2566910245 Signal_BSC_Power_Distributi_0018 2 "Distributed" 1 "Distribution_in_progress" 0 "Not_distributed" ;
VAL_ 2566910245 Signal_BSC_Operating_Status_01 2 "Failure" 1 "Downgraded" 0 "Normal" ;
VAL_ 2566910245 Signal_BSC_Transition_Status_01 2 "Transition_in_progress" 1 "Transition_failed" 0 "Transition_Ok" ;
VAL_ 2566910245 Signal_BSC_Requested_State_01 3 "Charge" 2 "Operational" 1 "Standby" 0 "Off" ;
VAL_ 2566910245 Signal_BSC_Actual_Transition_01 5 "No_transition" 4 "Disconnection" 3 "Connection_to_charge" 2 "Connection_to_operational" 1 "Shutdown_BMS" 0 "Wakeup_BMS" ;
VAL_ 2566910245 Signal_BSC_Actual_State_01 3 "Charge" 2 "Operational" 1 "Standby" 0 "Off" ;
VAL_ 2566861093 PrechargeContactorState 3 "Unavailable" 2 "Error" 1 "Closed" 0 "Opened" ;
VAL_ 2566861093 MainContactorState 3 "Unavailable" 2 "Error" 1 "Closed" 0 "Opened" ;
VAL_ 2566861093 ISOFailureState 3 "Not_available" 2 "Error" 1 "Failure_detected" 0 "No_failure_detected" ;
VAL_ 2566861093 ChargeCompletedStatus 3 "Not_available" 2 "Error" 1 "Completed" 0 "Not completed" ;
VAL_ 2566861093 BatterySystemOperatingMode 15 "Not_available" 14 "Error" 13 "Unused" 12 "Unused" 11 "Unused" 10 "Unused" 9 "Unused" 8 "Unused" 7 "Unused" 6 "Transition_in_progress" 5 "Unused" 4 "Charge" 3 "Unused" 2 "Operational" 1 "Standby" 0 "Off" ;
VAL_ 2566861093 BatterySystemAvailabilityMode 15 "Not_available" 14 "Error" 13 "Unused" 12 "Unused" 11 "Unused" 10 "Unused" 9 "Unused" 8 "Unused" 7 "Unused" 6 "Unused" 5 "Unused" 4 "Stop critical" 3 "Stop" 2 "Check" 1 "Maintenance" 0 "Good" ;
VAL_ 2566856487 PrechargeContactor 3 "Unavailable" 2 "Error" 1 "Requested" 0 "Not requested" ;
VAL_ 2566856487 MainContactor 3 "Unavailable" 2 "Error" 1 "Closed" 0 "Opened" ;
VAL_ 2364609382 PLDueToUndefinedReason 3 "Not Available" 2 "Error" 1 "Power limited for this reason" 0 "No power limit for this reason" ;
VAL_ 2364609382 PLDueToSLIBatTermTemp 3 "Not Available" 2 "Error" 1 "Power limited for this reason" 0 "No power limit for this reason" ;
VAL_ 2364609382 PLDueToSLIBatTermCur 3 "Not Available" 2 "Error" 1 "Power limited for this reason" 0 "No power limit for this reason" ;
VAL_ 2364609382 PLDueToSLIBatTermV 3 "Not Available" 2 "Error" 1 "Power limited for this reason" 0 "No power limit for this reason" ;
VAL_ 2364609382 PLDueToPwrETemp 3 "Not Available" 2 "Error" 1 "Power limited for this reason" 0 "No power limit for this reason" ;
VAL_ 2364609382 PLDueToElectronicFilterTemp 3 "Not available" 2 "Error" 1 "Power limited for this reason" 0 "No power limit for this reason" ;
VAL_ 2364609382 PLDueToCtrlTemp 3 "Not Available" 2 "Error" 1 "Power limited for this reason" 0 "No power limit for this reason" ;
VAL_ 2364609382 PLDueToLowSideVMax 3 "Not Available" 2 "Error" 1 "Power limited for this reason" 0 "No power limit for this reason" ;
VAL_ 2364609382 PLDueToLowSideVMin 3 "Not Available" 2 "Error" 1 "Power limited for this reason" 0 "No power limit for this reason" ;
VAL_ 2364609382 PLDueToHiSideVMax 3 "Not Available" 2 "Error" 1 "Power limited for this reason" 0 "No power limit for this reason" ;
VAL_ 2364609382 PLDueToHiSideVMin 3 "Not Available" 2 "Error" 1 "Power limited for this reason" 0 "No power limit for this reason" ;
VAL_ 2364609382 PLDueToLowSideCur 3 "Not Available" 2 "Error" 1 "Power limited for this reason" 0 "No power limit for this reason" ;
VAL_ 2364609382 PLDueToHiSideCur 3 "Not Available" 2 "Error" 1 "Power limited for this reason" 0 "No power limit for this reason" ;
VAL_ 2364609382 LoadshedReq 3 "Don't Care/Take No Action" 2 "Loadshed Requested,  Shutdown Imminent" 1 "Loadshed Requested" 0 "No Loadshed Requested" ;
VAL_ 2364609382 HVILStatus 3 "Not Available" 2 "Error" 1 "HVIL Open" 0 "HVIL Closed" ;
VAL_ 2364609382 OperationalStatus 15 "Not Available" 14 "Error" 13 "Manufacturer assignable state" 12 "Reserved" 11 "Reserved" 10 "Reserved" 9 "Reserved" 8 "Reserved" 7 "Reserved" 6 "Disabled due to malfunction or protection" 5 "Normal power down in process" 4 "Operational, Boost mode" 3 "Operational, Buck mode" 2 "Operational, Standby" 1 "Initialization in process" 0 "Disabled" ;
VAL_ 2566851367 PrechargeContactorState 3 "Unavailable" 2 "Error" 1 "Closed" 0 "Opened" ;
VAL_ 2566851367 ISOFailureState 3 "Not_available" 2 "Error" 1 "Failure_detected" 0 "No_failure_detected" ;
VAL_ 2566851367 ChargeCompletedStatus 3 "Not_available" 2 "Error" 1 "Completed" 0 "Not completed" ;
VAL_ 2566851367 BatterySystemOperatingMode 15 "Not_available" 14 "Error" 13 "Unused" 12 "Unused" 11 "Unused" 10 "Unused" 9 "Unused" 8 "Unused" 7 "Unused" 6 "Transition_in_progress" 5 "Unused" 4 "Charge" 3 "Unused" 2 "Operational" 1 "Standby" 0 "Off" ;
VAL_ 2566851367 BatterySystemAvailabilityMode 15 "Not_available" 14 "Error" 13 "Unused" 12 "Unused" 11 "Unused" 10 "Unused" 9 "Unused" 8 "Unused" 7 "Unused" 6 "Unused" 5 "Unused" 4 "Stop critical" 3 "Stop" 2 "Check" 1 "Maintenance" 0 "Good" ;
VAL_ 2364610599 TwoOperationalCmd 11 "Reserved" 10 "Reserved" 9 "Reserved" 8 "Reserved" 7 "Reserved" 6 "Reserved" 5 "Reserved" 4 "Power down DC/DC Converter" 3 "Operate in boost mode" 2 "Operate in buck mode" 15 "Don't care/ Take No Action" 13 "Reserved" 12 "Reserved" 1 "Operate in standby mode" 0 "Disable" ;
VAL_ 2364609381 PLDueToUndefinedReason 3 "Not Available" 2 "Error" 1 "Power limited for this reason" 0 "No power limit for this reason" ;
VAL_ 2364609381 PLDueToSLIBatTermTemp 3 "Not Available" 2 "Error" 1 "Power limited for this reason" 0 "No power limit for this reason" ;
VAL_ 2364609381 PLDueToSLIBatTermCur 3 "Not Available" 2 "Error" 1 "Power limited for this reason" 0 "No power limit for this reason" ;
VAL_ 2364609381 PLDueToSLIBatTermV 3 "Not Available" 2 "Error" 1 "Power limited for this reason" 0 "No power limit for this reason" ;
VAL_ 2364609381 PLDueToPwrETemp 3 "Not Available" 2 "Error" 1 "Power limited for this reason" 0 "No power limit for this reason" ;
VAL_ 2364609381 PLDueToElectronicFilterTemp 3 "Not available" 2 "Error" 1 "Power limited for this reason" 0 "No power limit for this reason" ;
VAL_ 2364609381 PLDueToCtrlTemp 3 "Not Available" 2 "Error" 1 "Power limited for this reason" 0 "No power limit for this reason" ;
VAL_ 2364609381 PLDueToLowSideVMax 3 "Not Available" 2 "Error" 1 "Power limited for this reason" 0 "No power limit for this reason" ;
VAL_ 2364609381 PLDueToLowSideVMin 3 "Not Available" 2 "Error" 1 "Power limited for this reason" 0 "No power limit for this reason" ;
VAL_ 2364609381 PLDueToHiSideVMax 3 "Not Available" 2 "Error" 1 "Power limited for this reason" 0 "No power limit for this reason" ;
VAL_ 2364609381 PLDueToHiSideVMin 3 "Not Available" 2 "Error" 1 "Power limited for this reason" 0 "No power limit for this reason" ;
VAL_ 2364609381 PLDueToLowSideCur 3 "Not Available" 2 "Error" 1 "Power limited for this reason" 0 "No power limit for this reason" ;
VAL_ 2364609381 PLDueToHiSideCur 3 "Not Available" 2 "Error" 1 "Power limited for this reason" 0 "No power limit for this reason" ;
VAL_ 2364609381 LoadshedReq 3 "Don't Care/Take No Action" 2 "Loadshed Requested,  Shutdown Imminent" 1 "Loadshed Requested" 0 "No Loadshed Requested" ;
VAL_ 2364609381 HVILStatus 3 "Not Available" 2 "Error" 1 "HVIL Open" 0 "HVIL Closed" ;
VAL_ 2364609381 OperationalStatus 15 "Not Available" 14 "Error" 13 "Manufacturer assignable state" 12 "Reserved" 11 "Reserved" 10 "Reserved" 9 "Reserved" 8 "Reserved" 7 "Reserved" 6 "Disabled due to malfunction or protection" 5 "Normal power down in process" 4 "Operational, Boost mode" 3 "Operational, Buck mode" 2 "Operational, Standby" 1 "Initialization in process" 0 "Disabled" ;
VAL_ 2364609063 OperationalCmd 15 "Don't care/ Take No Action" 13 "Reserved" 12 "Reserved" 11 "Reserved" 10 "Reserved" 9 "Reserved" 8 "Reserved" 7 "Reserved" 6 "Reserved" 5 "Reserved" 4 "Power down DC/DC Converter" 3 "Operate in boost mode" 2 "Operate in buck mode" 1 "Operate in standby mode" 0 "Disable" ;
VAL_ 2566866213 VCURequestsToTurnBTMOnOff 0 "BTM turn off" 1 "BTM turn on" 2 "Invalid" 3 "Invalid" ;
VAL_ 2566866213 CoolantTargetTemperature 255 "Invalid" ;
VAL_ 2566897978 BTMWorkPattern 0 "Shutdown Mode" 1 "Refrigeration Mode" 2 "Heating Mode" 3 "Water Cycle Mode" ;
VAL_ 2566897978 BatteryInletCoolantTemperature 255 "Invalid" ;
VAL_ 2566897978 OutletCoolantTemperatureFromBatt 255 "Invalid" ;
VAL_ 2566897978 FaultGrade 0 "No Fault" 1 "Fault Level 1" 2 "Fault Level 2" 3 "Fault Level 3" ;
VAL_ 2566897978 FaultCode 1 "VCU Communication Failure (cannot receive VCU massage)" 5 "Low Voltage Undervoltage Failt" 7 "Low Voltage Overvoltage Fault" 9 "Low Pressure Fault" 11 "Hight Pressure Fault" 13 "Precharging Fault" 15 "PTC over temperature alarm (heating only)" 21 "Compressor Communication Fault" 23 "Cooling Compressor Undervoltage Fault" 25 "Cooling Compressor Overvoltage Fault" 27 "Exhaust Overtemperature Alarm" 31 "Pump Fault" 33 "Outdoor Environment Sensor Failure" 37 "Return Water Temperature Sensor Failure" 39 "Battery Inlet Water Temperature Sensor Failure" 41 "PTC IGBT Breakdown" 43 "PTC Communication Failure (heating only)" 45 "PTC High Voktage Undervoltage Fault (heating only)" 47 "PTC High Voktage Overvoltage Fault (heating only)" 49 "PTC Failure (heating only)" ;
